VERSION "HNNBNNNYNNNNNNNNNNNNNNNNNNNNNNNNNNNNNNNNNN/4/%%%/4/'%**4NNN///"

NS_ :

BS_:

BU_: BAP_Tester CGS Gateway Gateway_PAG HUD Kombi Kombi_LB Kombi_PAG Waehlhebel_SB

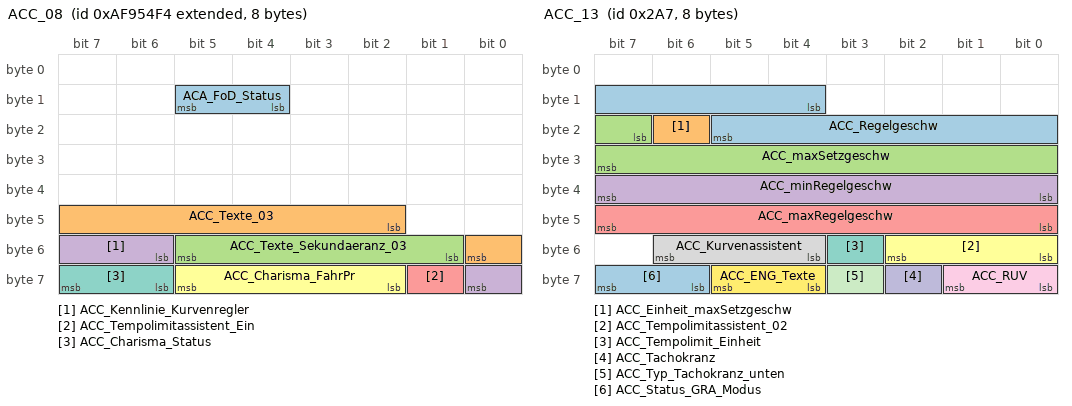
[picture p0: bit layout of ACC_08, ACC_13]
BO_ 2331596020 ACC_08: 8 Gateway
 SG_ ACA_FoD_Status : 12|2@1+ (1.0,0.0) [0.0|3] ""  Vector__XXX
 SG_ ACC_Texte_03 : 42|7@1+ (1.0,0.0) [0.0|127] ""  Kombi,Kombi_LB
 SG_ ACC_Texte_Sekundaeranz_03 : 49|5@1+ (1.0,0.0) [0.0|31] ""  Kombi,Kombi_LB
 SG_ ACC_Kennlinie_Kurvenregler : 54|3@1+ (1.0,0.0) [0.0|7] ""  Vector__XXX
 SG_ ACC_Tempolimitassistent_Ein : 57|1@1+ (1.0,0.0) [0.0|1] ""  Vector__XXX
 SG_ ACC_Charisma_FahrPr : 58|4@1+ (1.0,0.0) [0.0|15] ""  Vector__XXX
 SG_ ACC_Charisma_Status : 62|2@1+ (1.0,0.0) [0.0|3] ""  Vector__XXX

BO_ 678 ACC_12: 8 Gateway
 SG_ ACC_Tempolimit : 0|5@1+ (1.0,0.0) [0.0|31] ""  HUD,Kombi,Kombi_LB,Kombi_PAG
 SG_ ACC_Wunschgeschw_Farbe : 5|1@1+ (1.0,0.0) [0.0|1] ""  Kombi,Kombi_LB,Kombi_PAG
 SG_ ACC_Warnung_Verkehrszeichen_1 : 6|1@1+ (1.0,0.0) [0.0|1] ""  HUD,Kombi,Kombi_LB,Kombi_PAG
 SG_ ACA_Querfuehrung : 7|2@1+ (1.0,0.0) [0.0|3] ""  HUD,Kombi,Kombi_LB,Kombi_PAG
 SG_ ACC_Regelung_AIO : 11|1@1+ (1.0,0.0) [0.0|1] ""  HUD,Kombi,Kombi_LB
 SG_ ACC_Wunschgeschw_02 : 12|10@1+ (0.32,0) [0.00|327.04] "Unit_KiloMeterPerHour"  HUD,Kombi,Kombi_LB,Kombi_PAG
 SG_ ACC_Abstandsindex_02 : 22|10@1+ (1,0) [1|1021] ""  HUD,Kombi,Kombi_LB,Kombi_PAG
 SG_ ACC_Display_Prio : 32|2@1+ (1.0,0.0) [0.0|3] ""  Kombi,Kombi_LB,Kombi_PAG
 SG_ ACC_rel_Objekt_Zusatzanz : 34|2@1+ (1.0,0.0) [0.0|3] ""  Kombi,Kombi_LB,Kombi_PAG
 SG_ ACC_Gesetzte_Zeitluecke : 37|3@1+ (1.0,0.0) [0.0|7] ""  HUD,Kombi,Kombi_LB,Kombi_PAG
 SG_ ACC_Optischer_Fahrerhinweis : 40|1@1+ (1.0,0.0) [0.0|1] ""  HUD,Kombi,Kombi_LB,Kombi_PAG
 SG_ ACC_Warnhinweis : 41|1@1+ (1.0,0.0) [0.0|1] ""  HUD,Kombi,Kombi_LB
 SG_ ACC_EGO_Fahrzeug : 42|3@1+ (1.0,0.0) [0.0|7] ""  HUD,Kombi,Kombi_LB,Kombi_PAG
 SG_ ACC_Relevantes_Objekt_02 : 45|2@1+ (1.0,0.0) [0.0|3] ""  HUD,Kombi,Kombi_LB,Kombi_PAG
 SG_ ACC_Wunschgeschw_erreicht : 48|1@1+ (1.0,0.0) [0.0|1] ""  HUD,Kombi,Kombi_LB,Kombi_PAG
 SG_ ACC_Anzeige_Zeitluecke : 49|1@1+ (1.0,0.0) [0.0|1] ""  HUD,Kombi,Kombi_LB,Kombi_PAG
 SG_ ACC_Texte_Primaeranz_02 : 50|6@1+ (1.0,0.0) [0.0|63] ""  HUD,Kombi,Kombi_LB,Kombi_PAG
 SG_ ACC_Texte_Zusatzanz_02 : 56|6@1+ (1.0,0.0) [0.0|63] ""  HUD,Kombi,Kombi_LB,Kombi_PAG
 SG_ STA_Primaeranz : 62|2@1+ (1.0,0.0) [0.0|3] ""  HUD,Kombi,Kombi_LB,Kombi_PAG

BO_ 679 ACC_13: 8 Gateway
 SG_ ACC_Regelgeschw : 12|10@1+ (0.32,0) [0.00|327.04] "Unit_KiloMeterPerHour"  HUD,Kombi,Kombi_LB,Kombi_PAG
 SG_ ACC_Einheit_maxSetzgeschw : 22|1@1+ (1.0,0.0) [0.0|1] ""  Kombi,Kombi_LB,Kombi_PAG
 SG_ ACC_maxSetzgeschw : 23|9@1+ (1,0) [0|510] ""  Kombi,Kombi_LB,Kombi_PAG
 SG_ ACC_minRegelgeschw : 32|8@1+ (0.32,0) [0.00|81.28] "Unit_KiloMeterPerHour"  Kombi,Kombi_LB,Kombi_PAG
 SG_ ACC_maxRegelgeschw : 40|8@1+ (0.32,0) [0.00|81.28] "Unit_KiloMeterPerHour"  Kombi,Kombi_LB,Kombi_PAG
 SG_ ACC_Tempolimitassistent_02 : 48|3@1+ (1.0,0.0) [0.0|7] ""  HUD,Kombi,Kombi_LB,Kombi_PAG
 SG_ ACC_Tempolimit_Einheit : 51|1@1+ (1.0,0.0) [0.0|1] ""  HUD,Kombi,Kombi_LB
 SG_ ACC_Kurvenassistent : 52|3@1+ (1.0,0.0) [0.0|7] ""  HUD,Kombi,Kombi_LB,Kombi_PAG
 SG_ ACC_RUV : 56|2@1+ (1.0,0.0) [0.0|3] ""  HUD,Kombi,Kombi_LB,Kombi_PAG
 SG_ ACC_Tachokranz : 58|1@1+ (1.0,0.0) [0.0|1] ""  Kombi,Kombi_LB,Kombi_PAG
 SG_ ACC_Typ_Tachokranz_unten : 59|1@1+ (1.0,0.0) [0.0|1] ""  Kombi,Kombi_LB,Kombi_PAG
 SG_ ACC_ENG_Texte : 60|2@1+ (1.0,0.0) [0.0|3] ""  Kombi,Kombi_LB,Kombi_PAG
 SG_ ACC_Status_GRA_Modus : 62|2@1+ (1.0,0.0) [0.0|3] ""  Vector__XXX

BO_ 680 ACC_14: 8 Gateway
 SG_ ACA_Querfuehrung_Texte : 0|3@1+ (1.0,0.0) [0.0|7] ""  HUD,Kombi,Kombi_LB,Kombi_PAG
 SG_ ACA_Hinweistexte : 3|3@1+ (1.0,0.0) [0.0|7] ""  Kombi,Kombi_LB,Kombi_PAG
 SG_ ACC_FoD_Status : 6|2@1+ (1.0,0.0) [0.0|3] ""  Vector__XXX
 SG_ ACC_Texte_Abstandswarner : 8|2@1+ (1.0,0.0) [0.0|3] ""  Kombi,Kombi_LB,Kombi_PAG
 SG_ ACC_Vorz_Abstandswarner : 10|2@1+ (1.0,0.0) [0.0|3] ""  Kombi,Kombi_LB,Kombi_PAG
 SG_ ACC_Texte_Sekundaeranz : 12|4@1+ (1.0,0.0) [0.0|15] ""  Kombi,Kombi_LB,Kombi_PAG
 SG_ ACC_Status_Anzeige : 16|3@1+ (1.0,0.0) [0.0|7] ""  HUD,Kombi,Kombi_LB,Kombi_PAG
 SG_ ACC_Akustik_03 : 19|3@1+ (1.0,0.0) [0.0|7] ""  Kombi,Kombi_LB,Kombi_PAG
 SG_ ACC_Geschw_Zielfahrzeug : 22|10@1+ (0.32,0) [0.00|326.72] "Unit_KiloMeterPerHour"  Kombi,Kombi_LB,Kombi_PAG
 SG_ ACC_Texte : 32|5@1+ (1.0,0.0) [0.0|31] ""  Kombi,Kombi_LB,Kombi_PAG
 SG_ ACC_STA_Text : 38|1@1+ (1.0,0.0) [0.0|1] ""  Kombi,Kombi_LB,Kombi_PAG
 SG_ STA_Texte : 40|3@1+ (1.0,0.0) [0.0|7] ""  HUD,Kombi,Kombi_LB,Kombi_PAG
 SG_ AbstWarn_LRR_FAS_Fkt_Status : 43|2@1+ (1.0,0.0) [0.0|3] ""  Vector__XXX
 SG_ STA_Zusatzanz : 45|2@1+ (1.0,0.0) [0.0|3] ""  Kombi,Kombi_LB,Kombi_PAG
 SG_ FAS_Licht_Anf : 47|1@1+ (1.0,0.0) [0.0|1] ""  Vector__XXX
 SG_ ACC_Zeitluecke_Abstandswarner : 48|6@1+ (0.1,0) [0.0|6.0] "Unit_Secon"  Kombi,Kombi_LB,Kombi_PAG
 SG_ ACC_Abstand_Abstandswarner : 54|9@1+ (1,0) [0|508] ""  Kombi,Kombi_LB,Kombi_PAG
 SG_ ACC_Einheit_Abstandswarner : 63|1@1+ (1.0,0.0) [0.0|1] ""  Kombi,Kombi_LB,Kombi_PAG

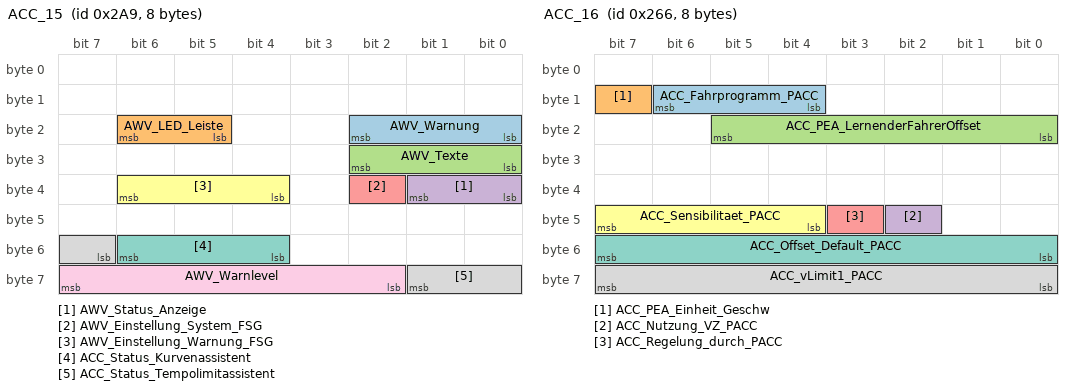
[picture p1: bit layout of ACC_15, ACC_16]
BO_ 681 ACC_15: 8 Gateway
 SG_ AWV_Warnung : 16|3@1+ (1.0,0.0) [0.0|7] ""  HUD,Kombi,Kombi_LB,Kombi_PAG
 SG_ AWV_LED_Leiste : 21|2@1+ (1.0,0.0) [0.0|3] ""  HUD,Kombi,Kombi_LB,Kombi_PAG
 SG_ AWV_Texte : 24|3@1+ (1.0,0.0) [0.0|7] ""  Kombi,Kombi_LB,Kombi_PAG
 SG_ AWV_Status_Anzeige : 32|2@1+ (1.0,0.0) [0.0|3] ""  Vector__XXX
 SG_ AWV_Einstellung_System_FSG : 34|1@1+ (1.0,0.0) [0.0|1] ""  Vector__XXX
 SG_ AWV_Einstellung_Warnung_FSG : 36|3@1+ (1.0,0.0) [0.0|7] ""  Vector__XXX
 SG_ ACC_Status_Kurvenassistent : 52|3@1+ (1.0,0.0) [0.0|7] ""  Vector__XXX
 SG_ ACC_Status_Tempolimitassistent : 55|3@1+ (1.0,0.0) [0.0|7] ""  Vector__XXX
 SG_ AWV_Warnlevel : 58|6@1+ (1.0,0.0) [0.0|63] ""  Vector__XXX

BO_ 614 ACC_16: 8 Gateway
 SG_ ACC_Fahrprogramm_PACC : 12|3@1+ (1.0,0.0) [0.0|7] ""  Vector__XXX
 SG_ ACC_PEA_Einheit_Geschw : 15|1@1+ (1.0,0.0) [0.0|1] ""  Vector__XXX
 SG_ ACC_PEA_LernenderFahrerOffset : 16|6@1+ (1,-31) [-30|31] ""  Vector__XXX
 SG_ ACC_Nutzung_VZ_PACC : 42|1@1+ (1.0,0.0) [0.0|1] ""  HUD
 SG_ ACC_Regelung_durch_PACC : 43|1@1+ (1.0,0.0) [0.0|1] ""  Vector__XXX
 SG_ ACC_Sensibilitaet_PACC : 44|4@1+ (1.0,0.0) [0.0|15] ""  Vector__XXX
 SG_ ACC_Offset_Default_PACC : 48|8@1+ (1,-127) [-127|128] "Unit_KiloMeterPerHour"  Vector__XXX
 SG_ ACC_vLimit1_PACC : 56|8@1+ (1,0) [0|255] "Unit_KiloMeterPerHour"  Vector__XXX

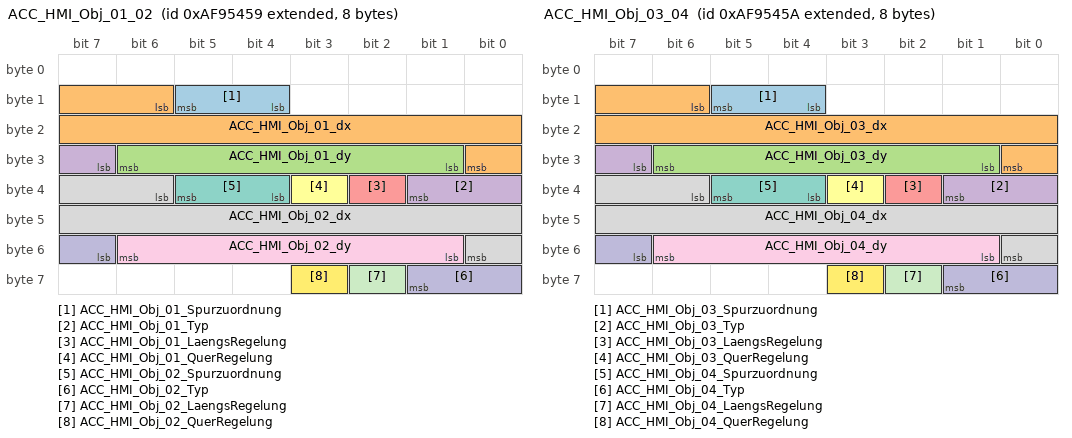
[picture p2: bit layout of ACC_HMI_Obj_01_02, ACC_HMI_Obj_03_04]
BO_ 2331595865 ACC_HMI_Obj_01_02: 8 Gateway
 SG_ ACC_HMI_Obj_01_Spurzuordnung : 12|2@1+ (1.0,0.0) [0.0|3] ""  HUD,Kombi,Kombi_PAG
 SG_ ACC_HMI_Obj_01_dx : 14|11@1+ (0.15,-100.05) [-100.05|207.00] "Unit_Meter"  HUD,Kombi,Kombi_PAG
 SG_ ACC_HMI_Obj_01_dy : 25|6@1+ (0.015873,0) [0.000000|0.999999] "Unit_PerCent"  Kombi,Kombi_PAG
 SG_ ACC_HMI_Obj_01_Typ : 31|3@1+ (1.0,0.0) [0.0|7] ""  HUD,Kombi,Kombi_PAG
 SG_ ACC_HMI_Obj_01_LaengsRegelung : 34|1@1+ (1.0,0.0) [0.0|1] ""  Kombi,Kombi_PAG
 SG_ ACC_HMI_Obj_01_QuerRegelung : 35|1@1+ (1.0,0.0) [0.0|1] ""  Kombi,Kombi_PAG
 SG_ ACC_HMI_Obj_02_Spurzuordnung : 36|2@1+ (1.0,0.0) [0.0|3] ""  HUD,Kombi,Kombi_PAG
 SG_ ACC_HMI_Obj_02_dx : 38|11@1+ (0.15,-100.05) [-100.05|207.00] "Unit_Meter"  HUD,Kombi,Kombi_PAG
 SG_ ACC_HMI_Obj_02_dy : 49|6@1+ (0.015873,0) [0.000000|0.999999] "Unit_PerCent"  Kombi,Kombi_PAG
 SG_ ACC_HMI_Obj_02_Typ : 55|3@1+ (1.0,0.0) [0.0|7] ""  HUD,Kombi,Kombi_PAG
 SG_ ACC_HMI_Obj_02_LaengsRegelung : 58|1@1+ (1.0,0.0) [0.0|1] ""  Kombi,Kombi_PAG
 SG_ ACC_HMI_Obj_02_QuerRegelung : 59|1@1+ (1.0,0.0) [0.0|1] ""  Kombi,Kombi_PAG

BO_ 2331595866 ACC_HMI_Obj_03_04: 8 Gateway
 SG_ ACC_HMI_Obj_03_Spurzuordnung : 12|2@1+ (1.0,0.0) [0.0|3] ""  HUD,Kombi,Kombi_PAG
 SG_ ACC_HMI_Obj_03_dx : 14|11@1+ (0.15,-100.05) [-100.05|207.00] "Unit_Meter"  HUD,Kombi,Kombi_PAG
 SG_ ACC_HMI_Obj_03_dy : 25|6@1+ (0.015873,0) [0.000000|0.999999] "Unit_PerCent"  Kombi,Kombi_PAG
 SG_ ACC_HMI_Obj_03_Typ : 31|3@1+ (1.0,0.0) [0.0|7] ""  HUD,Kombi,Kombi_PAG
 SG_ ACC_HMI_Obj_03_LaengsRegelung : 34|1@1+ (1.0,0.0) [0.0|1] ""  Kombi,Kombi_PAG
 SG_ ACC_HMI_Obj_03_QuerRegelung : 35|1@1+ (1.0,0.0) [0.0|1] ""  Kombi,Kombi_PAG
 SG_ ACC_HMI_Obj_04_Spurzuordnung : 36|2@1+ (1.0,0.0) [0.0|3] ""  HUD,Kombi,Kombi_PAG
 SG_ ACC_HMI_Obj_04_dx : 38|11@1+ (0.15,-100.05) [-100.05|207.00] "Unit_Meter"  HUD,Kombi,Kombi_PAG
 SG_ ACC_HMI_Obj_04_dy : 49|6@1+ (0.015873,0) [0.000000|0.999999] "Unit_PerCent"  Kombi,Kombi_PAG
 SG_ ACC_HMI_Obj_04_Typ : 55|3@1+ (1.0,0.0) [0.0|7] ""  HUD,Kombi,Kombi_PAG
 SG_ ACC_HMI_Obj_04_LaengsRegelung : 58|1@1+ (1.0,0.0) [0.0|1] ""  Kombi,Kombi_PAG
 SG_ ACC_HMI_Obj_04_QuerRegelung : 59|1@1+ (1.0,0.0) [0.0|1] ""  Kombi,Kombi_PAG

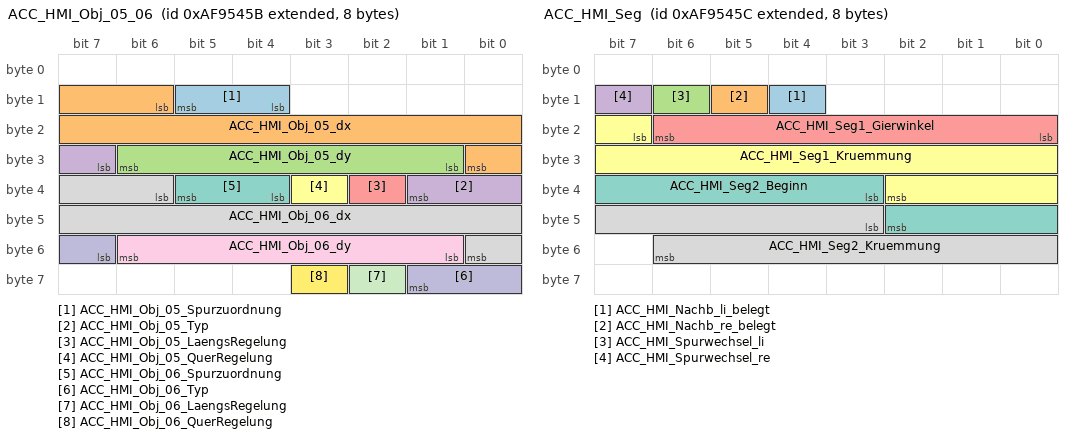
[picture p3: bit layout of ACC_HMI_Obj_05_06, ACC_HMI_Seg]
BO_ 2331595867 ACC_HMI_Obj_05_06: 8 Gateway
 SG_ ACC_HMI_Obj_05_Spurzuordnung : 12|2@1+ (1.0,0.0) [0.0|3] ""  HUD,Kombi,Kombi_PAG
 SG_ ACC_HMI_Obj_05_dx : 14|11@1+ (0.15,-100.05) [-100.05|207.00] "Unit_Meter"  HUD,Kombi,Kombi_PAG
 SG_ ACC_HMI_Obj_05_dy : 25|6@1+ (0.015873,0) [0.000000|0.999999] "Unit_PerCent"  Kombi,Kombi_PAG
 SG_ ACC_HMI_Obj_05_Typ : 31|3@1+ (1.0,0.0) [0.0|7] ""  HUD,Kombi,Kombi_PAG
 SG_ ACC_HMI_Obj_05_LaengsRegelung : 34|1@1+ (1.0,0.0) [0.0|1] ""  Kombi,Kombi_PAG
 SG_ ACC_HMI_Obj_05_QuerRegelung : 35|1@1+ (1.0,0.0) [0.0|1] ""  Kombi,Kombi_PAG
 SG_ ACC_HMI_Obj_06_Spurzuordnung : 36|2@1+ (1.0,0.0) [0.0|3] ""  HUD,Kombi,Kombi_PAG
 SG_ ACC_HMI_Obj_06_dx : 38|11@1+ (0.15,-100.05) [-100.05|207.00] "Unit_Meter"  HUD,Kombi,Kombi_PAG
 SG_ ACC_HMI_Obj_06_dy : 49|6@1+ (0.015873,0) [0.000000|0.999999] "Unit_PerCent"  Kombi,Kombi_PAG
 SG_ ACC_HMI_Obj_06_Typ : 55|3@1+ (1.0,0.0) [0.0|7] ""  HUD,Kombi,Kombi_PAG
 SG_ ACC_HMI_Obj_06_LaengsRegelung : 58|1@1+ (1.0,0.0) [0.0|1] ""  Kombi,Kombi_PAG
 SG_ ACC_HMI_Obj_06_QuerRegelung : 59|1@1+ (1.0,0.0) [0.0|1] ""  Kombi,Kombi_PAG

BO_ 2331595868 ACC_HMI_Seg: 8 Gateway
 SG_ ACC_HMI_Nachb_li_belegt : 12|1@1+ (1.0,0.0) [0.0|1] ""  Kombi,Kombi_PAG
 SG_ ACC_HMI_Nachb_re_belegt : 13|1@1+ (1.0,0.0) [0.0|1] ""  Kombi,Kombi_PAG
 SG_ ACC_HMI_Spurwechsel_li : 14|1@1+ (1.0,0.0) [0.0|1] ""  Kombi,Kombi_PAG
 SG_ ACC_HMI_Spurwechsel_re : 15|1@1+ (1.0,0.0) [0.0|1] ""  Kombi,Kombi_PAG
 SG_ ACC_HMI_Seg1_Gierwinkel : 16|7@1+ (0.015748,-1) [-1.000000|0.999996] "Unit_Radia"  Kombi,Kombi_PAG
 SG_ ACC_HMI_Seg1_Kruemmung : 23|12@1+ (1,-2047) [-2047|2048] "Unit_MeterInver"  Kombi,Kombi_PAG
 SG_ ACC_HMI_Seg2_Beginn : 35|8@1+ (0.58824,0) [0.00000|150.00120] "Unit_Meter"  Kombi,Kombi_PAG
 SG_ ACC_HMI_Seg2_Kruemmung : 43|12@1+ (1,-2047) [-2047|2048] "Unit_MeterInver"  Kombi,Kombi_PAG

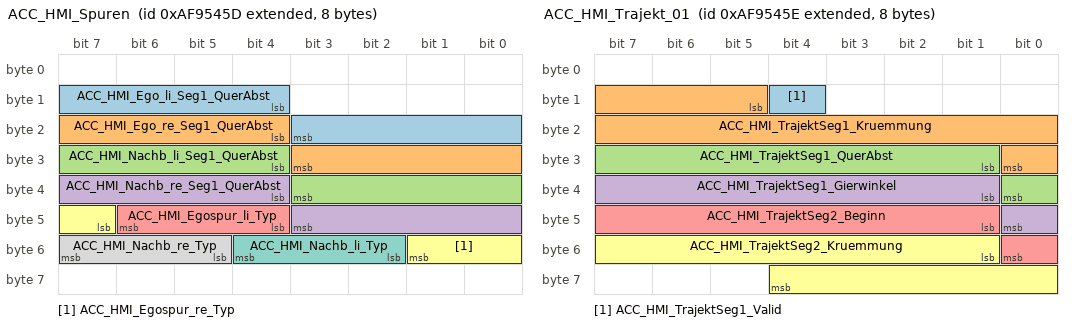
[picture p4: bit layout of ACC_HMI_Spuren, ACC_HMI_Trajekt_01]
BO_ 2331595869 ACC_HMI_Spuren: 8 Gateway
 SG_ ACC_HMI_Ego_li_Seg1_QuerAbst : 12|8@1+ (0.062745,-8) [-8.000000|7.999975] "Unit_Meter"  Kombi,Kombi_PAG
 SG_ ACC_HMI_Ego_re_Seg1_QuerAbst : 20|8@1+ (0.062745,-8) [-8.000000|7.999975] "Unit_Meter"  Kombi,Kombi_PAG
 SG_ ACC_HMI_Nachb_li_Seg1_QuerAbst : 28|8@1+ (0.062745,-8) [-8.000000|7.999975] "Unit_Meter"  Kombi,Kombi_PAG
 SG_ ACC_HMI_Nachb_re_Seg1_QuerAbst : 36|8@1+ (0.062745,-8) [-8.000000|7.999975] "Unit_Meter"  Kombi,Kombi_PAG
 SG_ ACC_HMI_Egospur_li_Typ : 44|3@1+ (1.0,0.0) [0.0|7] ""  Kombi,Kombi_PAG
 SG_ ACC_HMI_Egospur_re_Typ : 47|3@1+ (1.0,0.0) [0.0|7] ""  Kombi,Kombi_PAG
 SG_ ACC_HMI_Nachb_li_Typ : 50|3@1+ (1.0,0.0) [0.0|7] ""  Kombi,Kombi_PAG
 SG_ ACC_HMI_Nachb_re_Typ : 53|3@1+ (1.0,0.0) [0.0|7] ""  Kombi,Kombi_PAG

BO_ 2331595870 ACC_HMI_Trajekt_01: 8 Gateway
 SG_ ACC_HMI_TrajektSeg1_Valid : 12|1@1+ (1.0,0.0) [0.0|1] ""  Kombi,Kombi_PAG
 SG_ ACC_HMI_TrajektSeg1_Kruemmung : 13|12@1+ (1,-2047) [-2047|2048] "Unit_MeterInver"  Kombi,Kombi_PAG
 SG_ ACC_HMI_TrajektSeg1_QuerAbst : 25|8@1+ (0.062745,-8) [-8.000000|7.999975] "Unit_Meter"  Kombi,Kombi_PAG
 SG_ ACC_HMI_TrajektSeg1_Gierwinkel : 33|8@1+ (0.007843,-1) [-1.000000|0.999965] "Unit_Radia"  Kombi,Kombi_PAG
 SG_ ACC_HMI_TrajektSeg2_Beginn : 41|8@1+ (0.58824,0) [0.00000|150.00120] "Unit_Meter"  Kombi,Kombi_PAG
 SG_ ACC_HMI_TrajektSeg2_Kruemmung : 49|12@1+ (1,-2047) [-2047|2048] "Unit_MeterInver"  Kombi,Kombi_PAG

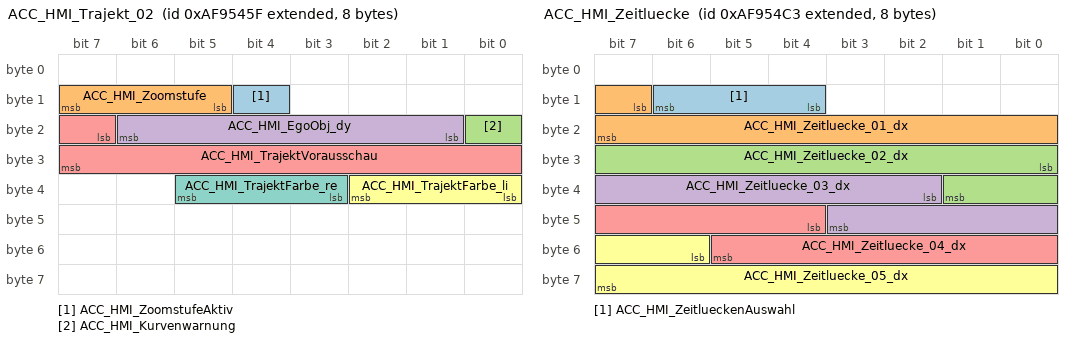
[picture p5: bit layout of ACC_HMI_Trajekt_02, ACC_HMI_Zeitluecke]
BO_ 2331595871 ACC_HMI_Trajekt_02: 8 Gateway
 SG_ ACC_HMI_ZoomstufeAktiv : 12|1@1+ (1.0,0.0) [0.0|1] ""  Kombi,Kombi_PAG
 SG_ ACC_HMI_Zoomstufe : 13|3@1+ (1,0) [0|7] "Unit_Meter"  Kombi,Kombi_PAG
 SG_ ACC_HMI_Kurvenwarnung : 16|1@1+ (1.0,0.0) [0.0|1] ""  Kombi,Kombi_PAG
 SG_ ACC_HMI_EgoObj_dy : 17|6@1+ (0.015873,0) [0.000000|0.999999] "Unit_PerCent"  Kombi,Kombi_PAG
 SG_ ACC_HMI_TrajektVorausschau : 23|9@1+ (0.58824,0) [0.00000|300.59064] "Unit_Meter"  Kombi,Kombi_PAG
 SG_ ACC_HMI_TrajektFarbe_li : 32|3@1+ (1.0,0.0) [0.0|7] ""  Kombi,Kombi_PAG
 SG_ ACC_HMI_TrajektFarbe_re : 35|3@1+ (1.0,0.0) [0.0|7] ""  Kombi,Kombi_PAG

BO_ 2331595971 ACC_HMI_Zeitluecke: 8 Gateway
 SG_ ACC_HMI_ZeitlueckenAuswahl : 12|3@1+ (1.0,0.0) [0.0|7] ""  Kombi,Kombi_PAG
 SG_ ACC_HMI_Zeitluecke_01_dx : 15|9@1+ (0.15,0) [0.00|76.65] "Unit_Meter"  Kombi,Kombi_PAG
 SG_ ACC_HMI_Zeitluecke_02_dx : 24|10@1+ (0.15,0) [0.00|153.45] "Unit_Meter"  Kombi,Kombi_PAG
 SG_ ACC_HMI_Zeitluecke_03_dx : 34|10@1+ (0.15,0) [0.00|153.45] "Unit_Meter"  Kombi,Kombi_PAG
 SG_ ACC_HMI_Zeitluecke_04_dx : 44|10@1+ (0.15,0) [0.00|153.45] "Unit_Meter"  Kombi,Kombi_PAG
 SG_ ACC_HMI_Zeitluecke_05_dx : 54|10@1+ (0.15,0) [0.00|153.45] "Unit_Meter"  Kombi,Kombi_PAG

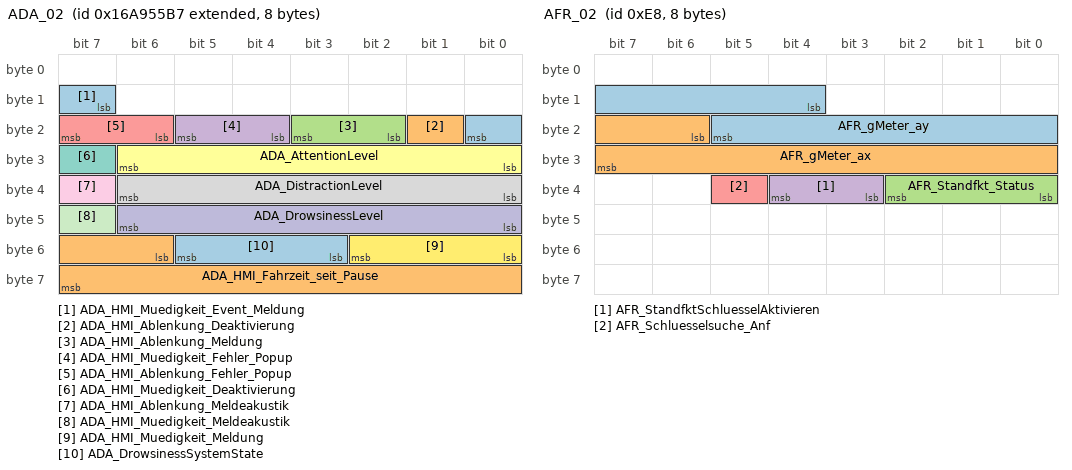
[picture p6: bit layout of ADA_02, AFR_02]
BO_ 2527679927 ADA_02: 8 Gateway
 SG_ ADA_HMI_Muedigkeit_Event_Meldung : 15|2@1+ (1.0,0.0) [0.0|3] ""  Kombi,Kombi_LB
 SG_ ADA_HMI_Ablenkung_Deaktivierung : 17|1@1+ (1.0,0.0) [0.0|1] ""  Kombi,Kombi_LB,Kombi_PAG
 SG_ ADA_HMI_Ablenkung_Meldung : 18|2@1+ (1.0,0.0) [0.0|3] ""  Kombi,Kombi_LB,Kombi_PAG
 SG_ ADA_HMI_Muedigkeit_Fehler_Popup : 20|2@1+ (1.0,0.0) [0.0|3] ""  Kombi,Kombi_LB,Kombi_PAG
 SG_ ADA_HMI_Ablenkung_Fehler_Popup : 22|2@1+ (1.0,0.0) [0.0|3] ""  Kombi,Kombi_LB,Kombi_PAG
 SG_ ADA_AttentionLevel : 24|7@1+ (0.01,0) [0.00|1.00] "Unit_None"  Vector__XXX
 SG_ ADA_HMI_Muedigkeit_Deaktivierung : 31|1@1+ (1.0,0.0) [0.0|1] ""  Kombi,Kombi_LB,Kombi_PAG
 SG_ ADA_DistractionLevel : 32|7@1+ (0.01,0) [0.00|1.00] "Unit_None"  Vector__XXX
 SG_ ADA_HMI_Ablenkung_Meldeakustik : 39|1@1+ (1.0,0.0) [0.0|1] ""  Kombi,Kombi_LB,Kombi_PAG
 SG_ ADA_DrowsinessLevel : 40|7@1+ (0.01,0) [0.00|1.00] "Unit_None"  Vector__XXX
 SG_ ADA_HMI_Muedigkeit_Meldeakustik : 47|1@1+ (1.0,0.0) [0.0|1] ""  Kombi,Kombi_LB,Kombi_PAG
 SG_ ADA_HMI_Muedigkeit_Meldung : 48|3@1+ (1.0,0.0) [0.0|7] ""  Kombi,Kombi_LB,Kombi_PAG
 SG_ ADA_DrowsinessSystemState : 51|3@1+ (1.0,0.0) [0.0|7] ""  Kombi,Kombi_LB,Kombi_PAG
 SG_ ADA_HMI_Fahrzeit_seit_Pause : 54|10@1+ (1,0) [0|1022] "Unit_Minut"  Kombi,Kombi_LB,Kombi_PAG

BO_ 232 AFR_02: 8 Gateway
 SG_ AFR_gMeter_ay : 12|10@1+ (0.003,-1.5) [-1.500|1.563] "Unit_ForceOfGravi"  Kombi,Kombi_LB
 SG_ AFR_gMeter_ax : 22|10@1+ (0.003,-1.5) [-1.500|1.563] "Unit_ForceOfGravi"  Kombi,Kombi_LB
 SG_ AFR_Standfkt_Status : 32|3@1+ (1.0,0.0) [0.0|7] ""  Vector__XXX
 SG_ AFR_StandfktSchluesselAktivieren : 35|2@1+ (1.0,0.0) [0.0|3] ""  Vector__XXX
 SG_ AFR_Schluesselsuche_Anf : 37|1@1+ (1.0,0.0) [0.0|1] ""  Vector__XXX

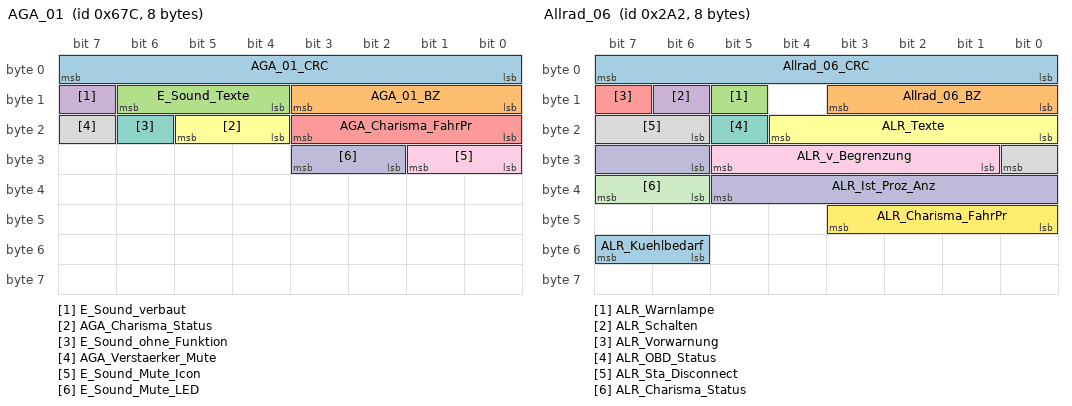
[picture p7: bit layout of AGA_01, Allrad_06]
BO_ 1660 AGA_01: 8 Gateway
 SG_ AGA_01_CRC : 0|8@1+ (1,0) [0|255] ""  Vector__XXX
 SG_ AGA_01_BZ : 8|4@1+ (1,0) [0|15] ""  Vector__XXX
 SG_ E_Sound_Texte : 12|3@1+ (1.0,0.0) [0.0|7] ""  Kombi,Kombi_LB,Kombi_PAG
 SG_ E_Sound_verbaut : 15|1@1+ (1.0,0.0) [0.0|1] ""  Kombi,Kombi_LB,Kombi_PAG
 SG_ AGA_Charisma_FahrPr : 16|4@1+ (1.0,0.0) [0.0|15] ""  Vector__XXX
 SG_ AGA_Charisma_Status : 20|2@1+ (1.0,0.0) [0.0|3] ""  Vector__XXX
 SG_ E_Sound_ohne_Funktion : 22|1@1+ (1.0,0.0) [0.0|1] ""  Kombi_PAG
 SG_ AGA_Verstaerker_Mute : 23|1@1+ (1.0,0.0) [0.0|1] ""  Vector__XXX
 SG_ E_Sound_Mute_Icon : 24|2@1+ (1.0,0.0) [0.0|3] ""  Kombi,Kombi_LB,Kombi_PAG
 SG_ E_Sound_Mute_LED : 26|2@1+ (1.0,0.0) [0.0|3] ""  Vector__XXX

BO_ 64 Airbag_01: 8 Gateway
 SG_ Airbag_01_CRC : 0|8@1+ (1,0) [0|255] ""  Kombi,Kombi_LB,Kombi_PAG
 SG_ Airbag_01_BZ : 8|4@1+ (1,0) [0|15] ""  Kombi,Kombi_LB,Kombi_PAG
 SG_ AB_RGS_Anst : 12|4@1+ (1.0,0.0) [0.0|15] ""  Vector__XXX
 SG_ AB_Front_Crash : 16|1@1+ (1.0,0.0) [0.0|1] ""  Vector__XXX
 SG_ AB_Heck_Crash : 17|1@1+ (1.0,0.0) [0.0|1] ""  Vector__XXX
 SG_ AB_SF_Crash : 18|1@1+ (1.0,0.0) [0.0|1] ""  Vector__XXX
 SG_ AB_SB_Crash : 19|1@1+ (1.0,0.0) [0.0|1] ""  Vector__XXX
 SG_ AB_Rollover_Crash : 20|1@1+ (1.0,0.0) [0.0|1] ""  Vector__XXX
 SG_ AB_Crash_Int : 21|3@1+ (1.0,0.0) [0.0|7] ""  Vector__XXX
 SG_ AB_Lampe : 24|1@1+ (1.0,0.0) [0.0|1] ""  Kombi,Kombi_LB,Kombi_PAG
 SG_ AB_Deaktiviert : 25|1@1+ (1.0,0.0) [0.0|1] ""  Kombi,Kombi_LB
 SG_ AB_VB_deaktiviert : 26|1@1+ (1.0,0.0) [0.0|1] ""  Kombi,Kombi_LB,Kombi_PAG
 SG_ AB_Systemfehler : 27|1@1+ (1.0,0.0) [0.0|1] ""  Kombi,Kombi_LB,Kombi_PAG
 SG_ AB_Diagnose : 28|1@1+ (1.0,0.0) [0.0|1] ""  Vector__XXX
 SG_ AB_Stellgliedtest : 29|1@1+ (1.0,0.0) [0.0|1] ""  Vector__XXX
 SG_ AB_Erh_Auf_VB : 30|2@1+ (1.0,0.0) [0.0|3] ""  Kombi,Kombi_LB,Kombi_PAG
 SG_ AB_Gurtwarn_VF : 32|1@1+ (1.0,0.0) [0.0|1] ""  Kombi,Kombi_LB,Kombi_PAG
 SG_ AB_Gurtwarn_VB : 33|1@1+ (1.0,0.0) [0.0|1] ""  Kombi,Kombi_LB,Kombi_PAG
 SG_ AB_Anzeige_Fussg : 34|2@1+ (1.0,0.0) [0.0|3] ""  Kombi,Kombi_LB,Kombi_PAG
 SG_ AB_Texte_AKS : 36|2@1+ (1.0,0.0) [0.0|3] ""  Kombi,Kombi_LB,Kombi_PAG
 SG_ AB_MKB_gueltig : 39|1@1+ (1.0,0.0) [0.0|1] ""  Vector__XXX
 SG_ AB_MKB_Anforderung : 40|1@1+ (1.0,0.0) [0.0|1] ""  Vector__XXX
 SG_ AB_Versorgungsspannung : 41|1@1+ (1.0,0.0) [0.0|1] ""  Kombi,Kombi_LB,Kombi_PAG
 SG_ AB_Deaktivierung_HV : 42|3@1+ (1.0,0.0) [0.0|7] ""  Vector__XXX
 SG_ AB_EDR_Trigger : 45|2@1+ (1.0,0.0) [0.0|3] ""  Vector__XXX
 SG_ AB_Belegung_VF : 47|2@1+ (1.0,0.0) [0.0|3] ""  Kombi,Kombi_LB
 SG_ SC_Masterzeit_Offset : 53|2@1+ (5.08,0) [0.00|15.24] "Unit_Secon"  Vector__XXX
 SG_ SC_LowSpeedCrashErkannt : 55|2@1+ (1.0,0.0) [0.0|3] ""  Vector__XXX
 SG_ SC_Masterzeit : 57|7@1+ (0.04,0) [0.00|5.04] "Unit_Secon"  Vector__XXX

BO_ 1312 Airbag_02: 8 Gateway
 SG_ Airbag_02_CRC : 0|8@1+ (1,0) [0|255] ""  Vector__XXX
 SG_ Airbag_02_BZ : 8|4@1+ (1,0) [0|15] ""  Vector__XXX
 SG_ LoGeWa_Event_Kombiwarnung : 12|4@1+ (1.0,0.0) [0.0|15] ""  HUD,Kombi,Kombi_LB,Kombi_PAG
 SG_ AB_Anforderung_eCall : 16|1@1+ (1.0,0.0) [0.0|1] ""  Vector__XXX
 SG_ AB_Anprall_Seite_Beifahrer : 17|1@1+ (1.0,0.0) [0.0|1] ""  Vector__XXX
 SG_ AB_Anprall_Rollover : 18|1@1+ (1.0,0.0) [0.0|1] ""  Vector__XXX
 SG_ AB_Anprall_FGS : 19|1@1+ (1.0,0.0) [0.0|1] ""  Vector__XXX
 SG_ AB_Anprall_Front_Beifahrer : 20|1@1+ (1.0,0.0) [0.0|1] ""  Vector__XXX
 SG_ AB_Anprall_Front_Fahrer : 21|1@1+ (1.0,0.0) [0.0|1] ""  Vector__XXX
 SG_ AB_Anprall_Heck_Beifahrer : 22|1@1+ (1.0,0.0) [0.0|1] ""  Vector__XXX
 SG_ AB_Anprall_Heck_Fahrer : 23|1@1+ (1.0,0.0) [0.0|1] ""  Vector__XXX
 SG_ AB_Wickelklappung_Reihe2_MI : 24|2@1+ (1.0,0.0) [0.0|3] ""  Kombi,Kombi_LB,Kombi_PAG
 SG_ AB_Belegung_VB : 26|2@1+ (1.0,0.0) [0.0|3] ""  Vector__XXX
 SG_ AB_Abschaltanf_SIH_BF : 28|1@1+ (1.0,0.0) [0.0|1] ""  Vector__XXX
 SG_ AB_Anprall_Seite_Fahrer : 29|1@1+ (1.0,0.0) [0.0|1] ""  Vector__XXX
 SG_ SC_PAO_Schriftzug_Anf : 30|2@1+ (1.0,0.0) [0.0|3] ""  Vector__XXX
 SG_ SC_PAO_ON_Anf : 32|2@1+ (1.0,0.0) [0.0|3] ""  Vector__XXX
 SG_ SC_PAO_OFF_Anf : 34|2@1+ (1.0,0.0) [0.0|3] ""  Vector__XXX
 SG_ AB_Crashschwere : 36|3@1+ (1.0,0.0) [0.0|7] ""  Vector__XXX
 SG_ AB_Anforderung_USM : 39|1@1+ (1.0,0.0) [0.0|1] ""  Vector__XXX
 SG_ AB_Gurtschloss_FA : 40|2@1+ (1.0,0.0) [0.0|3] ""  Kombi,Kombi_LB,Kombi_PAG
 SG_ AB_Gurtschloss_BF : 42|2@1+ (1.0,0.0) [0.0|3] ""  Kombi,Kombi_LB,Kombi_PAG
 SG_ AB_Gurtschloss_Reihe2_FA : 44|2@1+ (1.0,0.0) [0.0|3] ""  Kombi,Kombi_PAG
 SG_ AB_Gurtschloss_Reihe2_MI : 46|2@1+ (1.0,0.0) [0.0|3] ""  Kombi,Kombi_PAG
 SG_ AB_Gurtschloss_Reihe2_BF : 48|2@1+ (1.0,0.0) [0.0|3] ""  Kombi,Kombi_PAG
 SG_ AB_Gurtschloss_Reihe3_FA : 50|2@1+ (1.0,0.0) [0.0|3] ""  Kombi,Kombi_PAG
 SG_ AB_Gurtschloss_Reihe3_MI : 52|2@1+ (1.0,0.0) [0.0|3] ""  Kombi,Kombi_PAG
 SG_ AB_Gurtschloss_Reihe3_BF : 54|2@1+ (1.0,0.0) [0.0|3] ""  Kombi,Kombi_PAG
 SG_ AB_Sitzpos_Sens_FA : 56|2@1+ (1.0,0.0) [0.0|3] ""  Vector__XXX
 SG_ AB_Sitzpos_Sens_BF : 58|2@1+ (1.0,0.0) [0.0|3] ""  Vector__XXX
 SG_ AB_Wickelklappung_Reihe2_BF : 60|2@1+ (1.0,0.0) [0.0|3] ""  Kombi,Kombi_LB,Kombi_PAG
 SG_ AB_Wickelklappung_Reihe2_FA : 62|2@1+ (1.0,0.0) [0.0|3] ""  Kombi,Kombi_LB,Kombi_PAG

BO_ 1349 Airbag_04: 8 Gateway
 SG_ AB_Gurtwarn_Reihe2_FA : 20|2@1+ (1.0,0.0) [0.0|3] ""  Kombi
 SG_ AB_Gurtwarn_Reihe2_BF : 22|2@1+ (1.0,0.0) [0.0|3] ""  Kombi
 SG_ AbstWarn_MV_FAS_Fkt_Status : 24|2@1+ (1.0,0.0) [0.0|3] ""  Vector__XXX
 SG_ WarnBrems_Charisma_Status : 26|2@1+ (1.0,0.0) [0.0|3] ""  Vector__XXX
 SG_ WarnBrems_Charisma_FahrPr : 28|4@1+ (1.0,0.0) [0.0|15] ""  Vector__XXX
 SG_ AB_Gurtwarn_Reihe2_MI : 32|2@1+ (1.0,0.0) [0.0|3] ""  Kombi
 SG_ AB_Gurtwarn_Reihe3_FA : 34|2@1+ (1.0,0.0) [0.0|3] ""  Kombi
 SG_ AB_Gurtwarn_Reihe3_MI : 36|2@1+ (1.0,0.0) [0.0|3] ""  Kombi
 SG_ AB_Gurtwarn_Reihe3_BF : 38|2@1+ (1.0,0.0) [0.0|3] ""  Kombi
 SG_ LGI_FAS_Fkt_Status : 40|2@1+ (1.0,0.0) [0.0|3] ""  Vector__XXX
 SG_ PreCrash_FAS_Fkt_Status : 42|3@1+ (1.0,0.0) [0.0|7] ""  Vector__XXX
 SG_ AB_SBR_hinten_verbau : 48|2@1+ (1.0,0.0) [0.0|3] ""  Kombi,Kombi_LB
 SG_ AWV_Einstellung_System_ASG : 51|1@1+ (1.0,0.0) [0.0|1] ""  Vector__XXX
 SG_ AWV_Einstellung_Warnung_ASG : 52|3@1+ (1.0,0.0) [0.0|7] ""  Vector__XXX
 SG_ SC_PreSense_Modus_Warnung_NV : 55|3@1+ (1.0,0.0) [0.0|7] ""  Vector__XXX
 SG_ SC_PreSense_Modus_Warnung_MV : 58|3@1+ (1.0,0.0) [0.0|7] ""  Vector__XXX
 SG_ SC_PreSense_Modus_System_MV : 61|1@1+ (1.0,0.0) [0.0|1] ""  Vector__XXX
 SG_ SC_PreSense_Modus_System_NV : 62|1@1+ (1.0,0.0) [0.0|1] ""  Vector__XXX
 SG_ SC_PreSense_Modus_System_KAS : 63|1@1+ (1.0,0.0) [0.0|1] ""  Vector__XXX

BO_ 674 Allrad_06: 8 Gateway
 SG_ Allrad_06_CRC : 0|8@1+ (1,0) [0|255] ""  Kombi,Kombi_LB,Kombi_PAG
 SG_ Allrad_06_BZ : 8|4@1+ (1,0) [0|15] ""  Kombi,Kombi_LB,Kombi_PAG
 SG_ ALR_Warnlampe : 13|1@1+ (1.0,0.0) [0.0|1] ""  Kombi,Kombi_LB,Kombi_PAG
 SG_ ALR_Schalten : 14|1@1+ (1.0,0.0) [0.0|1] ""  Vector__XXX
 SG_ ALR_Vorwarnung : 15|1@1+ (1.0,0.0) [0.0|1] ""  Vector__XXX
 SG_ ALR_Texte : 16|5@1+ (1.0,0.0) [0.0|31] ""  Kombi,Kombi_LB,Kombi_PAG
 SG_ ALR_OBD_Status : 21|1@1+ (1.0,0.0) [0.0|1] ""  Vector__XXX
 SG_ ALR_Sta_Disconnect : 22|3@1+ (1.0,0.0) [0.0|7] ""  Vector__XXX
 SG_ ALR_v_Begrenzung : 25|5@1+ (10,10) [10|310] ""  Vector__XXX
 SG_ ALR_Ist_Proz_Anz : 30|8@1+ (0.4,0) [0.0|100.0] "Unit_PerCent"  Vector__XXX
 SG_ ALR_Charisma_Status : 38|2@1+ (1.0,0.0) [0.0|3] ""  Vector__XXX
 SG_ ALR_Charisma_FahrPr : 40|4@1+ (1.0,0.0) [0.0|15] ""  Vector__XXX
 SG_ ALR_Kuehlbedarf : 54|2@1+ (1.0,0.0) [0.0|3] ""  Vector__XXX

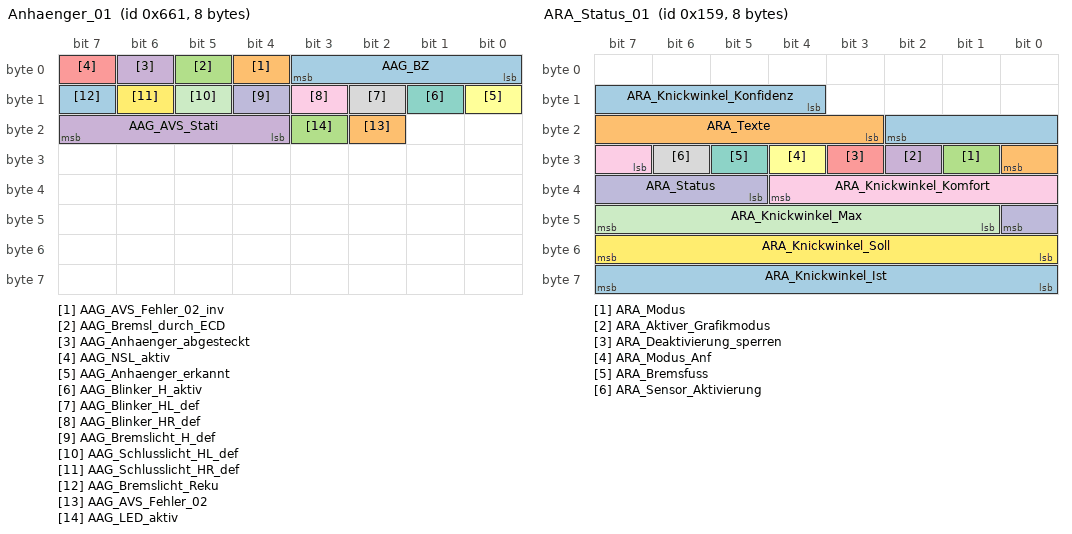
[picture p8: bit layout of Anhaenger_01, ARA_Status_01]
BO_ 1633 Anhaenger_01: 8 Gateway
 SG_ AAG_BZ : 0|4@1+ (1,0) [0|15] ""  Kombi,Kombi_PAG
 SG_ AAG_AVS_Fehler_02_inv : 4|1@1+ (1.0,0.0) [0.0|1] ""  Kombi,Kombi_PAG
 SG_ AAG_Bremsl_durch_ECD : 5|1@1+ (1.0,0.0) [0.0|1] ""  Vector__XXX
 SG_ AAG_Anhaenger_abgesteckt : 6|1@1+ (1.0,0.0) [0.0|1] ""  Vector__XXX
 SG_ AAG_NSL_aktiv : 7|1@1+ (1.0,0.0) [0.0|1] ""  Vector__XXX
 SG_ AAG_Anhaenger_erkannt : 8|1@1+ (1.0,0.0) [0.0|1] ""  Vector__XXX
 SG_ AAG_Blinker_H_aktiv : 9|1@1+ (1.0,0.0) [0.0|1] ""  Kombi,Kombi_PAG
 SG_ AAG_Blinker_HL_def : 10|1@1+ (1.0,0.0) [0.0|1] ""  Kombi,Kombi_PAG
 SG_ AAG_Blinker_HR_def : 11|1@1+ (1.0,0.0) [0.0|1] ""  Kombi,Kombi_PAG
 SG_ AAG_Bremslicht_H_def : 12|1@1+ (1.0,0.0) [0.0|1] ""  Kombi,Kombi_PAG
 SG_ AAG_Schlusslicht_HL_def : 13|1@1+ (1.0,0.0) [0.0|1] ""  Kombi,Kombi_PAG
 SG_ AAG_Schlusslicht_HR_def : 14|1@1+ (1.0,0.0) [0.0|1] ""  Kombi,Kombi_PAG
 SG_ AAG_Bremslicht_Reku : 15|1@1+ (1.0,0.0) [0.0|1] ""  Vector__XXX
 SG_ AAG_AVS_Fehler_02 : 18|1@1+ (1.0,0.0) [0.0|1] ""  Kombi,Kombi_PAG
 SG_ AAG_LED_aktiv : 19|1@1+ (1.0,0.0) [0.0|1] ""  Vector__XXX
 SG_ AAG_AVS_Stati : 20|4@1+ (1.0,0.0) [0.0|15] ""  Vector__XXX

BO_ 345 ARA_Status_01: 8 Gateway
 SG_ ARA_Knickwinkel_Konfidenz : 12|7@1+ (1,0) [0|120] "Unit_DegreOfArc"  Kombi,Kombi_PAG
 SG_ ARA_Texte : 19|6@1+ (1.0,0.0) [0.0|63] ""  Kombi,Kombi_PAG
 SG_ ARA_Modus : 25|1@1+ (1.0,0.0) [0.0|1] ""  Kombi,Kombi_PAG
 SG_ ARA_Aktiver_Grafikmodus : 26|1@1+ (1.0,0.0) [0.0|1] ""  Kombi,Kombi_PAG
 SG_ ARA_Deaktivierung_sperren : 27|1@1+ (1.0,0.0) [0.0|1] ""  Vector__XXX
 SG_ ARA_Modus_Anf : 28|1@1+ (1.0,0.0) [0.0|1] ""  Vector__XXX
 SG_ ARA_Bremsfuss : 29|1@1+ (1.0,0.0) [0.0|1] ""  Kombi,Kombi_PAG
 SG_ ARA_Sensor_Aktivierung : 30|1@1+ (1.0,0.0) [0.0|1] ""  Vector__XXX
 SG_ ARA_Knickwinkel_Komfort : 31|6@1+ (1,0) [0|60] "Unit_DegreOfArc"  Kombi,Kombi_LB,Kombi_PAG
 SG_ ARA_Status : 37|4@1+ (1.0,0.0) [0.0|15] ""  Vector__XXX
 SG_ ARA_Knickwinkel_Max : 41|7@1+ (1,0) [0|120] "Unit_DegreOfArc"  Kombi,Kombi_LB,Kombi_PAG
 SG_ ARA_Knickwinkel_Soll : 48|8@1+ (1,-125) [-125|126] "Unit_DegreOfArc"  Kombi,Kombi_LB,Kombi_PAG
 SG_ ARA_Knickwinkel_Ist : 56|8@1+ (1,-125) [-125|126] "Unit_DegreOfArc"  Kombi,Kombi_LB,Kombi_PAG

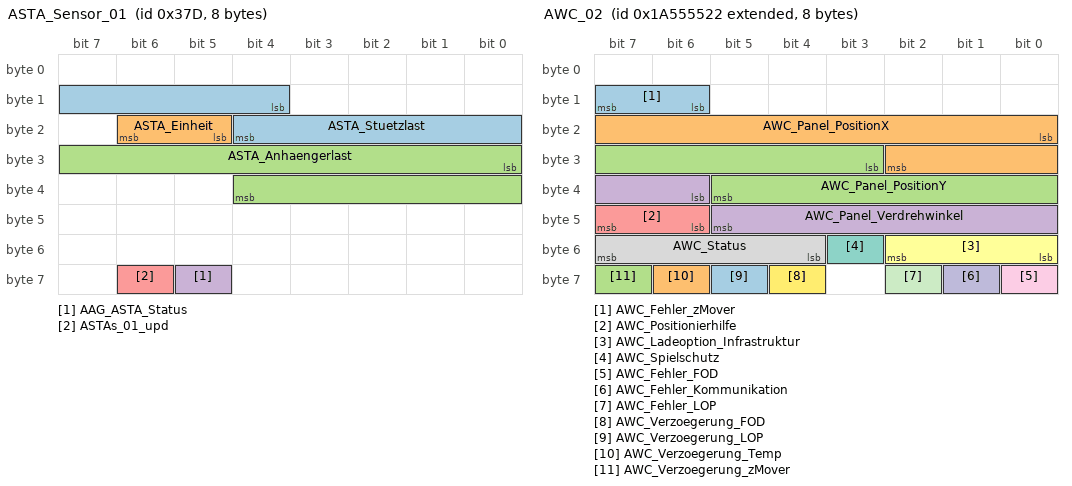
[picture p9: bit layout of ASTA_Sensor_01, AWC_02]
BO_ 893 ASTA_Sensor_01: 8 Gateway
 SG_ ASTA_Stuetzlast : 12|9@1+ (1,0) [0|300] "Unit_None"  Kombi
 SG_ ASTA_Einheit : 21|2@1+ (1.0,0.0) [0.0|3] ""  Kombi
 SG_ ASTA_Anhaengerlast : 24|13@1+ (1,0) [0|5000] "Unit_None"  Kombi
 SG_ AAG_ASTA_Status : 61|1@1+ (1.0,0.0) [0.0|1] ""  Kombi
 SG_ ASTAs_01_upd : 62|1@1+ (1.0,0.0) [0.0|1] ""  Kombi

BO_ 2589283618 AWC_02: 8 Gateway
 SG_ AWC_Fehler_zMover : 14|2@1+ (1.0,0.0) [0.0|3] ""  Vector__XXX
 SG_ AWC_Panel_PositionX : 16|11@1+ (1,-1000) [-1000|1000] "Unit_Centimeter"  Vector__XXX
 SG_ AWC_Panel_PositionY : 27|11@1+ (1,-1000) [-1000|1000] "Unit_Centimeter"  Vector__XXX
 SG_ AWC_Panel_Verdrehwinkel : 38|8@1+ (1.5,0) [0.0|360.0] "Unit_DegreOfArc"  Vector__XXX
 SG_ AWC_Positionierhilfe : 46|2@1+ (1.0,0.0) [0.0|3] ""  Vector__XXX
 SG_ AWC_Ladeoption_Infrastruktur : 48|3@1+ (1.0,0.0) [0.0|7] ""  Vector__XXX
 SG_ AWC_Spielschutz : 51|1@1+ (1.0,0.0) [0.0|1] ""  Vector__XXX
 SG_ AWC_Status : 52|4@1+ (1.0,0.0) [0.0|15] ""  Vector__XXX
 SG_ AWC_Fehler_FOD : 56|1@1+ (1.0,0.0) [0.0|1] ""  Vector__XXX
 SG_ AWC_Fehler_Kommunikation : 57|1@1+ (1.0,0.0) [0.0|1] ""  Vector__XXX
 SG_ AWC_Fehler_LOP : 58|1@1+ (1.0,0.0) [0.0|1] ""  Vector__XXX
 SG_ AWC_Verzoegerung_FOD : 60|1@1+ (1.0,0.0) [0.0|1] ""  Vector__XXX
 SG_ AWC_Verzoegerung_LOP : 61|1@1+ (1.0,0.0) [0.0|1] ""  Vector__XXX
 SG_ AWC_Verzoegerung_Temp : 62|1@1+ (1.0,0.0) [0.0|1] ""  Vector__XXX
 SG_ AWC_Verzoegerung_zMover : 63|1@1+ (1.0,0.0) [0.0|1] ""  Vector__XXX

BO_TX_BU_ 2331596020 :Gateway,Gateway_PAG;
BO_TX_BU_ 678 :Gateway,Gateway_PAG;
BO_TX_BU_ 679 :Gateway,Gateway_PAG;
BO_TX_BU_ 680 :Gateway,Gateway_PAG;
BO_TX_BU_ 681 :Gateway,Gateway_PAG;
BO_TX_BU_ 614 :Gateway,Gateway_PAG;
BO_TX_BU_ 2331595865 :Gateway,Gateway_PAG;
BO_TX_BU_ 2331595866 :Gateway,Gateway_PAG;
BO_TX_BU_ 2331595867 :Gateway,Gateway_PAG;
BO_TX_BU_ 2331595868 :Gateway,Gateway_PAG;
BO_TX_BU_ 2331595869 :Gateway,Gateway_PAG;
BO_TX_BU_ 2331595870 :Gateway,Gateway_PAG;
BO_TX_BU_ 2331595871 :Gateway,Gateway_PAG;
BO_TX_BU_ 2331595971 :Gateway,Gateway_PAG;
BO_TX_BU_ 2527679927 :Gateway,Gateway_PAG;
BO_TX_BU_ 232 :Gateway,Gateway_PAG;
BO_TX_BU_ 1660 :Gateway,Gateway_PAG;
BO_TX_BU_ 64 :Gateway,Gateway_PAG;
BO_TX_BU_ 1312 :Gateway,Gateway_PAG;
BO_TX_BU_ 1349 :Gateway,Gateway_PAG;
BO_TX_BU_ 674 :Gateway,Gateway_PAG;
BO_TX_BU_ 1633 :Gateway,Gateway_PAG;
BO_TX_BU_ 345 :Gateway,Gateway_PAG;
BO_TX_BU_ 893 :Gateway,Gateway_PAG;
BO_TX_BU_ 2589283618 :Gateway,Gateway_PAG;

CM_ "MLBevo_DCAN_V8.24.00F Generated by BusNet_NG_Produktiv 9.24.4";
CM_ BU_ CGS "Charisma und Gear Switch";
CM_ BU_ Gateway "MLBevo Diagnoseinterface für Datenbus

connected Gateway Version 2.0, Zulieferer Conti Markdorf
- e & e4

connected Gateway Version 3.1, Zulieferer ESR/Lear
- e, e2, e5, e6";
CM_ BU_ Gateway_PAG "Gateway-Variante für PAG - Absprungbasis Gateway 3.x";
CM_ BU_ HUD "Das Head-Up-Display, dass im MQB und MLBevo zum Einsatz kommt";
CM_ BU_ Kombi "MLBevo";
CM_ BU_ Kombi_PAG "MLBevo Hut-Steuergerät für PAG";
CM_ BU_ Waehlhebel_SB "MLBevo ab IS3

zuvor WH vom D4, am G-CAN am Getriebe.

Absicherung nötig.
Evtl. Waehlhebel_01 und Getriebe_05 nutzen und auf CRC ändern.";

CM_ BO_ 1660 "MLBevo";
CM_ BO_ 1633 "ab MQB 7.2";

CM_ SG_ 2331596020 ACA_FoD_Status "Informiert das zFAS über den FoD-Freischaltstatus der ACA-Funktion";
CM_ SG_ 2331596020 ACC_Charisma_FahrPr "MLBevo: Aktuelles Fahrprogramm des Charisma-Teilnehmers (siehe Systemlastenheft Drive Select)
MQB: Istwert der Kennlinie (siehe Systemlastenheft MQB FPA)";
CM_ SG_ 2331596020 ACC_Charisma_Status "Rückmeldung an den Charisma-Master

Wert 0x3 ist nur für Fahrzeuge ab MQB relevant";
CM_ SG_ 2331596020 ACC_Kennlinie_Kurvenregler "Umschaltung der Kennlinie für prädektive Längsregelung";
CM_ SG_ 2331596020 ACC_Tempolimitassistent_Ein "Status ACC-Tempolimitassistent";
CM_ SG_ 2331596020 ACC_Texte_03 "Zusätzliches Signal zu 'ACC_Texte_Primaeranz', welches Warnungen und Fahrerhinweise bzgl. ACC im Mitteldisplay des Kombis anzeigt; Signalergänzung der Aktivierverhinderung aufgrund Geschwindigkeitsgrenze für ACC und TA";
CM_ SG_ 2331596020 ACC_Texte_Sekundaeranz_03 "VW: Anzeige ACC Informationen, wie z.B. die Vorankündigung, oder die Anfahrbereitschaft";

CM_ SG_ 678 ACA_Querfuehrung "Ansteuerung einer primären Anzeige 'Querführung aktiv' für ACA in verschiedenen Farben";
CM_ SG_ 678 ACC_Abstandsindex_02 "Für die optionale Anzeige einer einheitenlosen Abstandsreserve oder einer gemessenen Zeitlücke in der Zusatzanzeige. Der Wertebereich 1..1021 entspricht Audi (aktiv_Folgefahrt), VW (passiv/aktiv_Folgefahrt). Audi nutzt den Wertebereich 0..1023, VW nutzt d";
CM_ SG_ 678 ACC_Anzeige_Zeitluecke "Anforderung zur Umschaltung zwischen dem Anzeigemodus 'Keine Änderung Zeitlücke' und 'Änderung Zeitlücke' (z.B. Pfeildarstellung in Zusatzanzeige)
";
CM_ SG_ 678 ACC_Display_Prio "Zur situationsabhängigen Prioritätensteuerung von ACC Anzeigen im nicht permanenten Anzeigebereich. Im Kombiinstrument ist jeder Prioritätsstufe eine adäquate Prio-Definition zugeordnet.

";
CM_ SG_ 678 ACC_EGO_Fahrzeug "Ansteuerung einer Statusanzeige für ACC in verschiedenen Farben";
CM_ SG_ 678 ACC_Gesetzte_Zeitluecke "Nur in ADR/ACC-Fahrzeugen: ACC Zusatzanzeige: 0 = aus / ungleich 0 = ein; angezeigte ADR-Zeitlücke wird auf 3 Bits begrenzt";
CM_ SG_ 678 ACC_Optischer_Fahrerhinweis "Fahrerübernahmeaufforderung; z.B. bei Erreichen der Systemgrenzen oder beim Auftreten von Fehlern in kritischen Situationen (VW).
";
CM_ SG_ 678 ACC_Regelung_AIO "Unterscheidung im Kombi, ob pACC Regelung auf Ampel aktiv oder AIO zur Anzeige kommt";
CM_ SG_ 678 ACC_rel_Objekt_Zusatzanz "Für optionale Anzeige eines Bildes/Textes in der Zusatzanzeige. ";
CM_ SG_ 678 ACC_Relevantes_Objekt_02 "Ansteuerung einer primären Anzeige 'Relevantes Objekt' für ACC in verschiedenen Farben.";
CM_ SG_ 678 ACC_Tempolimit "Anzeige einer Tempolimit-Vorgabe (Geschwindigkeitsbegrenzung, Aufhebung einer Geschwindigkeitsbegrenzung)

Signalbeschreibung 0..31: siehe LH Kombi-SG_-_6.2.x_ACC";
CM_ SG_ 678 ACC_Texte_Primaeranz_02 "Textdefinitionen";
CM_ SG_ 678 ACC_Texte_Zusatzanz_02 "Beschreibt aktuell aktives Fahrprogramm/Zeitlücke usw. des ACC";
CM_ SG_ 678 ACC_Warnhinweis "Porsche E2: zur Anzeige der gelben Warnaufforderung als Vorstufe zum TOR (TOR: Übernahmeaufforderung bei Erreichen der ACC-Systemgrenze)

VW MQB: Signal wird zur Ansteuerung der Abstandswarnung im Kombiinstrument genutzt.";
CM_ SG_ 678 ACC_Warnung_Verkehrszeichen_1 "PACC: Zeigt bei Überschreitung der aktuellen Höchstgeschwindigkeit um 10% einen Hinweis im Kombi an";
CM_ SG_ 678 ACC_Wunschgeschw_02 "Zur Anzeige der Wunschgeschwindigkeit im Kombiinstrument
";
CM_ SG_ 678 ACC_Wunschgeschw_erreicht "Signal for Bentley BY83x: ACC_set_speed_achieved

Mit diesem Signal wird im Kombi eine Anzeige angesteuert, wenn das Fahrzeug die gesetzte Wunschgeschwindigkeit erreicht hat.

This signal illuminates the set speed icon a different colour  in the Kombi";
CM_ SG_ 678 ACC_Wunschgeschw_Farbe "Umschaltung der Farbe der angezeigten Setzgeschwindigkeit im Tacho";
CM_ SG_ 678 STA_Primaeranz "Signal zur Ansteuerung der STA-Primaeranzeige";

CM_ SG_ 679 ACC_Einheit_maxSetzgeschw "Einheit zu Signal ACC_maxSetzgeschw";
CM_ SG_ 679 ACC_ENG_Texte "Signal zur Ansteuerung von Fahrerhinweisen der Energo-Funktioin im Mitteldisplay ";
CM_ SG_ 679 ACC_Kurvenassistent "Ansteuerung einer Anzeige zur Funktion Kurvenassistent";
CM_ SG_ 679 ACC_maxRegelgeschw "Signal dient zur Anzeige von Regelabweichungen.
Addiert zu der Regelgeschwindigkeit ergibt sich eine Toleranzgeschwindigkeit.";
CM_ SG_ 679 ACC_maxSetzgeschw "maximale ACC-Setzgeschwindigkeit zur Ansteuerung des ACC-Setzbereichs im Kombi
Hinweis: Signal ist mit Signal ACC_Einheit_maxSetzgeschw zu interpretieren";
CM_ SG_ 679 ACC_minRegelgeschw "Signal dient zur Anzeige von Regelabweichungen.
Subtrahiert von der Regelgeschwindigkeit ergibt sich eine Toleranzgeschwindigkeit.";
CM_ SG_ 679 ACC_Regelgeschw "Zur Anzeige der Regelgeschwindigkeit (z.B. Kurven- / Tempolimitassistent) im Kombiinstrument";
CM_ SG_ 679 ACC_RUV "Anzeige für Rechtsunterholverhinderung in Abhängigkeit Rechts- / Linksverkehr";
CM_ SG_ 679 ACC_Status_GRA_Modus "Statusinformation zur GRA in Verbindung mit ACC";
CM_ SG_ 679 ACC_Tachokranz "Für zusätzliche Status- und Einstellbereichsanzeige im Tacho. (z.B. Tachokranz)
";
CM_ SG_ 679 ACC_Tempolimit_Einheit "Einheit des Verkehrszeichen in ACC_Tempolimit";
CM_ SG_ 679 ACC_Tempolimitassistent_02 "Ansteuerng einer Anzeige zur Funktion Tempolimitassistent";
CM_ SG_ 679 ACC_Typ_Tachokranz_unten "Mit diesem Bit wird die LED unterhalb der minimalen Setzgeschwindigkeit an/ausgeschaltet.
";

CM_ SG_ 680 AbstWarn_LRR_FAS_Fkt_Status "Rückmeldung des Funktionsstatus an FAS ProfileMaster";
CM_ SG_ 680 ACA_Hinweistexte "Anzeigesignal für Hinweise zur Fahrerbedienenhandlung";
CM_ SG_ 680 ACA_Querfuehrung_Texte "Signal zur Ansteuerung von Fahrerhinweisen der Querführung in ACA im Mitteldisplay";
CM_ SG_ 680 ACC_Abstand_Abstandswarner "Signal dient zur Anzeige des Abstands im Kombi
Hinweis: das Signal ist mit dem Signal ACC_Einheit_Abstandswarner zu interpretieren";
CM_ SG_ 680 ACC_Akustik_03 "Ansteuerung der zugehörigen Akustik im Kombiinstrument, solange die entsprechende Bitkombination gesetzt ist.";
CM_ SG_ 680 ACC_Einheit_Abstandswarner "Einheit zu Signal ACC_Abstand_Abstandswarner";
CM_ SG_ 680 ACC_FoD_Status "Informiert den TSK und Kombi, ob die ACC-Funktion freigeschaltet ist oder nicht.";
CM_ SG_ 680 ACC_Geschw_Zielfahrzeug "Nur Porsche E2 und Bentley BY636: Zur grafischen Darstellung der Geschwindigkeit eines im ACC Regelbetrieb erkannten Zielobjektes bzw, vorausfahrenden Objektes. ACC ermittelt nach der Vorschrift: Vom Kombi eingelesene 'angezeigte Geschwindigkeit' plus TO_";
CM_ SG_ 680 ACC_STA_Text "ACC_STA_Text wird gesendet wenn aktiv regelt.";
CM_ SG_ 680 ACC_Status_Anzeige "Status nur zur Defintion von Anzeige im Kombi. Hinweis: Wird für die spez. VW-Anzeige (überlappende Anzeigebereiche) verwendet. Vom AUDI-ACC im Rahmen der Modulstrategie zu bedienen.";
CM_ SG_ 680 ACC_Texte "Zusätzliches Signal zu 'ACC_Texte_Primaeranz', welches Warnungen und Fahrerhinweise bzgl. ACC im Mitteldisplay des Kombis anzeigt.";
CM_ SG_ 680 ACC_Texte_Abstandswarner "Signal zur Ansteuerung von Fahrer- und Warnhinweisen des Abstandswarners im Mitteldisplay";
CM_ SG_ 680 ACC_Texte_Sekundaeranz "Textdefinitionen für Anzeige ACC, Tempolimitassistent und Kurvenassistent";
CM_ SG_ 680 ACC_Vorz_Abstandswarner "Vorzeichen der Abstandsanzeige und -warnung";
CM_ SG_ 680 ACC_Zeitluecke_Abstandswarner "Anzeige der aktuellen Zeitluecke zum vorausfahrenden Fahrzeug";
CM_ SG_ 680 FAS_Licht_Anf "Anforderung zum Einschalten des Assistenzfahrlicht";
CM_ SG_ 680 STA_Texte "Signal, welches Warnungen und Fahrerhinweise bzgl. der Funktion STA im Kombi anzeigt";
CM_ SG_ 680 STA_Zusatzanz "Für Anzeigen der STA-Funktion im Mitteldisplay";

CM_ SG_ 681 ACC_Status_Kurvenassistent "Status der Einstellung im MIB/MMI zum Kurvenassistent von pACC.";
CM_ SG_ 681 ACC_Status_Tempolimitassistent "Status der Einstellung im MIB/MMI zum Tempolimitassistent von pACC.
(Wahlweise mit Toleranz und Offset)";
CM_ SG_ 681 AWV_Einstellung_System_FSG "Signal zur Realisierung des BAP-Koordiantors";
CM_ SG_ 681 AWV_Einstellung_Warnung_FSG "Signal zur Realisierung des BAP-Koordinators";
CM_ SG_ 681 AWV_LED_Leiste "Ansteuerung LED Warnleiste";
CM_ SG_ 681 AWV_Status_Anzeige "Signal zur Realisierung des BAP-Koordiantors
Signal identisch zu AWV_BAP_Status 
Kl15 aus: nicht bereitgestellt.";
CM_ SG_ 681 AWV_Texte "Hinweisanzeige im Kombi 'Hauptdisplay'";
CM_ SG_ 681 AWV_Warnlevel "Warnlevel der Funktion Anhaltewegverkürzung";
CM_ SG_ 681 AWV_Warnung "Hinweisanzeige im Kombi 'Hauptdisplay'";

CM_ SG_ 614 ACC_Fahrprogramm_PACC "Weiterleitung des aktuellen Wertes aus der BAP-Funktion 'DrivingProgram' an PACC High / InnoDrive. Damit Wahl eines Fahrprogramms (Eco/Comfort etc.).";
CM_ SG_ 614 ACC_Nutzung_VZ_PACC "Einstellung, ob Verkehrszeichen von der Funktion PACC/InnoDrive verarbeitet werden sollen.";
CM_ SG_ 614 ACC_Offset_Default_PACC "Durch den Fahrer einstellbarer Defaultwert für das geschwindigkeitsbezogene Offset der Funktion PACC/InnoDrive";
CM_ SG_ 614 ACC_PEA_Einheit_Geschw "Geschwindigkeitseinheit der Regelung des prädiktiven Effizienz Assistenten im ACC";
CM_ SG_ 614 ACC_PEA_LernenderFahrerOffset "Wert für lernenden Fahreroffset des prädiktiven Effizienzassistenten im ACC";
CM_ SG_ 614 ACC_Regelung_durch_PACC "Das Signal gibt an, ob ACC aktuell aufgrund einer InnoDrive-Anforderung regelt oder die ACC-Regler dominant sind.";
CM_ SG_ 614 ACC_Sensibilitaet_PACC "Einstellung der Menüeinträge der Funktion PACC/Innodrive bzw. ACA prädiktiv zur Aktivierung / Deaktivierung der Features 'Tempolimitassistent' und 'Regelung auf Straßenverlauf'";
CM_ SG_ 614 ACC_vLimit1_PACC "Vom Fahrer einstellbare maximale Geschwindigkeit fuer die Funktion PACC/InnoDrive.";

CM_ SG_ 2331595865 ACC_HMI_Obj_01_dx "Umfeldvisualisierung FAS HMI: Longitudinaler Abstand des dargestellten Objekts (bezogen auf Fahrzeug USK)";
CM_ SG_ 2331595865 ACC_HMI_Obj_01_dy "Umfeldvisualisierung FAS HMI: Prozentuale Position innerhalb der zugeordneten Spur des dargestellten Objekts";
CM_ SG_ 2331595865 ACC_HMI_Obj_01_LaengsRegelung "Umfeldvisualisierung FAS HMI: Auf Basis des dargestellten Objekts findet eine Längsregelung statt";
CM_ SG_ 2331595865 ACC_HMI_Obj_01_QuerRegelung "Umfeldvisualisierung FAS HMI: Auf Basis des dargestellten Objekts findet eine Querregelung statt";
CM_ SG_ 2331595865 ACC_HMI_Obj_01_Spurzuordnung "Umfeldvisualisierung FAS HMI: Spurzuordnung des dargestellten Objekts";
CM_ SG_ 2331595865 ACC_HMI_Obj_01_Typ "Umfeldvisualisierung FAS HMI: Typ des dargestellten Objekts";
CM_ SG_ 2331595865 ACC_HMI_Obj_02_dx "Umfeldvisualisierung FAS HMI: Longitudinaler Abstand des dargestellten Objekts (bezogen auf Fahrzeug USK)";
CM_ SG_ 2331595865 ACC_HMI_Obj_02_dy "Umfeldvisualisierung FAS HMI: Prozentuale Position innerhalb der zugeordneten Spur des dargestellten Objekts";
CM_ SG_ 2331595865 ACC_HMI_Obj_02_LaengsRegelung "Umfeldvisualisierung FAS HMI: Auf Basis des dargestellten Objekts findet eine Längsregelung statt";
CM_ SG_ 2331595865 ACC_HMI_Obj_02_QuerRegelung "Umfeldvisualisierung FAS HMI: Auf Basis des dargestellten Objekts findet eine Querregelung statt";
CM_ SG_ 2331595865 ACC_HMI_Obj_02_Spurzuordnung "Umfeldvisualisierung FAS HMI: Spurzuordnung des dargestellten Objekts";
CM_ SG_ 2331595865 ACC_HMI_Obj_02_Typ "Umfeldvisualisierung FAS HMI: Typ des dargestellten Objekts";

CM_ SG_ 2331595866 ACC_HMI_Obj_03_dx "Umfeldvisualisierung FAS HMI: Longitudinaler Abstand des dargestellten Objekts (bezogen auf Fahrzeug USK)";
CM_ SG_ 2331595866 ACC_HMI_Obj_03_dy "Umfeldvisualisierung FAS HMI: Prozentuale Position innerhalb der zugeordneten Spur des dargestellten Objekts";
CM_ SG_ 2331595866 ACC_HMI_Obj_03_LaengsRegelung "Umfeldvisualisierung FAS HMI: Auf Basis des dargestellten Objekts findet eine Längsregelung statt";
CM_ SG_ 2331595866 ACC_HMI_Obj_03_QuerRegelung "Umfeldvisualisierung FAS HMI: Auf Basis des dargestellten Objekts findet eine Querregelung statt";
CM_ SG_ 2331595866 ACC_HMI_Obj_03_Spurzuordnung "Umfeldvisualisierung FAS HMI: Spurzuordnung des dargestellten Objekts";
CM_ SG_ 2331595866 ACC_HMI_Obj_03_Typ "Umfeldvisualisierung FAS HMI: Typ des dargestellten Objekts";
CM_ SG_ 2331595866 ACC_HMI_Obj_04_dx "Umfeldvisualisierung FAS HMI: Longitudinaler Abstand des dargestellten Objekts (bezogen auf Fahrzeug USK)";
CM_ SG_ 2331595866 ACC_HMI_Obj_04_dy "Umfeldvisualisierung FAS HMI: Prozentuale Position innerhalb der zugeordneten Spur des dargestellten Objekts";
CM_ SG_ 2331595866 ACC_HMI_Obj_04_LaengsRegelung "Umfeldvisualisierung FAS HMI: Auf Basis des dargestellten Objekts findet eine Längsregelung statt";
CM_ SG_ 2331595866 ACC_HMI_Obj_04_QuerRegelung "Umfeldvisualisierung FAS HMI: Auf Basis des dargestellten Objekts findet eine Querregelung statt";
CM_ SG_ 2331595866 ACC_HMI_Obj_04_Spurzuordnung "Umfeldvisualisierung FAS HMI: Spurzuordnung des dargestellten Objekts";
CM_ SG_ 2331595866 ACC_HMI_Obj_04_Typ "Umfeldvisualisierung FAS HMI: Typ des dargestellten Objekts";

CM_ SG_ 2331595867 ACC_HMI_Obj_05_dx "Umfeldvisualisierung FAS HMI: Longitudinaler Abstand des dargestellten Objekts (bezogen auf Fahrzeug USK)";
CM_ SG_ 2331595867 ACC_HMI_Obj_05_dy "Umfeldvisualisierung FAS HMI: Prozentuale Position innerhalb der zugeordneten Spur des dargestellten Objekts";
CM_ SG_ 2331595867 ACC_HMI_Obj_05_LaengsRegelung "Umfeldvisualisierung FAS HMI: Auf Basis des dargestellten Objekts findet eine Längsregelung statt";
CM_ SG_ 2331595867 ACC_HMI_Obj_05_QuerRegelung "Umfeldvisualisierung FAS HMI: Auf Basis des dargestellten Objekts findet eine Querregelung statt";
CM_ SG_ 2331595867 ACC_HMI_Obj_05_Spurzuordnung "Umfeldvisualisierung FAS HMI: Spurzuordnung des dargestellten Objekts";
CM_ SG_ 2331595867 ACC_HMI_Obj_05_Typ "Umfeldvisualisierung FAS HMI: Typ des dargestellten Objekts";
CM_ SG_ 2331595867 ACC_HMI_Obj_06_dx "Umfeldvisualisierung FAS HMI: Longitudinaler Abstand des dargestellten Objekts (bezogen auf Fahrzeug USK)";
CM_ SG_ 2331595867 ACC_HMI_Obj_06_dy "Umfeldvisualisierung FAS HMI: Prozentuale Position innerhalb der zugeordneten Spur des dargestellten Objekts";
CM_ SG_ 2331595867 ACC_HMI_Obj_06_LaengsRegelung "Umfeldvisualisierung FAS HMI: Auf Basis des dargestellten Objekts findet eine Längsregelung statt";
CM_ SG_ 2331595867 ACC_HMI_Obj_06_QuerRegelung "Umfeldvisualisierung FAS HMI: Auf Basis des dargestellten Objekts findet eine Querregelung statt";
CM_ SG_ 2331595867 ACC_HMI_Obj_06_Spurzuordnung "Umfeldvisualisierung FAS HMI: Spurzuordnung des dargestellten Objekts";
CM_ SG_ 2331595867 ACC_HMI_Obj_06_Typ "Umfeldvisualisierung FAS HMI: Typ des dargestellten Objekts";

CM_ SG_ 2331595868 ACC_HMI_Nachb_li_belegt "Umfeldvisualisierung FAS HMI: Nebenspur links belegt";
CM_ SG_ 2331595868 ACC_HMI_Nachb_re_belegt "Umfeldvisualisierung FAS HMI: Nebenspur rechts belegt";
CM_ SG_ 2331595868 ACC_HMI_Seg1_Gierwinkel "Umfeldvisualisierung FAS HMI: Gierwinkel des ersten Klothoidensegments";
CM_ SG_ 2331595868 ACC_HMI_Seg1_Kruemmung "Umfeldvisualisierung FAS HMI: Krümmung des ersten Klothoidensegments
Hinweis: Multiplikation des Rohwerts mit 2^-16";
CM_ SG_ 2331595868 ACC_HMI_Seg2_Beginn "Umfeldvisualisierung FAS HMI: Beginn des zweiten Klothoidensegments (bezogen auf Fahrzeug USK)";
CM_ SG_ 2331595868 ACC_HMI_Seg2_Kruemmung "Umfeldvisualisierung FAS HMI: Krümmung des zweiten Klothoidensegments
Hinweis: Multiplikation des Rohwerts mit 2^-16";
CM_ SG_ 2331595868 ACC_HMI_Spurwechsel_li "Umfeldvisualisierung FAS HMI: Spurwechselsignalisierung nach links";
CM_ SG_ 2331595868 ACC_HMI_Spurwechsel_re "Umfeldvisualisierung FAS HMI: Spurwechselsignalisierung nach rechts";

CM_ SG_ 2331595869 ACC_HMI_Ego_li_Seg1_QuerAbst "Umfeldvisualisierung FAS HMI: Querabstand der linken Egospur (bezogen auf Fahrzeug USK)";
CM_ SG_ 2331595869 ACC_HMI_Ego_re_Seg1_QuerAbst "Umfeldvisualisierung FAS HMI: Querabstand der rechten Egospur (bezogen auf Fahrzeug USK)";
CM_ SG_ 2331595869 ACC_HMI_Egospur_li_Typ "Umfeldvisualisierung FAS HMI: Typ der linken Egospur";
CM_ SG_ 2331595869 ACC_HMI_Egospur_re_Typ "Umfeldvisualisierung FAS HMI: Typ der rechten Egospur";
CM_ SG_ 2331595869 ACC_HMI_Nachb_li_Seg1_QuerAbst "Umfeldvisualisierung FAS HMI: Querabstand der linken Nachbarspur (bezogen auf Fahrzeug USK)";
CM_ SG_ 2331595869 ACC_HMI_Nachb_li_Typ "Umfeldvisualisierung FAS HMI: Typ der linken Nachbarspur";
CM_ SG_ 2331595869 ACC_HMI_Nachb_re_Seg1_QuerAbst "Umfeldvisualisierung FAS HMI: Querabstand der rechten Nachbarspur (bezogen auf Fahrzeug USK)";
CM_ SG_ 2331595869 ACC_HMI_Nachb_re_Typ "Umfeldvisualisierung FAS HMI: Typ der rechten Nachbarspur";

CM_ SG_ 2331595870 ACC_HMI_TrajektSeg1_Gierwinkel "Umfeldvisualisierung FAS HMI: Gierwinkel der Egotrajektorie";
CM_ SG_ 2331595870 ACC_HMI_TrajektSeg1_Kruemmung "Umfeldvisualisierung FAS HMI: Krümmung des ersten Klothoidensegments der Egotrajektorie
Hinweis: Multiplikation des Rohwerts mit 2^-16";
CM_ SG_ 2331595870 ACC_HMI_TrajektSeg1_QuerAbst "Umfeldvisualisierung FAS HMI: Querabstand der Egotrajektorie (bezogen auf Fahrzeug USK)";
CM_ SG_ 2331595870 ACC_HMI_TrajektSeg1_Valid "Umfeldvisualisierung FAS HMI: Darstellung einer Egotrajektorie";
CM_ SG_ 2331595870 ACC_HMI_TrajektSeg2_Beginn "Umfeldvisualisierung FAS HMI: Beginn des zweiten Klothoidensegments der Egotrajektorie(bezogen auf Fahrzeug USK)";
CM_ SG_ 2331595870 ACC_HMI_TrajektSeg2_Kruemmung "Umfeldvisualisierung FAS HMI: Krümmung des zweiten Klothoidensegments der Egotrajektorie
Hinweis: Multiplikation des Rohwerts mit 2^-16";

CM_ SG_ 2331595871 ACC_HMI_EgoObj_dy "Umfeldvisualisierung FAS HMI: Prozentuale Position des Egofahrzeugs innerhalb der eigenen Spur";
CM_ SG_ 2331595871 ACC_HMI_Kurvenwarnung "Umfeldvisualisierung FAS HMI: Darstellung einer Kurvenwarnung";
CM_ SG_ 2331595871 ACC_HMI_TrajektFarbe_li "Umfeldvisualisierung FAS HMI: Einfärbung der linken Trajektorienmarkierung (Fahrschlauch)";
CM_ SG_ 2331595871 ACC_HMI_TrajektFarbe_re "Umfeldvisualisierung FAS HMI: Einfärbung der rechten Trajektorienmarkierung (Fahrschlauch)";
CM_ SG_ 2331595871 ACC_HMI_TrajektVorausschau "Umfeldvisualisierung FAS HMI: Vorausschau der Trajektorie";
CM_ SG_ 2331595871 ACC_HMI_Zoomstufe "Umfeldvisualisierung FAS HMI: Angeforderte Zoomstufe der Umfeldvisualisierung";
CM_ SG_ 2331595871 ACC_HMI_ZoomstufeAktiv "Umfeldvisualisierung FAS HMI: Status der Darstellung Zoomstufe";

CM_ SG_ 2331595971 ACC_HMI_Zeitluecke_01_dx "Umfeldvisualisierung FAS HMI: Abstand der Zeitlueckenmarkierung vor EGO-Fahrzeug";
CM_ SG_ 2331595971 ACC_HMI_Zeitluecke_02_dx "Umfeldvisualisierung FAS HMI: Abstand der Zeitlueckenmarkierung vor EGO-Fahrzeug";
CM_ SG_ 2331595971 ACC_HMI_Zeitluecke_03_dx "Umfeldvisualisierung FAS HMI: Abstand der Zeitlueckenmarkierung vor EGO-Fahrzeug";
CM_ SG_ 2331595971 ACC_HMI_Zeitluecke_04_dx "Umfeldvisualisierung FAS HMI: Abstand der Zeitlueckenmarkierung vor EGO-Fahrzeug";
CM_ SG_ 2331595971 ACC_HMI_Zeitluecke_05_dx "Umfeldvisualisierung FAS HMI: Abstand der Zeitlueckenmarkierung vor EGO-Fahrzeug";
CM_ SG_ 2331595971 ACC_HMI_ZeitlueckenAuswahl "Umfeldvisualisierung FAS HMI: Auswahl der aktiven Zeitluecke";

CM_ SG_ 2527679927 ADA_AttentionLevel "combined attention level";
CM_ SG_ 2527679927 ADA_DistractionLevel "combined distraction level";
CM_ SG_ 2527679927 ADA_DrowsinessLevel "combined drowsiness level.";
CM_ SG_ 2527679927 ADA_DrowsinessSystemState "This signal contain the system state of the drowsiness detection of the customer driving function Attention and Drowsiness Assist (ADA).";
CM_ SG_ 2527679927 ADA_HMI_Ablenkung_Deaktivierung "This signal contain the deactivation notification of the distraction detection in form of a popup of the customer driving function Attention and Drowsiness Assist (ADA).";
CM_ SG_ 2527679927 ADA_HMI_Ablenkung_Fehler_Popup "This signal contain the different distraction detection error notifications in form of a popup of the customer driving function Attention and Drowsiness Assist (ADA).";
CM_ SG_ 2527679927 ADA_HMI_Ablenkung_Meldeakustik "This signal contain the information, if the different distraction detection notifications of the customer driving function Attention and Drowsiness Assist (ADA) should play with acoustic or without acoustic.";
CM_ SG_ 2527679927 ADA_HMI_Ablenkung_Meldung "This signal contain the different distraction detection notifications in form of a popup of the customer driving function Attention and Drowsiness Assist (ADA).";
CM_ SG_ 2527679927 ADA_HMI_Fahrzeit_seit_Pause "This signal contain the driving time since the last break of the driver.";
CM_ SG_ 2527679927 ADA_HMI_Muedigkeit_Deaktivierung "This signal contain the deactivation notification of the drowsiness detection in form of a popup of the customer driving function Attention and Drowsiness Assist (ADA).";
CM_ SG_ 2527679927 ADA_HMI_Muedigkeit_Event_Meldung "This signal contain the different drowsiness event notifications (e. g. yawning, microsleep, ...) in form of a popup of the customer driving function Attention and Drowsiness Assist (ADA).";
CM_ SG_ 2527679927 ADA_HMI_Muedigkeit_Fehler_Popup "This signal contain the different drowsiness detection error notifications in form of a popup of the customer driving function Attention and Drowsiness Assist (ADA).";
CM_ SG_ 2527679927 ADA_HMI_Muedigkeit_Meldeakustik "This signal contain the information, if the different drowsiness detection notifications of the customer driving function Attention and Drowsiness Assist (ADA) should play with acoustic or without acoustic.";
CM_ SG_ 2527679927 ADA_HMI_Muedigkeit_Meldung "This signal contain the different drowsiness detection notifications in form of a popup of the customer driving function Attention and Drowsiness Assist (ADA).";

CM_ SG_ 232 AFR_gMeter_ax "Längsbeschleunigung zur gMeter-Anzeige im Kombi";
CM_ SG_ 232 AFR_gMeter_ay "Querbeschleunigung zur gMeter-Anzeige im Kombi";
CM_ SG_ 232 AFR_Schluesselsuche_Anf "Anforderung an das kessy System zur Schlüsselsuche.";
CM_ SG_ 232 AFR_Standfkt_Status "Rückmeldung der eABC Software auf der EFP zum zFAS über die Ausführung der Standfunktion";
CM_ SG_ 232 AFR_StandfktSchluesselAktivieren "Aktivieren einer Standfunktion des aktiven Fahrwerks mit dem Funkschlüssel";

CM_ SG_ 1660 AGA_01_CRC "Für MLB:
'Berechnung siehe Lastenheft 'Kommunikationsabsicherung für FlexRay und CAN''

Ab MQB und MLBevo:
'Berechnung siehe Lastenheft 'End-to-End Kommunikationsabsicherung''

Endwerte siehe Begleitdokument 'S-PDU Kennungsfolgen'";
CM_ SG_ 1660 AGA_Charisma_FahrPr "MLBevo: Aktuelles Fahrprogramm des Charisma-Teilnehmers (siehe Systemlastenheft Drive Select)
MQB: Istwert der Kennlinie (siehe Systemlastenheft MQB FPA)";
CM_ SG_ 1660 AGA_Charisma_Status "Rückmeldung an den Charisma-Master

Wert 0x3 ist nur für Fahrzeuge ab MQB relevant";
CM_ SG_ 1660 AGA_Verstaerker_Mute "Freischaltung Verstaerkerkanal";
CM_ SG_ 1660 E_Sound_Mute_Icon "Abbildung der E-Sound Mute Funktion im Kombi als Icon";
CM_ SG_ 1660 E_Sound_Mute_LED "LED zur Anzeige, ob E-Sound stumm geschaltet ist.";
CM_ SG_ 1660 E_Sound_ohne_Funktion "Zeigt den Ausfall e_sound SG an";
CM_ SG_ 1660 E_Sound_Texte "Auswahl der Fehleranzeigetexte in Kombi";
CM_ SG_ 1660 E_Sound_verbaut "Signal dient zur Unterscheidung der beiden SGs 'aktive AGA' und 'e-sound' durch das Kombii. Beide SGs nutzen identische Signale und gleiche Diagnoseadresse.";

CM_ SG_ 64 AB_Anzeige_Fussg "Anzeige für ausgelöste Fussgängerschutz-Aktuatorik";
CM_ SG_ 64 AB_Belegung_VF "Belegungserkennung vorne Fahrer.";
CM_ SG_ 64 AB_Crash_Int "Crash_Intensität_1 = fahrzeugabhängige Reaktionen im Crash
Crash_Intensität_2 = fahrzeugabhängige Reaktionen im Crash
Crash_Intensität_3 = fahrzeugabhängige Reaktionen im Crash

Die jeweiligen fahrzeugabhängigen Reaktionen im Crash sind in einem separ";
CM_ SG_ 64 AB_Deaktiviert "Airbag oder Gurtstraffer wurden per Anpassung deaktiviert: Aktualisierung erst nach Selbsttest";
CM_ SG_ 64 AB_Deaktivierung_HV "Deaktivierung des HV-Systems und der HV-Teilnehmer im Crash (u.a. Hybrid- und Elektrofahrzeuge)";
CM_ SG_ 64 AB_Diagnose "Airbag in Diagnose";
CM_ SG_ 64 AB_EDR_Trigger "Triggerbedingung zur dezentralen Aufzeichnung unfallrelevanter Daten im Event Data Recorder";
CM_ SG_ 64 AB_Erh_Auf_VB "Der Fahrer soll bei einem Statuswechsel des Beifahrerairbags (ausgelöst durch die Beifahrerinsassenerkennung oder den Schlüsselschloßschalter) aufmerksam gemacht werden durch eine Anzeige im Kombi. Nur Audi: gültig für: AB2 (4-Türer AU352), B7, C6, D3";
CM_ SG_ 64 AB_Front_Crash "Bit wird bei Überschreitung der Gurtstraffer-, US- und RdW-Schwelle gesetzt";
CM_ SG_ 64 AB_Gurtwarn_VB "Beifahrer hat Gurt nicht gesteckt, Anzeige im Kombi";
CM_ SG_ 64 AB_Gurtwarn_VF "Fahrer hat Gurt nicht gesteckt, Anzeige im Kombi";
CM_ SG_ 64 AB_Heck_Crash "Wird für alle neu anlaufenden Projekte umgesetzt: AB8.4, Audi8/VW8";
CM_ SG_ 64 AB_Lampe "Sicherheitswarnlampe im Kombi wird vom Airbag-SG angesteuert; Zustand der Lampe wird auf dem CAN-Bus ausgegeben (auch Blinkinformation).";
CM_ SG_ 64 AB_MKB_Anforderung "Anforderung Multi-Kollisions-Bremsung";
CM_ SG_ 64 AB_MKB_gueltig "Multi-Kollisions-Bremsung im Airbag freigeschaltet";
CM_ SG_ 64 AB_RGS_Anst "PreCrash-Ansteuerung reversibler Gurtstraffer (Aktivierung und Kraftniveau)

10xx = deaktiviert";
CM_ SG_ 64 AB_Rollover_Crash "Wird im B6/B7 Cabrio und New Beetle Cabrio bedient. ";
CM_ SG_ 64 AB_SB_Crash "Z.Zt. nur in Verbindung mit Crash-Intensität >= 100b (Kraftstoffpumpenabschaltung) verwendet.
";
CM_ SG_ 64 AB_SF_Crash "Z.Zt. nur in Verbindung mit Crash-Intensität >= 100b (Kraftstoffpumpenabschaltung) verwendet.";
CM_ SG_ 64 AB_Stellgliedtest "Information, ob Airbag im Stellgliedtest ist, um eine Notrufauflösung beim Stellgliedtest zu verhindern";
CM_ SG_ 64 AB_Systemfehler "Systemfehler Ggf. wird Warnlampe dauernd eingeschaltet.";
CM_ SG_ 64 AB_Texte_AKS "Textanzeige für pyrotechnische Auslösung der aktiven Kopfstütze (AKS)";
CM_ SG_ 64 AB_VB_deaktiviert "Als Option vorgehalten, Beifahrerairbag wurden per Schlüsselschalter oder Insassenerkennung deaktiviert";
CM_ SG_ 64 AB_Versorgungsspannung "Übertragung der Plausibilitätsinformation Kl.15-Last vs. Kl.15-CAN.
Bedienung im Fall Kl.15-Last 'EIN' und Kl.15-CAN 'AUS' mit Ausgabe Warnung/Akustik im Kombi.";
CM_ SG_ 64 Airbag_01_BZ "Botschaft asynchron geroutet. Zählerwert kann springen.";
CM_ SG_ 64 Airbag_01_CRC "Für MLB:
'Berechnung siehe Lastenheft 'Kommunikationsabsicherung für FlexRay und CAN''

Ab MQB und MLBevo:
'Berechnung siehe Lastenheft 'End-to-End Kommunikationsabsicherung''

Endwerte siehe Begleitdokument 'S-PDU Kennungsfolgen'";
CM_ SG_ 64 SC_LowSpeedCrashErkannt "Crash erkannt bei niedriger Geschwindigkeit";
CM_ SG_ 64 SC_Masterzeit "Masterzeit für alle Objektlisten";
CM_ SG_ 64 SC_Masterzeit_Offset "Erweiterung des Signals SC_Masterzeit um zwei höherwertige Bits, so dass ein Zeitbereich von ~20s (statt 5s) abgedeckt werden kann. Der aus SC_Masterzeit_Offset und SC_Masterzeit zu bildende Zeitstempel wird für die Synchronisation von Ereignissen der Fun";

CM_ SG_ 1312 AB_Abschaltanf_SIH_BF "Die Insassenerkennung auf der Beifahrerseite fordert bei Übertemperatur eine Abschaltung der Sitzheizung an. Die Übertemperatur kann bei niederohmigen Nebenschlüssen der Sitzheizungsmatte als Folge von zu hohem resultierenden Strom auftreten.";
CM_ SG_ 1312 AB_Anforderung_eCall "Trigger für Car2X Steuergerät das ein eCall Ereignis erkannt wurde.";
CM_ SG_ 1312 AB_Anforderung_USM "Trigger für Gateway (OBDC) und MIB/MMI, dass ein USM-Ereignis erkannt wurde.";
CM_ SG_ 1312 AB_Anprall_FGS "Uebermittlung der Lage einer Kollision, Fussgaengerschutz-Aktorik";
CM_ SG_ 1312 AB_Anprall_Front_Beifahrer "Uebermittlung der Lage einer Kollision, Anprallzone Front Beifahrerseite";
CM_ SG_ 1312 AB_Anprall_Front_Fahrer "Uebermittlung der Lage einer Kollision, Anprallzone Front Fahrerseite";
CM_ SG_ 1312 AB_Anprall_Heck_Beifahrer "Uebermittlung der Lage einer Kollision, Anprallzone Beifahrerseite hinten";
CM_ SG_ 1312 AB_Anprall_Heck_Fahrer "Uebermittlung der Lage einer Kollision, Anprallzone Fahrerseite hinten";
CM_ SG_ 1312 AB_Anprall_Rollover "Uebermittlung der Lage einer Kollision, Rollover erkannt";
CM_ SG_ 1312 AB_Anprall_Seite_Beifahrer "Uebermittlung der Lage einer Kollision, Anprallzone Beifahrerseite Seite";
CM_ SG_ 1312 AB_Anprall_Seite_Fahrer "Uebermittlung der Lage einer Kollision, Anprallzone Fahrerseite Seite";
CM_ SG_ 1312 AB_Belegung_VB "Belegungserkennung vorne Beifahrer. Wird in US-Steuergeräten über Bladder-Matte bedient, optional bei RdW, falls SBE_EuroNCAP entschieden wird.";
CM_ SG_ 1312 AB_Crashschwere "Übermittlung der Crashschwere an das Gateway (OBDC)";
CM_ SG_ 1312 AB_Gurtschloss_BF "Gurtschlossstatus Beifahrerseite";
CM_ SG_ 1312 AB_Gurtschloss_FA "Gurtschlosstatatus Fahrerseite";
CM_ SG_ 1312 AB_Gurtschloss_Reihe2_BF "Gurtschlossstatus 2. Reihe Beifahrerseite,  Mehrausstattung";
CM_ SG_ 1312 AB_Gurtschloss_Reihe2_FA "Gurtschlossstatus 2. Reihe Fahrerseite, Mehrausstattung";
CM_ SG_ 1312 AB_Gurtschloss_Reihe2_MI "Gurtschlossstatus 2. Reihe Mitte,  Mehrausstattung";
CM_ SG_ 1312 AB_Gurtschloss_Reihe3_BF "Gurtschlossstatus 3. Reihe Beifahrerseite,  Mehrausstattung";
CM_ SG_ 1312 AB_Gurtschloss_Reihe3_FA "Gurtschlossstatus 3. Reihe Fahrerseite,  Mehrausstattung";
CM_ SG_ 1312 AB_Gurtschloss_Reihe3_MI "Gurtschlossstatus 3. Reihe Mitte,  Mehrausstattung";
CM_ SG_ 1312 AB_Sitzpos_Sens_BF "Ausgabe Sitzposition Beifahrer";
CM_ SG_ 1312 AB_Sitzpos_Sens_FA "Ausgabe Sitzposition Fahrer";
CM_ SG_ 1312 AB_Wickelklappung_Reihe2_BF "Status Wickelklappung 2. Reihe Beifahrerseite, Mehrausstattung";
CM_ SG_ 1312 AB_Wickelklappung_Reihe2_FA "Status Wickelklappung 2. Reihe Fahrerseite, Mehrausstattung";
CM_ SG_ 1312 AB_Wickelklappung_Reihe2_MI "Status Wickelklappung 2. Reihe Mitte, Mehrausstattung";
CM_ SG_ 1312 Airbag_02_CRC "Für MLB:
'Berechnung siehe Lastenheft 'Kommunikationsabsicherung für FlexRay und CAN''

Ab MQB und MLBevo:
'Berechnung siehe Lastenheft 'End-to-End Kommunikationsabsicherung''

Endwerte siehe Begleitdokument 'S-PDU Kennungsfolgen'";
CM_ SG_ 1312 LoGeWa_Event_Kombiwarnung "Event für Kombiwarnung";
CM_ SG_ 1312 SC_PAO_OFF_Anf "Sollwert für LED 'OFF' in Anzeige Passenger Airbag On/Off";
CM_ SG_ 1312 SC_PAO_ON_Anf "Sollwert für LED 'ON' in Anzeige Passenger Airbag On/Off";
CM_ SG_ 1312 SC_PAO_Schriftzug_Anf "Sollwert für LED 'PASSENGER AIRBAG' in Anzeige Passenger Airbag On/Off";

CM_ SG_ 1349 AB_Gurtwarn_Reihe2_BF "Status Gurtwarnung 2. Sitzreihe Beifahrerseite";
CM_ SG_ 1349 AB_Gurtwarn_Reihe2_FA "Status Gurtwarnung 2. Sitzreihe Fahrerseite";
CM_ SG_ 1349 AB_Gurtwarn_Reihe2_MI "Status Gurtwarnung 2. Sitzreihe Mitte";
CM_ SG_ 1349 AB_Gurtwarn_Reihe3_BF "Status Gurtwarnung 3. Sitzreihe Beifahrerseite";
CM_ SG_ 1349 AB_Gurtwarn_Reihe3_FA "Status Gurtwarnung 3. Sitzreihe Fahrerseite";
CM_ SG_ 1349 AB_Gurtwarn_Reihe3_MI "Status Gurtwarnung 3. Sitzreihe Mitte";
CM_ SG_ 1349 AB_SBR_hinten_verbau "Verbauinformation Sitzbelegungssensor hinten (2. und 3. Sitzreihe)";
CM_ SG_ 1349 AbstWarn_MV_FAS_Fkt_Status "FAS-ProfileMaster Iststatus der Kundenfunktion";
CM_ SG_ 1349 AWV_Einstellung_System_ASG "Signal zur Realisierung des BAP-Koordinators";
CM_ SG_ 1349 AWV_Einstellung_Warnung_ASG "Signal zur Realisierung des BAP-Koordinators";
CM_ SG_ 1349 LGI_FAS_Fkt_Status "FAS-ProfileMaster Iststatus der Kundenfunktion (LGI: Lokale Gefahreninformation)";
CM_ SG_ 1349 PreCrash_FAS_Fkt_Status "FAS-ProfileMaster Iststatus der Kundenfunktion";
CM_ SG_ 1349 SC_PreSense_Modus_System_KAS "BAP-Kommunikation zum Kreuzungsassistent";
CM_ SG_ 1349 SC_PreSense_Modus_System_MV "Signal zur Realisierung der BAP-Kommunikation für PreSense";
CM_ SG_ 1349 SC_PreSense_Modus_System_NV "Signal zur Realisierung der BAP-Kommunikation für PreSense";
CM_ SG_ 1349 SC_PreSense_Modus_Warnung_MV "Signal zur Realisierung der BAP-Kommunikation für PreSense";
CM_ SG_ 1349 SC_PreSense_Modus_Warnung_NV "Signal zur Realisierung der BAP-Kommunikation für PreSense";
CM_ SG_ 1349 WarnBrems_Charisma_FahrPr "Aktuell eingestelltes Fahrprogramm der Funktion Warn- und/oder Notbremsfunktion";
CM_ SG_ 1349 WarnBrems_Charisma_Status "Verfügbarkeit der Funktion Warn- und/oder Notbremsfunktion für die Ansteuerung durch den Charisma-Koordinator.";

CM_ SG_ 674 Allrad_06_BZ "Für MLB:
'Berechnung siehe Lastenheft 'Kommunikationsabsicherung für FlexRay und CAN''

Ab MQB und MLBevo:
'Berechnung siehe Lastenheft 'End-to-End Kommunikationsabsicherung''

Endwerte siehe Begleitdokument 'S-PDU Kennungsfolgen'
Botschaft asynchr";
CM_ SG_ 674 Allrad_06_CRC "Signal wird benötigt um die ASIL-Einstuffung vom Allrad-HangOn-SG abzusichern. 
Gemäß E2E-LAH muss das Signal am Anfang der PDU gesendet werden, zu IS8 wird also das Layout der Allrad_06 geändert (Rückwärt nicht kompatible).";
CM_ SG_ 674 ALR_Charisma_FahrPr "MLB: Aktuelles Fahrprogramm des Charisma-Teilnehmers (siehe Systemlastenheft Drive Select)
MQB: Istwert der Kennlinie (siehe Systemlastenheft MQB Charisma)";
CM_ SG_ 674 ALR_Charisma_Status "Systemstatus des Charismateilnehmers

Wert 0x3 ist nur für Fahrzeuge ab MQB relevant
";
CM_ SG_ 674 ALR_Ist_Proz_Anz "Istsperrgrad der Laengssperre für die Anzeige im Kombiinstrumen";
CM_ SG_ 674 ALR_Kuehlbedarf "Das Signal gibt den Kühlbedarf für die HangOn-Kupplung an das Motor-SG.";
CM_ SG_ 674 ALR_OBD_Status "Dieses Bit steuert die MIL-Lampe an (Motorsteuergerät reicht diese Info an Kombi weiter).";
CM_ SG_ 674 ALR_Schalten "Schaltung High->Low oder Low->High wird ausgeführt";
CM_ SG_ 674 ALR_Sta_Disconnect "Stellt den Schaltungszustand von Allrad dar. In Zustand 0x03 und 0x04 dürfen keine Momenteneingriffe erfolgen.

0x0 init
0x1 zugeschaltet --4WD Betrieb
0x2 abgeschaltet --2WD Betrieb 
0x3 Zuschaltung -- wird gerade zugeschaltet
0x4 Abschaltung -- wi";
CM_ SG_ 674 ALR_Texte "Allrad Texte zur Anzeige im Kombi";
CM_ SG_ 674 ALR_v_Begrenzung "Maximalgeschwindigkeitslimitierung des Fahrzeugs aufgrund Komponentenschutz";
CM_ SG_ 674 ALR_Vorwarnung "Schaltung wird demnächst eingeleitet. Bit bleibt bis zum Ende der Schaltung gesetzt";
CM_ SG_ 674 ALR_Warnlampe "'1', wenn Kuppung aufgrund zu vieler Fehler öffnet.
Aufprüfung der Warnlampe somit nicht möglich.  ";

CM_ SG_ 1633 AAG_Anhaenger_abgesteckt "Anhaenger wurde bei Kl. 15 aus abgesteckt";
CM_ SG_ 1633 AAG_Anhaenger_erkannt "Erkennung Anhaenger ";
CM_ SG_ 1633 AAG_AVS_Fehler_02 "Fehler AVS";
CM_ SG_ 1633 AAG_AVS_Fehler_02_inv "Fehler AVS (inverses Signal)";
CM_ SG_ 1633 AAG_AVS_Stati "Status AVS (bei abnehmbarer oder mech.schwenkbarer Anhängerkupplung ist der Status immer 0)";
CM_ SG_ 1633 AAG_Blinker_H_aktiv "Status: Anhaenger Blinker aktiv";
CM_ SG_ 1633 AAG_Blinker_HL_def "Anhaenger Blinker links defekt";
CM_ SG_ 1633 AAG_Blinker_HR_def "Anhaenger Blinker rechts defekt";
CM_ SG_ 1633 AAG_Bremsl_durch_ECD "Bremslicht durch ECD aktiv";
CM_ SG_ 1633 AAG_Bremslicht_H_def "Anhaenger Bremslicht defekt";
CM_ SG_ 1633 AAG_Bremslicht_Reku "AAG_Bremslicht_Reku meldet zyklisch den empfangenen Zustand des CAN-Signals MO_Bremslicht_Reku zurück.";
CM_ SG_ 1633 AAG_BZ "4bit-Botschaftszaehler, wird in jeder Sendebotschaft inkrementiert

";
CM_ SG_ 1633 AAG_LED_aktiv "Dieses Signal sendet der Beleuchtungsart des Anhängers (LED oder Lampe)
Bei LED aktiv erfolgt kein Kaltüberwachung";
CM_ SG_ 1633 AAG_NSL_aktiv "Anhaenger Nebelschlusslicht aktiv";
CM_ SG_ 1633 AAG_Schlusslicht_HL_def "Anhaenger Schlußlicht links defekt";
CM_ SG_ 1633 AAG_Schlusslicht_HR_def "Anhaenger Schlußlicht rechts defekt";

CM_ SG_ 345 ARA_Aktiver_Grafikmodus "Zeigt an  das eine Grafik für ARA aktiviert werden soll";
CM_ SG_ 345 ARA_Bremsfuss "Anforderung des Bremsfusssymbols im Kombi";
CM_ SG_ 345 ARA_Deaktivierung_sperren "Unterdrückt die Deaktivierung der ARA- Visualisierung";
CM_ SG_ 345 ARA_Knickwinkel_Ist "Gibt den aktuellen Knickwinkel zwischen Anhänger und Fahrzeug wieder";
CM_ SG_ 345 ARA_Knickwinkel_Komfort "Knickwinkelgrenze bis zu der, bei maximalem Lenkeinschlag, eine sofortige gerade Rückwärtsfahrt möglich ist.";
CM_ SG_ 345 ARA_Knickwinkel_Konfidenz "irregular trailer angle area value for HMI display";
CM_ SG_ 345 ARA_Knickwinkel_Max "Gibt den maximalen ausregelbaren Knickwinkel zwischen Anhänger und Fahrzeug wieder.";
CM_ SG_ 345 ARA_Knickwinkel_Soll "Vom Fahrer vorgegebener Knickwinkel.";
CM_ SG_ 345 ARA_Modus "Regelmodus ARA für Kombidarstellung";
CM_ SG_ 345 ARA_Modus_Anf "Anforderung des ARA-Modus im Türsteuergerät";
CM_ SG_ 345 ARA_Sensor_Aktivierung "activation  of ARA IP (image processing)";
CM_ SG_ 345 ARA_Status "Status of ARA Controller";
CM_ SG_ 345 ARA_Texte "Anforderung für Kombianzeigetexte und Akustik";

CM_ SG_ 893 AAG_ASTA_Status "Status ASTA";
CM_ SG_ 893 ASTA_Anhaengerlast "Anzeigewert der Anhaengerlast";
CM_ SG_ 893 ASTA_Einheit "Anzeigeeinheit (kg/lbs) für die Signale ASTA_Anhaengerlast und ASTA_Stuetzlast";
CM_ SG_ 893 ASTA_Stuetzlast "Anzeigewert der Stuetzlast";
CM_ SG_ 893 ASTAs_01_upd "Update-Signal für Botschaft ASTAs_01";

CM_ SG_ 2589283618 AWC_Fehler_FOD "FOD System defekt
(Foreign Object Detection = Metallerkennung)";
CM_ SG_ 2589283618 AWC_Fehler_Kommunikation "AWC Kommunikation zw. Infrastrukturspule und Fzg-Spule defekt";
CM_ SG_ 2589283618 AWC_Fehler_LOP "LOP System defekt
(Living Object Protection = Personenschutz)";
CM_ SG_ 2589283618 AWC_Fehler_zMover "z-Mover System defekt";
CM_ SG_ 2589283618 AWC_Ladeoption_Infrastruktur "Rückmeldung an das Lademanagement welche Ladeoption an der Infrastrukturseite ausgewählt wurde";
CM_ SG_ 2589283618 AWC_Panel_PositionX "Signal beschreibt den Abstand in x-Richtung (Fzg- Koordinatensystem) der Ladeplatten (optimale Ladeposition)";
CM_ SG_ 2589283618 AWC_Panel_PositionY "Signal beschreibt den Abstand in y-Richtung (Fzg- Koordinatensystem) der Ladeplatten (optimale Ladeposition)";
CM_ SG_ 2589283618 AWC_Panel_Verdrehwinkel "Signal beschreibt die Verdrehung der Bodenplatte zum Fahrzeug";
CM_ SG_ 2589283618 AWC_Positionierhilfe "Status AWC Positionierhilfe und Aktivierungssignal zur Aufschaltung der OPS-Anzeige (AWC Parkhilfe)";
CM_ SG_ 2589283618 AWC_Spielschutz "Spielschutz im AWC verhindert, dass z-Mover wiederholt angehoben und abgesenkt werden kann.
Signal gibt an ob Spielschutz aktiv ist.";
CM_ SG_ 2589283618 AWC_Status "momentaner Betriebszustand AWC inkl. z-Mover";
CM_ SG_ 2589283618 AWC_Verzoegerung_FOD "Verzögerung des Ladevorgangs aufgrund des FOD (Foreign Object Detection = Metallerkennung)";
CM_ SG_ 2589283618 AWC_Verzoegerung_LOP "Verzögerung des Ladevorgangs aufgrund des LOP (Living Object Protection = Personenschutz)";
CM_ SG_ 2589283618 AWC_Verzoegerung_Temp "Verzögerung des Ladevorgangs aufgrund der Umgebungstemperatur außerhalb Ladespec.";
CM_ SG_ 2589283618 AWC_Verzoegerung_zMover "Verzögerung des Ladevorgangs aufgrund des z-Movers";

BA_DEF_  "DBName" STRING;
BA_DEF_  "GenNWMApBusSleep" STRING;
BA_DEF_  "GenNWMApCanNormal" STRING;
BA_DEF_  "GenNWMApCanOff" STRING;
BA_DEF_  "GenNWMApCanOn" STRING;
BA_DEF_  "GenNWMApCanSleep" STRING;
BA_DEF_  "GenNWMApCanWakeUp" STRING;
BA_DEF_  "GenNWMGotoMode_Awake" STRING;
BA_DEF_  "GenNWMGotoMode_BusSleep" STRING;
BA_DEF_  "GenNWMSleepTime" INT 0 1000000;
BA_DEF_  "GenNWMTalkNM" STRING;
BA_DEF_  "Manufacturer" STRING;
BA_DEF_  "NmhBaseAddress" HEX 0 536870911;
BA_DEF_  "NmhMessageCount" INT 0 1024;
BA_DEF_  "NmType" STRING;
BA_DEF_  "VAGTP20_SetupMessageCount" INT 0 255;
BA_DEF_  "VAGTP20_SetupStartAddress" HEX 0 2047;
BA_DEF_  "VersionDay" INT 1 31;
BA_DEF_  "VersionMonth" INT 1 12;
BA_DEF_  "VersionWeek" INT 1 52;
BA_DEF_  "VersionYear" INT 0 99;
BA_DEF_  "VersionNumber" INT 0 65535;
BA_DEF_  "BusType" STRING;
BA_DEF_  "Baudrate" INT 1 1000000;
BA_DEF_  "SamplePointMin" INT 1 100;
BA_DEF_  "SamplePointMax" INT 1 100;
BA_DEF_  "SyncJumpWidthMin" INT 1 4;
BA_DEF_  "SyncJumpWidthMax" INT 1 4;
BA_DEF_  "NBTMin" INT 1 30;
BA_DEF_  "NBTMax" INT 1 30;
BA_DEF_  "NmhTimeoutTimer" INT 0 65535;
BA_DEF_  "NmhWaitBusSleepTimer" INT 0 65535;
BA_DEF_  "NmhPrepareBusSleepTimer" INT 0 65535;
BA_DEF_  "NmhLongTimer" INT 0 65535;
BA_DEF_  "NmhNStart" INT 0 255;
BA_DEF_ BU_  "GenNodAutoGenDsp" ENUM "No", "Yes";
BA_DEF_ BU_  "GenNodAutoGenSnd" ENUM "No", "Yes";
BA_DEF_ BU_  "GenNodSleepTime" INT 0 1000000;
BA_DEF_ BU_  "ILUsed" ENUM "No", "Yes";
BA_DEF_ BU_  "ECUVariantDefault" ENUM "No", "Yes";
BA_DEF_ BU_  "ECUVariantGroup" STRING;
BA_DEF_ BU_  "NodeLayerModules" STRING;
BA_DEF_ BU_  "NmhNode" ENUM "No", "Yes";
BA_DEF_ BU_  "NmNode" ENUM "No", "Yes";
BA_DEF_REL_ BU_SG_REL_  "GenSigTimeoutTime" INT 0 65535;
BA_DEF_ BO_  "DiagRequest" ENUM "No", "Yes";
BA_DEF_ BO_  "DiagResponse" ENUM "No", "Yes";
BA_DEF_ BO_  "DiagState" ENUM "No", "Yes";
BA_DEF_ BO_  "GenMsgChkConstant" HEX 0 4095;
BA_DEF_ BO_  "GenMsgCycleTime" INT 0 65535;
BA_DEF_ BO_  "GenMsgCycleTimeFast" INT 0 65535;
BA_DEF_ BO_  "GenMsgDelayTime" INT 0 100000;
BA_DEF_ BO_  "GenMsgILSupport" ENUM "No", "Yes";
BA_DEF_ BO_  "GenMsgNrOfRepetition" INT 0 100;
BA_DEF_ BO_  "GenMsgPDUConstants" STRING;
BA_DEF_ BO_  "GenMsgSendType" ENUM "Cyclic", "not_used", "not_used", "not_used", "not_used", "not_used", "not_used", "IfActive", "NoMsgSendType";
BA_DEF_ BO_  "GenMsgStartDelayTime" INT 0 100000;
BA_DEF_ BO_  "NmMessage" ENUM "No", "Yes";
BA_DEF_ BO_  "NmhMessage" ENUM "No", "Yes";
BA_DEF_ BO_  "MsgType" ENUM "Application", "NM ", "NMH", "TP2.0", "ISO-TP ", "BAP", "EID", "KS", "XCP_PRE_CONFIGURED", "XCP_RUNTIME_CONFIGURED";
BA_DEF_ BO_  "VAGTP20_API" HEX 0 255;
BA_DEF_ BO_  "VAGTP20_DynConnection" ENUM "No", "Yes";
BA_DEF_ BO_  "VAGTP20_DynSetup" ENUM "No", "Yes";
BA_DEF_ BO_  "VAGTP20_StatConnection" ENUM "No", "Yes";
BA_DEF_ SG_  "GenSigActiveRepetitions" INT -2147483648 2147483647;
BA_DEF_ SG_  "GenSigInactiveValue" INT -2147483648 2147483647;
BA_DEF_ SG_  "GenSigSendType" ENUM "Cyclic", "OnWrite", "OnWriteWithRepetition", "OnChange", "OnChangeWithRepetition", "IfActive", "IfActiveWithRepetition", "NoSigSendType", "OnChangeAndIfActive", "OnChangeAndIfActiveWithRepetition";
BA_DEF_ SG_  "GenSigStartValue" INT -2147483648 2147483647;
BA_DEF_ SG_  "NWM-WakeupAllowed" ENUM "No", "Yes";
BA_DEF_ SG_  "GenSigFuncType" ENUM "NoFunction", "MsgCounter", "CRC-8", "XOR", "XOR-2", "DatedBit", "SW-Kl15", "CHK", "Constant", "Protocol", "CRC-8-SAE_J1850", "CRC-32", "DataLength", "DataID", "MsgCounter16", "SOK-Signatur", "Cluster";
BA_DEF_ SG_  "GenSigSwitchedByIgnition" ENUM "No", "Yes";
BA_DEF_ SG_  "Fehlerwert" HEX 0 2147483647;
BA_DEF_ SG_  "GenSigMissingSourceValue" HEX 0 2147483647;
BA_DEF_DEF_  "DBName" "";
BA_DEF_DEF_  "GenNWMApBusSleep" "";
BA_DEF_DEF_  "GenNWMApCanNormal" "";
BA_DEF_DEF_  "GenNWMApCanOff" "";
BA_DEF_DEF_  "GenNWMApCanOn" "";
BA_DEF_DEF_  "GenNWMApCanSleep" "";
BA_DEF_DEF_  "GenNWMApCanWakeUp" "";
BA_DEF_DEF_  "GenNWMGotoMode_Awake" "";
BA_DEF_DEF_  "GenNWMGotoMode_BusSleep" "";
BA_DEF_DEF_  "GenNWMSleepTime" 0;
BA_DEF_DEF_  "GenNWMTalkNM" "";
BA_DEF_DEF_  "Manufacturer" "";
BA_DEF_DEF_  "NmhBaseAddress" 0;
BA_DEF_DEF_  "NmhMessageCount" 1;
BA_DEF_DEF_  "NmType" "None";
BA_DEF_DEF_  "VAGTP20_SetupMessageCount" 0;
BA_DEF_DEF_  "VAGTP20_SetupStartAddress" 0;
BA_DEF_DEF_  "VersionDay" 2;
BA_DEF_DEF_  "VersionMonth" 6;
BA_DEF_DEF_  "VersionWeek" 23;
BA_DEF_DEF_  "VersionYear" 22;
BA_DEF_DEF_  "VersionNumber" 0;
BA_DEF_DEF_  "BusType" "";
BA_DEF_DEF_  "Baudrate" 1;
BA_DEF_DEF_  "SamplePointMin" 1;
BA_DEF_DEF_  "SamplePointMax" 1;
BA_DEF_DEF_  "SyncJumpWidthMin" 1;
BA_DEF_DEF_  "SyncJumpWidthMax" 1;
BA_DEF_DEF_  "NBTMin" 10;
BA_DEF_DEF_  "NBTMax" 20;
BA_DEF_DEF_  "NmhTimeoutTimer" 0;
BA_DEF_DEF_  "NmhWaitBusSleepTimer" 0;
BA_DEF_DEF_  "NmhPrepareBusSleepTimer" 0;
BA_DEF_DEF_  "NmhLongTimer" 0;
BA_DEF_DEF_  "NmhNStart" 0;
BA_DEF_DEF_  "GenNodAutoGenDsp" "Yes";
BA_DEF_DEF_  "GenNodAutoGenSnd" "Yes";
BA_DEF_DEF_  "GenNodSleepTime" 0;
BA_DEF_DEF_  "ILUsed" "Yes";
BA_DEF_DEF_  "ECUVariantDefault" "Yes";
BA_DEF_DEF_  "ECUVariantGroup" "";
BA_DEF_DEF_  "NodeLayerModules" "";
BA_DEF_DEF_  "NmhNode" "Yes";
BA_DEF_DEF_  "NmNode" "No";
BA_DEF_DEF_REL_  "GenSigTimeoutTime" 0;
BA_DEF_DEF_  "DiagRequest" "No";
BA_DEF_DEF_  "DiagResponse" "No";
BA_DEF_DEF_  "DiagState" "No";
BA_DEF_DEF_  "GenMsgChkConstant" 0;
BA_DEF_DEF_  "GenMsgCycleTime" 0;
BA_DEF_DEF_  "GenMsgCycleTimeFast" 0;
BA_DEF_DEF_  "GenMsgDelayTime" 0;
BA_DEF_DEF_  "GenMsgILSupport" "No";
BA_DEF_DEF_  "GenMsgNrOfRepetition" 0;
BA_DEF_DEF_  "GenMsgPDUConstants" "";
BA_DEF_DEF_  "GenMsgSendType" "NoMsgSendType";
BA_DEF_DEF_  "GenMsgStartDelayTime" 0;
BA_DEF_DEF_  "NmMessage" "No";
BA_DEF_DEF_  "NmhMessage" "No";
BA_DEF_DEF_  "MsgType" "Application";
BA_DEF_DEF_  "VAGTP20_API" 0;
BA_DEF_DEF_  "VAGTP20_DynConnection" "No";
BA_DEF_DEF_  "VAGTP20_DynSetup" "No";
BA_DEF_DEF_  "VAGTP20_StatConnection" "No";
BA_DEF_DEF_  "GenSigActiveRepetitions" 0;
BA_DEF_DEF_  "GenSigInactiveValue" 0;
BA_DEF_DEF_  "GenSigSendType" "NoSigSendType";
BA_DEF_DEF_  "GenSigStartValue" 0;
BA_DEF_DEF_  "NWM-WakeupAllowed" "No";
BA_DEF_DEF_  "GenSigFuncType" "NoFunction";
BA_DEF_DEF_  "GenSigSwitchedByIgnition" "Yes";
BA_DEF_DEF_  "Fehlerwert" 0;
BA_DEF_DEF_  "GenSigMissingSourceValue" 0;
BA_  "DBName" "MLBevo_DCAN";
BA_  "GenNWMApBusSleep" "NMIndNetSDN()";
BA_  "GenNWMApCanNormal" "apCanNormal()";
BA_  "GenNWMApCanOff" "NMIndnetOff()";
BA_  "GenNWMApCanOn" "NMIndnetOn()";
BA_  "GenNWMApCanSleep" "apCanSleep()";
BA_  "GenNWMApCanWakeUp" "apCanWakeUp()";
BA_  "GenNWMGotoMode_Awake" "Nmh_ReqNetOn()";
BA_  "GenNWMGotoMode_BusSleep" "Nmh_ReqNetOff()";
BA_  "GenNWMSleepTime" 4000;
BA_  "GenNWMTalkNM" "Nmh_ReqNetOn()";
BA_  "Manufacturer" "VAG";
BA_  "NmhBaseAddress" 452984832;
BA_  "NmhMessageCount" 256;
BA_  "NmType" "NM-High";
BA_  "VAGTP20_SetupMessageCount" 128;
BA_  "VAGTP20_SetupStartAddress" 512;
BA_  "VersionNumber" 2400;
BA_  "BusType" "CAN";
BA_  "Baudrate" 500000;
BA_  "SamplePointMin" 80;
BA_  "SamplePointMax" 84;
BA_  "SyncJumpWidthMin" 2;
BA_  "SyncJumpWidthMax" 4;
BA_  "NmhTimeoutTimer" 1000;
BA_  "NmhWaitBusSleepTimer" 750;
BA_  "NmhPrepareBusSleepTimer" 500;
BA_  "NmhLongTimer" 200;
BA_  "NmhNStart" 20;
BA_ "GenNodSleepTime" BU_ BAP_Tester 4000;
BA_ "ECUVariantGroup" BU_ BAP_Tester "BAP";
BA_ "NmhNode" BU_ BAP_Tester 0;
BA_ "GenNodSleepTime" BU_ CGS 4000;
BA_ "ECUVariantDefault" BU_ CGS 0;
BA_ "ECUVariantGroup" BU_ CGS "Waehlhebel";
BA_ "NodeLayerModules" BU_ CGS "NMHigh.DLL";
BA_ "GenNodSleepTime" BU_ Gateway 4000;
BA_ "ECUVariantGroup" BU_ Gateway "Gateway";
BA_ "NodeLayerModules" BU_ Gateway "NMHigh.DLL";
BA_ "GenNodSleepTime" BU_ Gateway_PAG 4000;
BA_ "ECUVariantDefault" BU_ Gateway_PAG 0;
BA_ "ECUVariantGroup" BU_ Gateway_PAG "Gateway";
BA_ "NodeLayerModules" BU_ Gateway_PAG "NMHigh.DLL";
BA_ "GenNodSleepTime" BU_ HUD 4000;
BA_ "ECUVariantGroup" BU_ HUD "HUD";
BA_ "NodeLayerModules" BU_ HUD "NMHigh.DLL";
BA_ "GenNodSleepTime" BU_ Kombi 4000;
BA_ "ECUVariantGroup" BU_ Kombi "Kombi";
BA_ "NodeLayerModules" BU_ Kombi "NMHigh.DLL";
BA_ "GenNodSleepTime" BU_ Kombi_LB 4000;
BA_ "ECUVariantDefault" BU_ Kombi_LB 0;
BA_ "ECUVariantGroup" BU_ Kombi_LB "Kombi";
BA_ "NodeLayerModules" BU_ Kombi_LB "NMHigh.DLL";
BA_ "GenNodSleepTime" BU_ Kombi_PAG 4000;
BA_ "ECUVariantDefault" BU_ Kombi_PAG 0;
BA_ "ECUVariantGroup" BU_ Kombi_PAG "Kombi";
BA_ "NodeLayerModules" BU_ Kombi_PAG "NMHigh.DLL";
BA_ "GenNodSleepTime" BU_ Waehlhebel_SB 4000;
BA_ "ECUVariantGroup" BU_ Waehlhebel_SB "Waehlhebel";
BA_ "NodeLayerModules" BU_ Waehlhebel_SB "NMHigh.DLL";
BA_ "GenMsgCycleTime" BO_ 2331596020 40;
BA_ "GenMsgILSupport" BO_ 2331596020 1;
BA_ "GenMsgSendType" BO_ 2331596020 0;
BA_ "GenMsgCycleTime" BO_ 678 40;
BA_ "GenMsgILSupport" BO_ 678 1;
BA_ "GenMsgSendType" BO_ 678 0;
BA_ "GenMsgCycleTime" BO_ 679 40;
BA_ "GenMsgILSupport" BO_ 679 1;
BA_ "GenMsgSendType" BO_ 679 0;
BA_ "GenMsgCycleTime" BO_ 680 40;
BA_ "GenMsgILSupport" BO_ 680 1;
BA_ "GenMsgSendType" BO_ 680 0;
BA_ "GenMsgCycleTime" BO_ 681 200;
BA_ "GenMsgDelayTime" BO_ 681 40;
BA_ "GenMsgILSupport" BO_ 681 1;
BA_ "GenMsgSendType" BO_ 681 0;
BA_ "GenMsgCycleTime" BO_ 614 1000;
BA_ "GenMsgILSupport" BO_ 614 1;
BA_ "GenMsgSendType" BO_ 614 0;
BA_ "GenMsgStartDelayTime" BO_ 614 10;
BA_ "GenMsgCycleTime" BO_ 2331595865 80;
BA_ "GenMsgILSupport" BO_ 2331595865 1;
BA_ "GenMsgSendType" BO_ 2331595865 0;
BA_ "GenMsgCycleTime" BO_ 2331595866 80;
BA_ "GenMsgILSupport" BO_ 2331595866 1;
BA_ "GenMsgSendType" BO_ 2331595866 0;
BA_ "GenMsgCycleTime" BO_ 2331595867 80;
BA_ "GenMsgILSupport" BO_ 2331595867 1;
BA_ "GenMsgSendType" BO_ 2331595867 0;
BA_ "GenMsgCycleTime" BO_ 2331595868 80;
BA_ "GenMsgILSupport" BO_ 2331595868 1;
BA_ "GenMsgSendType" BO_ 2331595868 0;
BA_ "GenMsgCycleTime" BO_ 2331595869 80;
BA_ "GenMsgILSupport" BO_ 2331595869 1;
BA_ "GenMsgSendType" BO_ 2331595869 0;
BA_ "GenMsgCycleTime" BO_ 2331595870 80;
BA_ "GenMsgILSupport" BO_ 2331595870 1;
BA_ "GenMsgSendType" BO_ 2331595870 0;
BA_ "GenMsgCycleTime" BO_ 2331595871 80;
BA_ "GenMsgILSupport" BO_ 2331595871 1;
BA_ "GenMsgSendType" BO_ 2331595871 0;
BA_ "GenMsgCycleTime" BO_ 2331595971 80;
BA_ "GenMsgILSupport" BO_ 2331595971 1;
BA_ "GenMsgSendType" BO_ 2331595971 0;
BA_ "GenMsgCycleTime" BO_ 2527679927 960;
BA_ "GenMsgDelayTime" BO_ 2527679927 40;
BA_ "GenMsgILSupport" BO_ 2527679927 1;
BA_ "GenMsgSendType" BO_ 2527679927 0;
BA_ "GenMsgCycleTime" BO_ 232 20;
BA_ "GenMsgILSupport" BO_ 232 1;
BA_ "GenMsgSendType" BO_ 232 0;
BA_ "GenMsgChkConstant" BO_ 1660 223;
BA_ "GenMsgCycleTime" BO_ 1660 1000;
BA_ "GenMsgDelayTime" BO_ 1660 100;
BA_ "GenMsgILSupport" BO_ 1660 1;
BA_ "GenMsgPDUConstants" BO_ 1660 "0xdf,0xdf,0xdf,0xdf,0xdf,0xdf,0xdf,0xdf,0xdf,0xdf,0xdf,0xdf,0xdf,0xdf,0xdf,0xdf";
BA_ "GenMsgSendType" BO_ 1660 0;
BA_ "GenMsgChkConstant" BO_ 64 64;
BA_ "GenMsgCycleTime" BO_ 64 200;
BA_ "GenMsgDelayTime" BO_ 64 10;
BA_ "GenMsgILSupport" BO_ 64 1;
BA_ "GenMsgPDUConstants" BO_ 64 "0x40,0x40,0x40,0x40,0x40,0x40,0x40,0x40,0x40,0x40,0x40,0x40,0x40,0x40,0x40,0x40";
BA_ "GenMsgSendType" BO_ 64 0;
BA_ "GenMsgChkConstant" BO_ 1312 68;
BA_ "GenMsgCycleTime" BO_ 1312 200;
BA_ "GenMsgDelayTime" BO_ 1312 20;
BA_ "GenMsgILSupport" BO_ 1312 1;
BA_ "GenMsgPDUConstants" BO_ 1312 "0x44,0x44,0x44,0x44,0x44,0x44,0x44,0x44,0x44,0x44,0x44,0x44,0x44,0x44,0x44,0x44";
BA_ "GenMsgSendType" BO_ 1312 0;
BA_ "GenMsgCycleTime" BO_ 1349 200;
BA_ "GenMsgDelayTime" BO_ 1349 40;
BA_ "GenMsgILSupport" BO_ 1349 1;
BA_ "GenMsgPDUConstants" BO_ 1349 "0x95,0x19,0xd1,0x36,0x89,0xd4,0x02,0x1e,0xb9,0x80,0xd0,0x22,0x8a,0xf4,0x15,0xb8";
BA_ "GenMsgSendType" BO_ 1349 0;
BA_ "GenMsgCycleTime" BO_ 674 200;
BA_ "GenMsgDelayTime" BO_ 674 20;
BA_ "GenMsgILSupport" BO_ 674 1;
BA_ "GenMsgPDUConstants" BO_ 674 "0x4e,0x87,0xf8,0x61,0xa4,0x94,0x81,0xb1,0x12,0x3a,0x83,0x3d,0x89,0x35,0x3f,0x9e";
BA_ "GenMsgSendType" BO_ 674 0;
BA_ "GenMsgCycleTime" BO_ 1633 100;
BA_ "GenMsgILSupport" BO_ 1633 1;
BA_ "GenMsgSendType" BO_ 1633 0;
BA_ "GenMsgCycleTime" BO_ 345 100;
BA_ "GenMsgDelayTime" BO_ 345 20;
BA_ "GenMsgILSupport" BO_ 345 1;
BA_ "GenMsgSendType" BO_ 345 0;
BA_ "GenMsgCycleTime" BO_ 893 500;
BA_ "GenMsgILSupport" BO_ 893 1;
BA_ "GenMsgSendType" BO_ 893 0;
BA_ "GenMsgCycleTime" BO_ 2589283618 500;
BA_ "GenMsgDelayTime" BO_ 2589283618 100;
BA_ "GenMsgILSupport" BO_ 2589283618 1;
BA_ "GenMsgSendType" BO_ 2589283618 0;
BA_ "GenSigSendType" SG_ 2331596020 ACA_FoD_Status 0;
BA_ "GenSigSendType" SG_ 2331596020 ACC_Charisma_FahrPr 0;
BA_ "GenSigSendType" SG_ 2331596020 ACC_Charisma_Status 0;
BA_ "GenSigSendType" SG_ 2331596020 ACC_Kennlinie_Kurvenregler 0;
BA_ "GenSigSendType" SG_ 2331596020 ACC_Tempolimitassistent_Ein 0;
BA_ "GenSigSendType" SG_ 2331596020 ACC_Texte_03 0;
BA_ "GenSigSendType" SG_ 2331596020 ACC_Texte_Sekundaeranz_03 0;
BA_ "GenSigSendType" SG_ 678 ACA_Querfuehrung 0;
BA_ "GenSigSendType" SG_ 678 ACC_Abstandsindex_02 0;
BA_ "GenSigSendType" SG_ 678 ACC_Anzeige_Zeitluecke 0;
BA_ "GenSigSendType" SG_ 678 ACC_Display_Prio 0;
BA_ "GenSigSendType" SG_ 678 ACC_EGO_Fahrzeug 0;
BA_ "GenSigSendType" SG_ 678 ACC_Gesetzte_Zeitluecke 0;
BA_ "GenSigSendType" SG_ 678 ACC_Optischer_Fahrerhinweis 0;
BA_ "GenSigSendType" SG_ 678 ACC_Regelung_AIO 0;
BA_ "GenSigSendType" SG_ 678 ACC_rel_Objekt_Zusatzanz 0;
BA_ "GenSigSendType" SG_ 678 ACC_Relevantes_Objekt_02 0;
BA_ "GenSigSendType" SG_ 678 ACC_Tempolimit 0;
BA_ "GenSigSendType" SG_ 678 ACC_Texte_Primaeranz_02 0;
BA_ "GenSigSendType" SG_ 678 ACC_Texte_Zusatzanz_02 0;
BA_ "GenSigSendType" SG_ 678 ACC_Warnhinweis 0;
BA_ "GenSigSendType" SG_ 678 ACC_Warnung_Verkehrszeichen_1 0;
BA_ "GenSigSendType" SG_ 678 ACC_Wunschgeschw_02 0;
BA_ "GenSigStartValue" SG_ 678 ACC_Wunschgeschw_02 1023;
BA_ "GenSigSendType" SG_ 678 ACC_Wunschgeschw_erreicht 0;
BA_ "GenSigSendType" SG_ 678 ACC_Wunschgeschw_Farbe 0;
BA_ "GenSigSendType" SG_ 678 STA_Primaeranz 0;
BA_ "GenSigSendType" SG_ 679 ACC_Einheit_maxSetzgeschw 0;
BA_ "GenSigSendType" SG_ 679 ACC_ENG_Texte 0;
BA_ "GenSigSendType" SG_ 679 ACC_Kurvenassistent 0;
BA_ "GenSigSendType" SG_ 679 ACC_maxRegelgeschw 0;
BA_ "GenSigStartValue" SG_ 679 ACC_maxRegelgeschw 255;
BA_ "GenSigSendType" SG_ 679 ACC_maxSetzgeschw 0;
BA_ "GenSigStartValue" SG_ 679 ACC_maxSetzgeschw 511;
BA_ "GenSigSendType" SG_ 679 ACC_minRegelgeschw 0;
BA_ "GenSigStartValue" SG_ 679 ACC_minRegelgeschw 255;
BA_ "GenSigSendType" SG_ 679 ACC_Regelgeschw 0;
BA_ "GenSigStartValue" SG_ 679 ACC_Regelgeschw 1023;
BA_ "GenSigSendType" SG_ 679 ACC_RUV 0;
BA_ "GenSigSendType" SG_ 679 ACC_Status_GRA_Modus 0;
BA_ "GenSigSendType" SG_ 679 ACC_Tachokranz 0;
BA_ "GenSigSendType" SG_ 679 ACC_Tempolimit_Einheit 0;
BA_ "GenSigSendType" SG_ 679 ACC_Tempolimitassistent_02 0;
BA_ "GenSigSendType" SG_ 679 ACC_Typ_Tachokranz_unten 0;
BA_ "GenSigSendType" SG_ 680 AbstWarn_LRR_FAS_Fkt_Status 0;
BA_ "Fehlerwert" SG_ 680 AbstWarn_LRR_FAS_Fkt_Status 3;
BA_ "GenSigSendType" SG_ 680 ACA_Hinweistexte 0;
BA_ "GenSigSendType" SG_ 680 ACA_Querfuehrung_Texte 0;
BA_ "GenSigSendType" SG_ 680 ACC_Abstand_Abstandswarner 0;
BA_ "GenSigStartValue" SG_ 680 ACC_Abstand_Abstandswarner 511;
BA_ "GenSigSendType" SG_ 680 ACC_Akustik_03 0;
BA_ "GenSigSendType" SG_ 680 ACC_Einheit_Abstandswarner 0;
BA_ "GenSigSendType" SG_ 680 ACC_FoD_Status 0;
BA_ "GenSigSendType" SG_ 680 ACC_Geschw_Zielfahrzeug 0;
BA_ "NWM-WakeupAllowed" SG_ 680 ACC_Geschw_Zielfahrzeug 1;
BA_ "GenSigSendType" SG_ 680 ACC_STA_Text 0;
BA_ "GenSigSendType" SG_ 680 ACC_Status_Anzeige 0;
BA_ "GenSigSendType" SG_ 680 ACC_Texte 0;
BA_ "GenSigSendType" SG_ 680 ACC_Texte_Abstandswarner 0;
BA_ "GenSigSendType" SG_ 680 ACC_Texte_Sekundaeranz 0;
BA_ "GenSigSendType" SG_ 680 ACC_Vorz_Abstandswarner 0;
BA_ "GenSigSendType" SG_ 680 ACC_Zeitluecke_Abstandswarner 0;
BA_ "GenSigStartValue" SG_ 680 ACC_Zeitluecke_Abstandswarner 63;
BA_ "GenSigSendType" SG_ 680 FAS_Licht_Anf 0;
BA_ "GenSigSendType" SG_ 680 STA_Texte 0;
BA_ "GenSigSendType" SG_ 680 STA_Zusatzanz 0;
BA_ "GenSigSendType" SG_ 681 ACC_Status_Kurvenassistent 3;
BA_ "Fehlerwert" SG_ 681 ACC_Status_Kurvenassistent 5;
BA_ "GenSigSendType" SG_ 681 ACC_Status_Tempolimitassistent 3;
BA_ "Fehlerwert" SG_ 681 ACC_Status_Tempolimitassistent 4;
BA_ "GenSigSendType" SG_ 681 AWV_Einstellung_System_FSG 3;
BA_ "GenSigSendType" SG_ 681 AWV_Einstellung_Warnung_FSG 3;
BA_ "GenSigSendType" SG_ 681 AWV_LED_Leiste 3;
BA_ "GenSigSendType" SG_ 681 AWV_Status_Anzeige 3;
BA_ "GenSigSendType" SG_ 681 AWV_Texte 3;
BA_ "GenSigSendType" SG_ 681 AWV_Warnlevel 3;
BA_ "GenSigSendType" SG_ 681 AWV_Warnung 3;
BA_ "GenSigSendType" SG_ 614 ACC_Fahrprogramm_PACC 0;
BA_ "GenSigSendType" SG_ 614 ACC_Nutzung_VZ_PACC 0;
BA_ "GenSigSendType" SG_ 614 ACC_Offset_Default_PACC 0;
BA_ "GenSigStartValue" SG_ 614 ACC_Offset_Default_PACC 255;
BA_ "GenSigSendType" SG_ 614 ACC_PEA_Einheit_Geschw 0;
BA_ "GenSigSendType" SG_ 614 ACC_PEA_LernenderFahrerOffset 0;
BA_ "Fehlerwert" SG_ 614 ACC_PEA_LernenderFahrerOffset 63;
BA_ "GenSigSendType" SG_ 614 ACC_Regelung_durch_PACC 0;
BA_ "GenSigSendType" SG_ 614 ACC_Sensibilitaet_PACC 0;
BA_ "GenSigSendType" SG_ 614 ACC_vLimit1_PACC 0;
BA_ "GenSigSendType" SG_ 2331595865 ACC_HMI_Obj_01_dx 0;
BA_ "GenSigSendType" SG_ 2331595865 ACC_HMI_Obj_01_dy 0;
BA_ "GenSigSendType" SG_ 2331595865 ACC_HMI_Obj_01_LaengsRegelung 0;
BA_ "GenSigSendType" SG_ 2331595865 ACC_HMI_Obj_01_QuerRegelung 0;
BA_ "GenSigSendType" SG_ 2331595865 ACC_HMI_Obj_01_Spurzuordnung 0;
BA_ "GenSigSendType" SG_ 2331595865 ACC_HMI_Obj_01_Typ 0;
BA_ "GenSigSendType" SG_ 2331595865 ACC_HMI_Obj_02_dx 0;
BA_ "GenSigSendType" SG_ 2331595865 ACC_HMI_Obj_02_dy 0;
BA_ "GenSigSendType" SG_ 2331595865 ACC_HMI_Obj_02_LaengsRegelung 0;
BA_ "GenSigSendType" SG_ 2331595865 ACC_HMI_Obj_02_QuerRegelung 0;
BA_ "GenSigSendType" SG_ 2331595865 ACC_HMI_Obj_02_Spurzuordnung 0;
BA_ "GenSigSendType" SG_ 2331595865 ACC_HMI_Obj_02_Typ 0;
BA_ "GenSigSendType" SG_ 2331595866 ACC_HMI_Obj_03_dx 0;
BA_ "GenSigSendType" SG_ 2331595866 ACC_HMI_Obj_03_dy 0;
BA_ "GenSigSendType" SG_ 2331595866 ACC_HMI_Obj_03_LaengsRegelung 0;
BA_ "GenSigSendType" SG_ 2331595866 ACC_HMI_Obj_03_QuerRegelung 0;
BA_ "GenSigSendType" SG_ 2331595866 ACC_HMI_Obj_03_Spurzuordnung 0;
BA_ "GenSigSendType" SG_ 2331595866 ACC_HMI_Obj_03_Typ 0;
BA_ "GenSigSendType" SG_ 2331595866 ACC_HMI_Obj_04_dx 0;
BA_ "GenSigSendType" SG_ 2331595866 ACC_HMI_Obj_04_dy 0;
BA_ "GenSigSendType" SG_ 2331595866 ACC_HMI_Obj_04_LaengsRegelung 0;
BA_ "GenSigSendType" SG_ 2331595866 ACC_HMI_Obj_04_QuerRegelung 0;
BA_ "GenSigSendType" SG_ 2331595866 ACC_HMI_Obj_04_Spurzuordnung 0;
BA_ "GenSigSendType" SG_ 2331595866 ACC_HMI_Obj_04_Typ 0;
BA_ "GenSigSendType" SG_ 2331595867 ACC_HMI_Obj_05_dx 0;
BA_ "GenSigSendType" SG_ 2331595867 ACC_HMI_Obj_05_dy 0;
BA_ "GenSigSendType" SG_ 2331595867 ACC_HMI_Obj_05_LaengsRegelung 0;
BA_ "GenSigSendType" SG_ 2331595867 ACC_HMI_Obj_05_QuerRegelung 0;
BA_ "GenSigSendType" SG_ 2331595867 ACC_HMI_Obj_05_Spurzuordnung 0;
BA_ "GenSigSendType" SG_ 2331595867 ACC_HMI_Obj_05_Typ 0;
BA_ "GenSigSendType" SG_ 2331595867 ACC_HMI_Obj_06_dx 0;
BA_ "GenSigSendType" SG_ 2331595867 ACC_HMI_Obj_06_dy 0;
BA_ "GenSigSendType" SG_ 2331595867 ACC_HMI_Obj_06_LaengsRegelung 0;
BA_ "GenSigSendType" SG_ 2331595867 ACC_HMI_Obj_06_QuerRegelung 0;
BA_ "GenSigSendType" SG_ 2331595867 ACC_HMI_Obj_06_Spurzuordnung 0;
BA_ "GenSigSendType" SG_ 2331595867 ACC_HMI_Obj_06_Typ 0;
BA_ "GenSigSendType" SG_ 2331595868 ACC_HMI_Nachb_li_belegt 0;
BA_ "GenSigSendType" SG_ 2331595868 ACC_HMI_Nachb_re_belegt 0;
BA_ "GenSigSendType" SG_ 2331595868 ACC_HMI_Seg1_Gierwinkel 0;
BA_ "GenSigSendType" SG_ 2331595868 ACC_HMI_Seg1_Kruemmung 0;
BA_ "GenSigSendType" SG_ 2331595868 ACC_HMI_Seg2_Beginn 0;
BA_ "GenSigSendType" SG_ 2331595868 ACC_HMI_Seg2_Kruemmung 0;
BA_ "GenSigSendType" SG_ 2331595868 ACC_HMI_Spurwechsel_li 0;
BA_ "GenSigSendType" SG_ 2331595868 ACC_HMI_Spurwechsel_re 0;
BA_ "GenSigSendType" SG_ 2331595869 ACC_HMI_Ego_li_Seg1_QuerAbst 0;
BA_ "GenSigSendType" SG_ 2331595869 ACC_HMI_Ego_re_Seg1_QuerAbst 0;
BA_ "GenSigSendType" SG_ 2331595869 ACC_HMI_Egospur_li_Typ 0;
BA_ "GenSigSendType" SG_ 2331595869 ACC_HMI_Egospur_re_Typ 0;
BA_ "GenSigSendType" SG_ 2331595869 ACC_HMI_Nachb_li_Seg1_QuerAbst 0;
BA_ "GenSigSendType" SG_ 2331595869 ACC_HMI_Nachb_li_Typ 0;
BA_ "GenSigSendType" SG_ 2331595869 ACC_HMI_Nachb_re_Seg1_QuerAbst 0;
BA_ "GenSigSendType" SG_ 2331595869 ACC_HMI_Nachb_re_Typ 0;
BA_ "GenSigSendType" SG_ 2331595870 ACC_HMI_TrajektSeg1_Gierwinkel 0;
BA_ "GenSigSendType" SG_ 2331595870 ACC_HMI_TrajektSeg1_Kruemmung 0;
BA_ "GenSigSendType" SG_ 2331595870 ACC_HMI_TrajektSeg1_QuerAbst 0;
BA_ "GenSigSendType" SG_ 2331595870 ACC_HMI_TrajektSeg1_Valid 0;
BA_ "GenSigSendType" SG_ 2331595870 ACC_HMI_TrajektSeg2_Beginn 0;
BA_ "GenSigSendType" SG_ 2331595870 ACC_HMI_TrajektSeg2_Kruemmung 0;
BA_ "GenSigSendType" SG_ 2331595871 ACC_HMI_EgoObj_dy 0;
BA_ "GenSigSendType" SG_ 2331595871 ACC_HMI_Kurvenwarnung 0;
BA_ "GenSigSendType" SG_ 2331595871 ACC_HMI_TrajektFarbe_li 0;
BA_ "GenSigSendType" SG_ 2331595871 ACC_HMI_TrajektFarbe_re 0;
BA_ "GenSigSendType" SG_ 2331595871 ACC_HMI_TrajektVorausschau 0;
BA_ "GenSigSendType" SG_ 2331595871 ACC_HMI_Zoomstufe 0;
BA_ "GenSigSendType" SG_ 2331595871 ACC_HMI_ZoomstufeAktiv 0;
BA_ "GenSigSendType" SG_ 2331595971 ACC_HMI_Zeitluecke_01_dx 0;
BA_ "GenSigSendType" SG_ 2331595971 ACC_HMI_Zeitluecke_02_dx 0;
BA_ "GenSigSendType" SG_ 2331595971 ACC_HMI_Zeitluecke_03_dx 0;
BA_ "GenSigSendType" SG_ 2331595971 ACC_HMI_Zeitluecke_04_dx 0;
BA_ "GenSigSendType" SG_ 2331595971 ACC_HMI_Zeitluecke_05_dx 0;
BA_ "GenSigSendType" SG_ 2331595971 ACC_HMI_ZeitlueckenAuswahl 0;
BA_ "GenSigSendType" SG_ 2527679927 ADA_AttentionLevel 3;
BA_ "GenSigStartValue" SG_ 2527679927 ADA_AttentionLevel 126;
BA_ "Fehlerwert" SG_ 2527679927 ADA_AttentionLevel 127;
BA_ "GenSigSendType" SG_ 2527679927 ADA_DistractionLevel 3;
BA_ "GenSigStartValue" SG_ 2527679927 ADA_DistractionLevel 126;
BA_ "Fehlerwert" SG_ 2527679927 ADA_DistractionLevel 127;
BA_ "GenSigSendType" SG_ 2527679927 ADA_DrowsinessLevel 3;
BA_ "GenSigStartValue" SG_ 2527679927 ADA_DrowsinessLevel 126;
BA_ "Fehlerwert" SG_ 2527679927 ADA_DrowsinessLevel 127;
BA_ "GenSigSendType" SG_ 2527679927 ADA_DrowsinessSystemState 3;
BA_ "GenSigSendType" SG_ 2527679927 ADA_HMI_Ablenkung_Deaktivierung 3;
BA_ "GenSigSendType" SG_ 2527679927 ADA_HMI_Ablenkung_Fehler_Popup 3;
BA_ "GenSigSendType" SG_ 2527679927 ADA_HMI_Ablenkung_Meldeakustik 3;
BA_ "GenSigSendType" SG_ 2527679927 ADA_HMI_Ablenkung_Meldung 3;
BA_ "GenSigSendType" SG_ 2527679927 ADA_HMI_Fahrzeit_seit_Pause 3;
BA_ "GenSigSendType" SG_ 2527679927 ADA_HMI_Muedigkeit_Deaktivierung 3;
BA_ "GenSigSendType" SG_ 2527679927 ADA_HMI_Muedigkeit_Event_Meldung 3;
BA_ "GenSigSendType" SG_ 2527679927 ADA_HMI_Muedigkeit_Fehler_Popup 3;
BA_ "GenSigSendType" SG_ 2527679927 ADA_HMI_Muedigkeit_Meldeakustik 3;
BA_ "GenSigSendType" SG_ 2527679927 ADA_HMI_Muedigkeit_Meldung 3;
BA_ "GenSigSendType" SG_ 232 AFR_gMeter_ax 0;
BA_ "GenSigStartValue" SG_ 232 AFR_gMeter_ax 1022;
BA_ "Fehlerwert" SG_ 232 AFR_gMeter_ax 1023;
BA_ "GenSigSendType" SG_ 232 AFR_gMeter_ay 0;
BA_ "GenSigStartValue" SG_ 232 AFR_gMeter_ay 1022;
BA_ "Fehlerwert" SG_ 232 AFR_gMeter_ay 1023;
BA_ "GenSigSendType" SG_ 232 AFR_Schluesselsuche_Anf 0;
BA_ "GenSigSwitchedByIgnition" SG_ 232 AFR_Schluesselsuche_Anf 0;
BA_ "GenSigSendType" SG_ 232 AFR_Standfkt_Status 0;
BA_ "GenSigSwitchedByIgnition" SG_ 232 AFR_Standfkt_Status 0;
BA_ "GenSigSendType" SG_ 232 AFR_StandfktSchluesselAktivieren 0;
BA_ "GenSigSwitchedByIgnition" SG_ 232 AFR_StandfktSchluesselAktivieren 0;
BA_ "GenSigSendType" SG_ 1660 AGA_01_BZ 0;
BA_ "GenSigFuncType" SG_ 1660 AGA_01_BZ 1;
BA_ "GenSigSendType" SG_ 1660 AGA_01_CRC 0;
BA_ "GenSigFuncType" SG_ 1660 AGA_01_CRC 2;
BA_ "GenSigSendType" SG_ 1660 AGA_Charisma_FahrPr 3;
BA_ "GenSigSendType" SG_ 1660 AGA_Charisma_Status 3;
BA_ "GenSigSendType" SG_ 1660 AGA_Verstaerker_Mute 0;
BA_ "GenSigSendType" SG_ 1660 E_Sound_Mute_Icon 3;
BA_ "GenSigStartValue" SG_ 1660 E_Sound_Mute_Icon 3;
BA_ "GenSigSendType" SG_ 1660 E_Sound_Mute_LED 3;
BA_ "GenSigStartValue" SG_ 1660 E_Sound_Mute_LED 3;
BA_ "GenSigSendType" SG_ 1660 E_Sound_ohne_Funktion 3;
BA_ "Fehlerwert" SG_ 1660 E_Sound_ohne_Funktion 1;
BA_ "GenSigSendType" SG_ 1660 E_Sound_Texte 3;
BA_ "Fehlerwert" SG_ 1660 E_Sound_Texte 7;
BA_ "GenSigSendType" SG_ 1660 E_Sound_verbaut 0;
BA_ "GenSigSendType" SG_ 64 AB_Anzeige_Fussg 3;
BA_ "GenSigSwitchedByIgnition" SG_ 64 AB_Anzeige_Fussg 0;
BA_ "GenSigSendType" SG_ 64 AB_Belegung_VF 0;
BA_ "GenSigSwitchedByIgnition" SG_ 64 AB_Belegung_VF 0;
BA_ "Fehlerwert" SG_ 64 AB_Belegung_VF 1;
BA_ "GenSigSendType" SG_ 64 AB_Crash_Int 3;
BA_ "GenSigSwitchedByIgnition" SG_ 64 AB_Crash_Int 0;
BA_ "GenSigSendType" SG_ 64 AB_Deaktiviert 0;
BA_ "GenSigSwitchedByIgnition" SG_ 64 AB_Deaktiviert 0;
BA_ "GenSigSendType" SG_ 64 AB_Deaktivierung_HV 0;
BA_ "GenSigSwitchedByIgnition" SG_ 64 AB_Deaktivierung_HV 0;
BA_ "Fehlerwert" SG_ 64 AB_Deaktivierung_HV 7;
BA_ "GenSigSendType" SG_ 64 AB_Diagnose 0;
BA_ "GenSigSwitchedByIgnition" SG_ 64 AB_Diagnose 0;
BA_ "GenSigSendType" SG_ 64 AB_EDR_Trigger 0;
BA_ "GenSigSwitchedByIgnition" SG_ 64 AB_EDR_Trigger 0;
BA_ "GenSigSendType" SG_ 64 AB_Erh_Auf_VB 3;
BA_ "GenSigSwitchedByIgnition" SG_ 64 AB_Erh_Auf_VB 0;
BA_ "GenSigSendType" SG_ 64 AB_Front_Crash 0;
BA_ "GenSigSwitchedByIgnition" SG_ 64 AB_Front_Crash 0;
BA_ "GenSigSendType" SG_ 64 AB_Gurtwarn_VB 3;
BA_ "GenSigSwitchedByIgnition" SG_ 64 AB_Gurtwarn_VB 0;
BA_ "GenSigSendType" SG_ 64 AB_Gurtwarn_VF 3;
BA_ "GenSigSwitchedByIgnition" SG_ 64 AB_Gurtwarn_VF 0;
BA_ "GenSigSendType" SG_ 64 AB_Heck_Crash 0;
BA_ "GenSigSwitchedByIgnition" SG_ 64 AB_Heck_Crash 0;
BA_ "GenSigSendType" SG_ 64 AB_Lampe 3;
BA_ "GenSigStartValue" SG_ 64 AB_Lampe 1;
BA_ "GenSigSwitchedByIgnition" SG_ 64 AB_Lampe 0;
BA_ "GenSigSendType" SG_ 64 AB_MKB_Anforderung 0;
BA_ "GenSigSwitchedByIgnition" SG_ 64 AB_MKB_Anforderung 0;
BA_ "GenSigSendType" SG_ 64 AB_MKB_gueltig 0;
BA_ "GenSigSwitchedByIgnition" SG_ 64 AB_MKB_gueltig 0;
BA_ "GenSigSendType" SG_ 64 AB_RGS_Anst 0;
BA_ "GenSigStartValue" SG_ 64 AB_RGS_Anst 8;
BA_ "GenSigSwitchedByIgnition" SG_ 64 AB_RGS_Anst 0;
BA_ "GenSigSendType" SG_ 64 AB_Rollover_Crash 0;
BA_ "GenSigSwitchedByIgnition" SG_ 64 AB_Rollover_Crash 0;
BA_ "GenSigSendType" SG_ 64 AB_SB_Crash 0;
BA_ "GenSigSwitchedByIgnition" SG_ 64 AB_SB_Crash 0;
BA_ "GenSigSendType" SG_ 64 AB_SF_Crash 0;
BA_ "GenSigSwitchedByIgnition" SG_ 64 AB_SF_Crash 0;
BA_ "GenSigSendType" SG_ 64 AB_Stellgliedtest 3;
BA_ "GenSigSwitchedByIgnition" SG_ 64 AB_Stellgliedtest 0;
BA_ "GenSigSendType" SG_ 64 AB_Systemfehler 3;
BA_ "GenSigSwitchedByIgnition" SG_ 64 AB_Systemfehler 0;
BA_ "GenSigSendType" SG_ 64 AB_Texte_AKS 3;
BA_ "GenSigSwitchedByIgnition" SG_ 64 AB_Texte_AKS 0;
BA_ "GenSigSendType" SG_ 64 AB_VB_deaktiviert 0;
BA_ "GenSigStartValue" SG_ 64 AB_VB_deaktiviert 1;
BA_ "GenSigSwitchedByIgnition" SG_ 64 AB_VB_deaktiviert 0;
BA_ "GenSigSendType" SG_ 64 AB_Versorgungsspannung 3;
BA_ "GenSigSwitchedByIgnition" SG_ 64 AB_Versorgungsspannung 0;
BA_ "GenSigSendType" SG_ 64 Airbag_01_BZ 0;
BA_ "GenSigFuncType" SG_ 64 Airbag_01_BZ 1;
BA_ "GenSigSwitchedByIgnition" SG_ 64 Airbag_01_BZ 0;
BA_ "GenSigSendType" SG_ 64 Airbag_01_CRC 0;
BA_ "GenSigFuncType" SG_ 64 Airbag_01_CRC 2;
BA_ "GenSigSwitchedByIgnition" SG_ 64 Airbag_01_CRC 0;
BA_ "GenSigSendType" SG_ 64 SC_LowSpeedCrashErkannt 0;
BA_ "GenSigSwitchedByIgnition" SG_ 64 SC_LowSpeedCrashErkannt 0;
BA_ "GenSigSendType" SG_ 64 SC_Masterzeit 0;
BA_ "GenSigStartValue" SG_ 64 SC_Masterzeit 127;
BA_ "GenSigSendType" SG_ 64 SC_Masterzeit_Offset 0;
BA_ "GenSigSendType" SG_ 1312 AB_Abschaltanf_SIH_BF 3;
BA_ "GenSigSendType" SG_ 1312 AB_Anforderung_eCall 0;
BA_ "GenSigSwitchedByIgnition" SG_ 1312 AB_Anforderung_eCall 0;
BA_ "GenSigSendType" SG_ 1312 AB_Anforderung_USM 0;
BA_ "GenSigSwitchedByIgnition" SG_ 1312 AB_Anforderung_USM 0;
BA_ "GenSigSendType" SG_ 1312 AB_Anprall_FGS 3;
BA_ "GenSigSendType" SG_ 1312 AB_Anprall_Front_Beifahrer 3;
BA_ "GenSigSendType" SG_ 1312 AB_Anprall_Front_Fahrer 3;
BA_ "GenSigSendType" SG_ 1312 AB_Anprall_Heck_Beifahrer 3;
BA_ "GenSigSendType" SG_ 1312 AB_Anprall_Heck_Fahrer 3;
BA_ "GenSigSendType" SG_ 1312 AB_Anprall_Rollover 3;
BA_ "GenSigSendType" SG_ 1312 AB_Anprall_Seite_Beifahrer 3;
BA_ "GenSigSendType" SG_ 1312 AB_Anprall_Seite_Fahrer 3;
BA_ "GenSigSendType" SG_ 1312 AB_Belegung_VB 0;
BA_ "GenSigSwitchedByIgnition" SG_ 1312 AB_Belegung_VB 0;
BA_ "Fehlerwert" SG_ 1312 AB_Belegung_VB 1;
BA_ "GenSigSendType" SG_ 1312 AB_Crashschwere 3;
BA_ "GenSigSwitchedByIgnition" SG_ 1312 AB_Crashschwere 0;
BA_ "Fehlerwert" SG_ 1312 AB_Crashschwere 7;
BA_ "GenSigSendType" SG_ 1312 AB_Gurtschloss_BF 3;
BA_ "GenSigStartValue" SG_ 1312 AB_Gurtschloss_BF 1;
BA_ "GenSigSwitchedByIgnition" SG_ 1312 AB_Gurtschloss_BF 0;
BA_ "GenSigSendType" SG_ 1312 AB_Gurtschloss_FA 3;
BA_ "GenSigStartValue" SG_ 1312 AB_Gurtschloss_FA 1;
BA_ "GenSigSwitchedByIgnition" SG_ 1312 AB_Gurtschloss_FA 0;
BA_ "GenSigSendType" SG_ 1312 AB_Gurtschloss_Reihe2_BF 3;
BA_ "GenSigStartValue" SG_ 1312 AB_Gurtschloss_Reihe2_BF 1;
BA_ "GenSigSwitchedByIgnition" SG_ 1312 AB_Gurtschloss_Reihe2_BF 0;
BA_ "GenSigSendType" SG_ 1312 AB_Gurtschloss_Reihe2_FA 3;
BA_ "GenSigStartValue" SG_ 1312 AB_Gurtschloss_Reihe2_FA 1;
BA_ "GenSigSwitchedByIgnition" SG_ 1312 AB_Gurtschloss_Reihe2_FA 0;
BA_ "GenSigSendType" SG_ 1312 AB_Gurtschloss_Reihe2_MI 3;
BA_ "GenSigStartValue" SG_ 1312 AB_Gurtschloss_Reihe2_MI 1;
BA_ "GenSigSwitchedByIgnition" SG_ 1312 AB_Gurtschloss_Reihe2_MI 0;
BA_ "GenSigSendType" SG_ 1312 AB_Gurtschloss_Reihe3_BF 3;
BA_ "GenSigStartValue" SG_ 1312 AB_Gurtschloss_Reihe3_BF 1;
BA_ "GenSigSwitchedByIgnition" SG_ 1312 AB_Gurtschloss_Reihe3_BF 0;
BA_ "GenSigSendType" SG_ 1312 AB_Gurtschloss_Reihe3_FA 3;
BA_ "GenSigStartValue" SG_ 1312 AB_Gurtschloss_Reihe3_FA 1;
BA_ "GenSigSwitchedByIgnition" SG_ 1312 AB_Gurtschloss_Reihe3_FA 0;
BA_ "GenSigSendType" SG_ 1312 AB_Gurtschloss_Reihe3_MI 3;
BA_ "GenSigStartValue" SG_ 1312 AB_Gurtschloss_Reihe3_MI 1;
BA_ "GenSigSwitchedByIgnition" SG_ 1312 AB_Gurtschloss_Reihe3_MI 0;
BA_ "GenSigSendType" SG_ 1312 AB_Sitzpos_Sens_BF 0;
BA_ "GenSigSwitchedByIgnition" SG_ 1312 AB_Sitzpos_Sens_BF 0;
BA_ "Fehlerwert" SG_ 1312 AB_Sitzpos_Sens_BF 1;
BA_ "GenSigSendType" SG_ 1312 AB_Sitzpos_Sens_FA 0;
BA_ "GenSigSwitchedByIgnition" SG_ 1312 AB_Sitzpos_Sens_FA 0;
BA_ "Fehlerwert" SG_ 1312 AB_Sitzpos_Sens_FA 1;
BA_ "GenSigSendType" SG_ 1312 AB_Wickelklappung_Reihe2_BF 3;
BA_ "GenSigStartValue" SG_ 1312 AB_Wickelklappung_Reihe2_BF 1;
BA_ "GenSigSwitchedByIgnition" SG_ 1312 AB_Wickelklappung_Reihe2_BF 0;
BA_ "GenSigSendType" SG_ 1312 AB_Wickelklappung_Reihe2_FA 3;
BA_ "GenSigStartValue" SG_ 1312 AB_Wickelklappung_Reihe2_FA 1;
BA_ "GenSigSwitchedByIgnition" SG_ 1312 AB_Wickelklappung_Reihe2_FA 0;
BA_ "GenSigSendType" SG_ 1312 AB_Wickelklappung_Reihe2_MI 3;
BA_ "GenSigStartValue" SG_ 1312 AB_Wickelklappung_Reihe2_MI 1;
BA_ "GenSigSwitchedByIgnition" SG_ 1312 AB_Wickelklappung_Reihe2_MI 0;
BA_ "GenSigSendType" SG_ 1312 Airbag_02_BZ 0;
BA_ "GenSigFuncType" SG_ 1312 Airbag_02_BZ 1;
BA_ "GenSigSwitchedByIgnition" SG_ 1312 Airbag_02_BZ 0;
BA_ "GenSigSendType" SG_ 1312 Airbag_02_CRC 0;
BA_ "GenSigFuncType" SG_ 1312 Airbag_02_CRC 2;
BA_ "GenSigSwitchedByIgnition" SG_ 1312 Airbag_02_CRC 0;
BA_ "GenSigSendType" SG_ 1312 LoGeWa_Event_Kombiwarnung 3;
BA_ "GenSigSwitchedByIgnition" SG_ 1312 LoGeWa_Event_Kombiwarnung 0;
BA_ "GenSigSendType" SG_ 1312 SC_PAO_OFF_Anf 0;
BA_ "GenSigSwitchedByIgnition" SG_ 1312 SC_PAO_OFF_Anf 0;
BA_ "GenSigSendType" SG_ 1312 SC_PAO_ON_Anf 0;
BA_ "GenSigSwitchedByIgnition" SG_ 1312 SC_PAO_ON_Anf 0;
BA_ "GenSigSendType" SG_ 1312 SC_PAO_Schriftzug_Anf 0;
BA_ "GenSigSwitchedByIgnition" SG_ 1312 SC_PAO_Schriftzug_Anf 0;
BA_ "GenSigSendType" SG_ 1349 AB_Gurtwarn_Reihe2_BF 3;
BA_ "GenSigSwitchedByIgnition" SG_ 1349 AB_Gurtwarn_Reihe2_BF 0;
BA_ "GenSigSendType" SG_ 1349 AB_Gurtwarn_Reihe2_FA 3;
BA_ "GenSigSwitchedByIgnition" SG_ 1349 AB_Gurtwarn_Reihe2_FA 0;
BA_ "GenSigSendType" SG_ 1349 AB_Gurtwarn_Reihe2_MI 3;
BA_ "GenSigSwitchedByIgnition" SG_ 1349 AB_Gurtwarn_Reihe2_MI 0;
BA_ "GenSigSendType" SG_ 1349 AB_Gurtwarn_Reihe3_BF 3;
BA_ "GenSigSwitchedByIgnition" SG_ 1349 AB_Gurtwarn_Reihe3_BF 0;
BA_ "GenSigSendType" SG_ 1349 AB_Gurtwarn_Reihe3_FA 3;
BA_ "GenSigSwitchedByIgnition" SG_ 1349 AB_Gurtwarn_Reihe3_FA 0;
BA_ "GenSigSendType" SG_ 1349 AB_Gurtwarn_Reihe3_MI 3;
BA_ "GenSigSwitchedByIgnition" SG_ 1349 AB_Gurtwarn_Reihe3_MI 0;
BA_ "GenSigSendType" SG_ 1349 AB_SBR_hinten_verbau 0;
BA_ "GenSigStartValue" SG_ 1349 AB_SBR_hinten_verbau 3;
BA_ "GenSigSwitchedByIgnition" SG_ 1349 AB_SBR_hinten_verbau 0;
BA_ "GenSigSendType" SG_ 1349 AbstWarn_MV_FAS_Fkt_Status 3;
BA_ "GenSigSwitchedByIgnition" SG_ 1349 AbstWarn_MV_FAS_Fkt_Status 0;
BA_ "Fehlerwert" SG_ 1349 AbstWarn_MV_FAS_Fkt_Status 3;
BA_ "GenSigSendType" SG_ 1349 AWV_Einstellung_System_ASG 3;
BA_ "GenSigSwitchedByIgnition" SG_ 1349 AWV_Einstellung_System_ASG 0;
BA_ "GenSigSendType" SG_ 1349 AWV_Einstellung_Warnung_ASG 3;
BA_ "GenSigSwitchedByIgnition" SG_ 1349 AWV_Einstellung_Warnung_ASG 0;
BA_ "GenSigSendType" SG_ 1349 LGI_FAS_Fkt_Status 3;
BA_ "GenSigSwitchedByIgnition" SG_ 1349 LGI_FAS_Fkt_Status 0;
BA_ "Fehlerwert" SG_ 1349 LGI_FAS_Fkt_Status 3;
BA_ "GenSigSendType" SG_ 1349 PreCrash_FAS_Fkt_Status 3;
BA_ "GenSigSwitchedByIgnition" SG_ 1349 PreCrash_FAS_Fkt_Status 0;
BA_ "Fehlerwert" SG_ 1349 PreCrash_FAS_Fkt_Status 3;
BA_ "GenSigSendType" SG_ 1349 SC_PreSense_Modus_System_KAS 3;
BA_ "GenSigSwitchedByIgnition" SG_ 1349 SC_PreSense_Modus_System_KAS 0;
BA_ "GenSigSendType" SG_ 1349 SC_PreSense_Modus_System_MV 3;
BA_ "GenSigSwitchedByIgnition" SG_ 1349 SC_PreSense_Modus_System_MV 0;
BA_ "GenSigSendType" SG_ 1349 SC_PreSense_Modus_System_NV 3;
BA_ "GenSigSwitchedByIgnition" SG_ 1349 SC_PreSense_Modus_System_NV 0;
BA_ "GenSigSendType" SG_ 1349 SC_PreSense_Modus_Warnung_MV 3;
BA_ "GenSigSwitchedByIgnition" SG_ 1349 SC_PreSense_Modus_Warnung_MV 0;
BA_ "GenSigSendType" SG_ 1349 SC_PreSense_Modus_Warnung_NV 3;
BA_ "GenSigSwitchedByIgnition" SG_ 1349 SC_PreSense_Modus_Warnung_NV 0;
BA_ "GenSigSendType" SG_ 1349 WarnBrems_Charisma_FahrPr 0;
BA_ "GenSigSendType" SG_ 1349 WarnBrems_Charisma_Status 0;
BA_ "GenSigSendType" SG_ 674 Allrad_06_BZ 0;
BA_ "GenSigFuncType" SG_ 674 Allrad_06_BZ 1;
BA_ "GenSigSendType" SG_ 674 Allrad_06_CRC 0;
BA_ "GenSigFuncType" SG_ 674 Allrad_06_CRC 2;
BA_ "GenSigSendType" SG_ 674 ALR_Charisma_FahrPr 0;
BA_ "GenSigSendType" SG_ 674 ALR_Charisma_Status 0;
BA_ "GenSigSendType" SG_ 674 ALR_Ist_Proz_Anz 0;
BA_ "GenSigStartValue" SG_ 674 ALR_Ist_Proz_Anz 254;
BA_ "Fehlerwert" SG_ 674 ALR_Ist_Proz_Anz 255;
BA_ "GenSigSendType" SG_ 674 ALR_Kuehlbedarf 0;
BA_ "GenSigSendType" SG_ 674 ALR_OBD_Status 0;
BA_ "GenSigSendType" SG_ 674 ALR_Schalten 0;
BA_ "GenSigSendType" SG_ 674 ALR_Sta_Disconnect 0;
BA_ "GenSigSendType" SG_ 674 ALR_Texte 3;
BA_ "GenSigSendType" SG_ 674 ALR_v_Begrenzung 0;
BA_ "GenSigStartValue" SG_ 674 ALR_v_Begrenzung 31;
BA_ "GenSigSendType" SG_ 674 ALR_Vorwarnung 0;
BA_ "GenSigSendType" SG_ 674 ALR_Warnlampe 3;
BA_ "GenSigSendType" SG_ 1633 AAG_Anhaenger_abgesteckt 0;
BA_ "GenSigSwitchedByIgnition" SG_ 1633 AAG_Anhaenger_abgesteckt 0;
BA_ "GenSigSendType" SG_ 1633 AAG_Anhaenger_erkannt 0;
BA_ "NWM-WakeupAllowed" SG_ 1633 AAG_Anhaenger_erkannt 1;
BA_ "GenSigSwitchedByIgnition" SG_ 1633 AAG_Anhaenger_erkannt 0;
BA_ "GenSigSendType" SG_ 1633 AAG_AVS_Fehler_02 0;
BA_ "GenSigSwitchedByIgnition" SG_ 1633 AAG_AVS_Fehler_02 0;
BA_ "Fehlerwert" SG_ 1633 AAG_AVS_Fehler_02 1;
BA_ "GenSigSendType" SG_ 1633 AAG_AVS_Fehler_02_inv 0;
BA_ "GenSigStartValue" SG_ 1633 AAG_AVS_Fehler_02_inv 1;
BA_ "GenSigSwitchedByIgnition" SG_ 1633 AAG_AVS_Fehler_02_inv 0;
BA_ "GenSigSendType" SG_ 1633 AAG_AVS_Stati 0;
BA_ "GenSigSwitchedByIgnition" SG_ 1633 AAG_AVS_Stati 0;
BA_ "GenSigSendType" SG_ 1633 AAG_Blinker_H_aktiv 0;
BA_ "GenSigSwitchedByIgnition" SG_ 1633 AAG_Blinker_H_aktiv 0;
BA_ "GenSigSendType" SG_ 1633 AAG_Blinker_HL_def 0;
BA_ "GenSigSwitchedByIgnition" SG_ 1633 AAG_Blinker_HL_def 0;
BA_ "GenSigSendType" SG_ 1633 AAG_Blinker_HR_def 0;
BA_ "GenSigSwitchedByIgnition" SG_ 1633 AAG_Blinker_HR_def 0;
BA_ "GenSigSendType" SG_ 1633 AAG_Bremsl_durch_ECD 0;
BA_ "GenSigSwitchedByIgnition" SG_ 1633 AAG_Bremsl_durch_ECD 0;
BA_ "GenSigSendType" SG_ 1633 AAG_Bremslicht_H_def 0;
BA_ "GenSigSwitchedByIgnition" SG_ 1633 AAG_Bremslicht_H_def 0;
BA_ "GenSigSendType" SG_ 1633 AAG_Bremslicht_Reku 0;
BA_ "GenSigSwitchedByIgnition" SG_ 1633 AAG_Bremslicht_Reku 0;
BA_ "GenSigSendType" SG_ 1633 AAG_BZ 0;
BA_ "GenSigFuncType" SG_ 1633 AAG_BZ 1;
BA_ "GenSigSwitchedByIgnition" SG_ 1633 AAG_BZ 0;
BA_ "GenSigSendType" SG_ 1633 AAG_LED_aktiv 0;
BA_ "GenSigSwitchedByIgnition" SG_ 1633 AAG_LED_aktiv 0;
BA_ "GenSigSendType" SG_ 1633 AAG_NSL_aktiv 0;
BA_ "GenSigSwitchedByIgnition" SG_ 1633 AAG_NSL_aktiv 0;
BA_ "GenSigSendType" SG_ 1633 AAG_Schlusslicht_HL_def 0;
BA_ "GenSigSwitchedByIgnition" SG_ 1633 AAG_Schlusslicht_HL_def 0;
BA_ "GenSigSendType" SG_ 1633 AAG_Schlusslicht_HR_def 0;
BA_ "GenSigSwitchedByIgnition" SG_ 1633 AAG_Schlusslicht_HR_def 0;
BA_ "GenSigSendType" SG_ 345 ARA_Aktiver_Grafikmodus 3;
BA_ "GenSigSendType" SG_ 345 ARA_Bremsfuss 3;
BA_ "GenSigSendType" SG_ 345 ARA_Deaktivierung_sperren 3;
BA_ "GenSigSendType" SG_ 345 ARA_Knickwinkel_Ist 3;
BA_ "GenSigStartValue" SG_ 345 ARA_Knickwinkel_Ist 254;
BA_ "Fehlerwert" SG_ 345 ARA_Knickwinkel_Ist 255;
BA_ "GenSigSendType" SG_ 345 ARA_Knickwinkel_Komfort 3;
BA_ "GenSigStartValue" SG_ 345 ARA_Knickwinkel_Komfort 62;
BA_ "Fehlerwert" SG_ 345 ARA_Knickwinkel_Komfort 63;
BA_ "GenSigSendType" SG_ 345 ARA_Knickwinkel_Konfidenz 3;
BA_ "GenSigStartValue" SG_ 345 ARA_Knickwinkel_Konfidenz 126;
BA_ "Fehlerwert" SG_ 345 ARA_Knickwinkel_Konfidenz 127;
BA_ "GenSigSendType" SG_ 345 ARA_Knickwinkel_Max 3;
BA_ "GenSigStartValue" SG_ 345 ARA_Knickwinkel_Max 126;
BA_ "Fehlerwert" SG_ 345 ARA_Knickwinkel_Max 127;
BA_ "GenSigSendType" SG_ 345 ARA_Knickwinkel_Soll 3;
BA_ "GenSigStartValue" SG_ 345 ARA_Knickwinkel_Soll 254;
BA_ "Fehlerwert" SG_ 345 ARA_Knickwinkel_Soll 255;
BA_ "GenSigSendType" SG_ 345 ARA_Modus 3;
BA_ "GenSigSendType" SG_ 345 ARA_Modus_Anf 3;
BA_ "GenSigSendType" SG_ 345 ARA_Sensor_Aktivierung 3;
BA_ "GenSigSendType" SG_ 345 ARA_Status 3;
BA_ "GenSigStartValue" SG_ 345 ARA_Status 1;
BA_ "Fehlerwert" SG_ 345 ARA_Status 2;
BA_ "GenSigSendType" SG_ 345 ARA_Texte 3;
BA_ "Fehlerwert" SG_ 345 ARA_Texte 63;
BA_ "GenSigSendType" SG_ 893 AAG_ASTA_Status 0;
BA_ "GenSigSwitchedByIgnition" SG_ 893 AAG_ASTA_Status 0;
BA_ "Fehlerwert" SG_ 893 AAG_ASTA_Status 1;
BA_ "GenSigSendType" SG_ 893 ASTA_Anhaengerlast 0;
BA_ "GenSigStartValue" SG_ 893 ASTA_Anhaengerlast 8190;
BA_ "GenSigSwitchedByIgnition" SG_ 893 ASTA_Anhaengerlast 0;
BA_ "Fehlerwert" SG_ 893 ASTA_Anhaengerlast 8191;
BA_ "GenSigSendType" SG_ 893 ASTA_Einheit 0;
BA_ "GenSigSwitchedByIgnition" SG_ 893 ASTA_Einheit 0;
BA_ "Fehlerwert" SG_ 893 ASTA_Einheit 3;
BA_ "GenSigSendType" SG_ 893 ASTA_Stuetzlast 0;
BA_ "GenSigStartValue" SG_ 893 ASTA_Stuetzlast 510;
BA_ "GenSigSwitchedByIgnition" SG_ 893 ASTA_Stuetzlast 0;
BA_ "Fehlerwert" SG_ 893 ASTA_Stuetzlast 511;
BA_ "GenSigSendType" SG_ 893 ASTAs_01_upd 0;
BA_ "GenSigFuncType" SG_ 893 ASTAs_01_upd 5;
BA_ "GenSigSwitchedByIgnition" SG_ 893 ASTAs_01_upd 0;
BA_ "GenSigSendType" SG_ 2589283618 AWC_Fehler_FOD 0;
BA_ "GenSigSwitchedByIgnition" SG_ 2589283618 AWC_Fehler_FOD 0;
BA_ "Fehlerwert" SG_ 2589283618 AWC_Fehler_FOD 1;
BA_ "GenSigSendType" SG_ 2589283618 AWC_Fehler_Kommunikation 0;
BA_ "GenSigSwitchedByIgnition" SG_ 2589283618 AWC_Fehler_Kommunikation 0;
BA_ "Fehlerwert" SG_ 2589283618 AWC_Fehler_Kommunikation 1;
BA_ "GenSigSendType" SG_ 2589283618 AWC_Fehler_LOP 0;
BA_ "GenSigSwitchedByIgnition" SG_ 2589283618 AWC_Fehler_LOP 0;
BA_ "Fehlerwert" SG_ 2589283618 AWC_Fehler_LOP 1;
BA_ "GenSigSendType" SG_ 2589283618 AWC_Fehler_zMover 3;
BA_ "GenSigSwitchedByIgnition" SG_ 2589283618 AWC_Fehler_zMover 0;
BA_ "Fehlerwert" SG_ 2589283618 AWC_Fehler_zMover 1;
BA_ "GenSigSendType" SG_ 2589283618 AWC_Ladeoption_Infrastruktur 0;
BA_ "GenSigStartValue" SG_ 2589283618 AWC_Ladeoption_Infrastruktur 7;
BA_ "GenSigSwitchedByIgnition" SG_ 2589283618 AWC_Ladeoption_Infrastruktur 0;
BA_ "GenSigSendType" SG_ 2589283618 AWC_Panel_PositionX 0;
BA_ "GenSigStartValue" SG_ 2589283618 AWC_Panel_PositionX 2046;
BA_ "GenSigSwitchedByIgnition" SG_ 2589283618 AWC_Panel_PositionX 0;
BA_ "Fehlerwert" SG_ 2589283618 AWC_Panel_PositionX 2047;
BA_ "GenSigSendType" SG_ 2589283618 AWC_Panel_PositionY 0;
BA_ "GenSigStartValue" SG_ 2589283618 AWC_Panel_PositionY 2046;
BA_ "GenSigSwitchedByIgnition" SG_ 2589283618 AWC_Panel_PositionY 0;
BA_ "Fehlerwert" SG_ 2589283618 AWC_Panel_PositionY 2047;
BA_ "GenSigSendType" SG_ 2589283618 AWC_Panel_Verdrehwinkel 0;
BA_ "GenSigStartValue" SG_ 2589283618 AWC_Panel_Verdrehwinkel 254;
BA_ "GenSigSwitchedByIgnition" SG_ 2589283618 AWC_Panel_Verdrehwinkel 0;
BA_ "Fehlerwert" SG_ 2589283618 AWC_Panel_Verdrehwinkel 255;
BA_ "GenSigSendType" SG_ 2589283618 AWC_Positionierhilfe 0;
BA_ "GenSigSwitchedByIgnition" SG_ 2589283618 AWC_Positionierhilfe 0;
BA_ "GenSigSendType" SG_ 2589283618 AWC_Spielschutz 0;
BA_ "GenSigSwitchedByIgnition" SG_ 2589283618 AWC_Spielschutz 0;
BA_ "GenSigSendType" SG_ 2589283618 AWC_Status 0;
BA_ "GenSigStartValue" SG_ 2589283618 AWC_Status 14;
BA_ "GenSigSwitchedByIgnition" SG_ 2589283618 AWC_Status 0;
BA_ "Fehlerwert" SG_ 2589283618 AWC_Status 15;
BA_ "GenSigSendType" SG_ 2589283618 AWC_Verzoegerung_FOD 0;
BA_ "GenSigSwitchedByIgnition" SG_ 2589283618 AWC_Verzoegerung_FOD 0;
BA_ "GenSigSendType" SG_ 2589283618 AWC_Verzoegerung_LOP 0;
BA_ "GenSigSwitchedByIgnition" SG_ 2589283618 AWC_Verzoegerung_LOP 0;
BA_ "GenSigSendType" SG_ 2589283618 AWC_Verzoegerung_Temp 0;
BA_ "GenSigSwitchedByIgnition" SG_ 2589283618 AWC_Verzoegerung_Temp 0;
BA_ "GenSigSendType" SG_ 2589283618 AWC_Verzoegerung_zMover 0;
BA_ "GenSigSwitchedByIgnition" SG_ 2589283618 AWC_Verzoegerung_zMover 0;
BA_REL_ "GenSigTimeoutTime" BU_SG_REL_ HUD SG_ 678 ACC_Tempolimit 500;
BA_REL_ "GenSigTimeoutTime" BU_SG_REL_ HUD SG_ 678 ACC_Warnung_Verkehrszeichen_1 500;
BA_REL_ "GenSigTimeoutTime" BU_SG_REL_ HUD SG_ 678 ACA_Querfuehrung 500;
BA_REL_ "GenSigTimeoutTime" BU_SG_REL_ HUD SG_ 678 ACC_Regelung_AIO 500;
BA_REL_ "GenSigTimeoutTime" BU_SG_REL_ HUD SG_ 678 ACC_Wunschgeschw_02 500;
BA_REL_ "GenSigTimeoutTime" BU_SG_REL_ HUD SG_ 678 ACC_Abstandsindex_02 500;
BA_REL_ "GenSigTimeoutTime" BU_SG_REL_ HUD SG_ 678 ACC_Gesetzte_Zeitluecke 500;
BA_REL_ "GenSigTimeoutTime" BU_SG_REL_ HUD SG_ 678 ACC_Optischer_Fahrerhinweis 500;
BA_REL_ "GenSigTimeoutTime" BU_SG_REL_ HUD SG_ 678 ACC_Warnhinweis 500;
BA_REL_ "GenSigTimeoutTime" BU_SG_REL_ HUD SG_ 678 ACC_EGO_Fahrzeug 500;
BA_REL_ "GenSigTimeoutTime" BU_SG_REL_ HUD SG_ 678 ACC_Relevantes_Objekt_02 500;
BA_REL_ "GenSigTimeoutTime" BU_SG_REL_ HUD SG_ 678 ACC_Wunschgeschw_erreicht 500;
BA_REL_ "GenSigTimeoutTime" BU_SG_REL_ HUD SG_ 678 ACC_Anzeige_Zeitluecke 500;
BA_REL_ "GenSigTimeoutTime" BU_SG_REL_ HUD SG_ 678 ACC_Texte_Primaeranz_02 500;
BA_REL_ "GenSigTimeoutTime" BU_SG_REL_ HUD SG_ 678 ACC_Texte_Zusatzanz_02 500;
BA_REL_ "GenSigTimeoutTime" BU_SG_REL_ HUD SG_ 678 STA_Primaeranz 500;
BA_REL_ "GenSigTimeoutTime" BU_SG_REL_ HUD SG_ 679 ACC_Regelgeschw 500;
BA_REL_ "GenSigTimeoutTime" BU_SG_REL_ HUD SG_ 679 ACC_Tempolimitassistent_02 500;
BA_REL_ "GenSigTimeoutTime" BU_SG_REL_ HUD SG_ 679 ACC_Tempolimit_Einheit 500;
BA_REL_ "GenSigTimeoutTime" BU_SG_REL_ HUD SG_ 679 ACC_Kurvenassistent 500;
BA_REL_ "GenSigTimeoutTime" BU_SG_REL_ HUD SG_ 679 ACC_RUV 500;
BA_REL_ "GenSigTimeoutTime" BU_SG_REL_ HUD SG_ 680 ACA_Querfuehrung_Texte 500;
BA_REL_ "GenSigTimeoutTime" BU_SG_REL_ HUD SG_ 680 ACC_Status_Anzeige 500;
BA_REL_ "GenSigTimeoutTime" BU_SG_REL_ HUD SG_ 680 STA_Texte 500;
BA_REL_ "GenSigTimeoutTime" BU_SG_REL_ HUD SG_ 681 AWV_Warnung 2000;
BA_REL_ "GenSigTimeoutTime" BU_SG_REL_ HUD SG_ 681 AWV_LED_Leiste 2000;
BA_REL_ "GenSigTimeoutTime" BU_SG_REL_ HUD SG_ 614 ACC_Nutzung_VZ_PACC 5000;
BA_REL_ "GenSigTimeoutTime" BU_SG_REL_ HUD SG_ 2331595865 ACC_HMI_Obj_01_Spurzuordnung 800;
BA_REL_ "GenSigTimeoutTime" BU_SG_REL_ HUD SG_ 2331595865 ACC_HMI_Obj_01_dx 800;
BA_REL_ "GenSigTimeoutTime" BU_SG_REL_ HUD SG_ 2331595865 ACC_HMI_Obj_01_Typ 800;
BA_REL_ "GenSigTimeoutTime" BU_SG_REL_ HUD SG_ 2331595865 ACC_HMI_Obj_02_Spurzuordnung 800;
BA_REL_ "GenSigTimeoutTime" BU_SG_REL_ HUD SG_ 2331595865 ACC_HMI_Obj_02_dx 800;
BA_REL_ "GenSigTimeoutTime" BU_SG_REL_ HUD SG_ 2331595865 ACC_HMI_Obj_02_Typ 800;
BA_REL_ "GenSigTimeoutTime" BU_SG_REL_ HUD SG_ 2331595866 ACC_HMI_Obj_03_Spurzuordnung 800;
BA_REL_ "GenSigTimeoutTime" BU_SG_REL_ HUD SG_ 2331595866 ACC_HMI_Obj_03_dx 800;
BA_REL_ "GenSigTimeoutTime" BU_SG_REL_ HUD SG_ 2331595866 ACC_HMI_Obj_03_Typ 800;
BA_REL_ "GenSigTimeoutTime" BU_SG_REL_ HUD SG_ 2331595866 ACC_HMI_Obj_04_Spurzuordnung 800;
BA_REL_ "GenSigTimeoutTime" BU_SG_REL_ HUD SG_ 2331595866 ACC_HMI_Obj_04_dx 800;
BA_REL_ "GenSigTimeoutTime" BU_SG_REL_ HUD SG_ 2331595866 ACC_HMI_Obj_04_Typ 800;
BA_REL_ "GenSigTimeoutTime" BU_SG_REL_ HUD SG_ 2331595867 ACC_HMI_Obj_05_Spurzuordnung 800;
BA_REL_ "GenSigTimeoutTime" BU_SG_REL_ HUD SG_ 2331595867 ACC_HMI_Obj_05_dx 800;
BA_REL_ "GenSigTimeoutTime" BU_SG_REL_ HUD SG_ 2331595867 ACC_HMI_Obj_05_Typ 800;
BA_REL_ "GenSigTimeoutTime" BU_SG_REL_ HUD SG_ 2331595867 ACC_HMI_Obj_06_Spurzuordnung 800;
BA_REL_ "GenSigTimeoutTime" BU_SG_REL_ HUD SG_ 2331595867 ACC_HMI_Obj_06_dx 800;
BA_REL_ "GenSigTimeoutTime" BU_SG_REL_ HUD SG_ 2331595867 ACC_HMI_Obj_06_Typ 800;
BA_REL_ "GenSigTimeoutTime" BU_SG_REL_ HUD SG_ 1312 LoGeWa_Event_Kombiwarnung 2000;
BA_REL_ "GenSigTimeoutTime" BU_SG_REL_ Kombi SG_ 2331596020 ACC_Texte_03 500;
BA_REL_ "GenSigTimeoutTime" BU_SG_REL_ Kombi SG_ 2331596020 ACC_Texte_Sekundaeranz_03 500;
BA_REL_ "GenSigTimeoutTime" BU_SG_REL_ Kombi SG_ 678 ACC_Tempolimit 500;
BA_REL_ "GenSigTimeoutTime" BU_SG_REL_ Kombi SG_ 678 ACC_Wunschgeschw_Farbe 500;
BA_REL_ "GenSigTimeoutTime" BU_SG_REL_ Kombi SG_ 678 ACC_Warnung_Verkehrszeichen_1 500;
BA_REL_ "GenSigTimeoutTime" BU_SG_REL_ Kombi SG_ 678 ACA_Querfuehrung 500;
BA_REL_ "GenSigTimeoutTime" BU_SG_REL_ Kombi SG_ 678 ACC_Regelung_AIO 500;
BA_REL_ "GenSigTimeoutTime" BU_SG_REL_ Kombi SG_ 678 ACC_Wunschgeschw_02 500;
BA_REL_ "GenSigTimeoutTime" BU_SG_REL_ Kombi SG_ 678 ACC_Abstandsindex_02 500;
BA_REL_ "GenSigTimeoutTime" BU_SG_REL_ Kombi SG_ 678 ACC_Display_Prio 500;
BA_REL_ "GenSigTimeoutTime" BU_SG_REL_ Kombi SG_ 678 ACC_rel_Objekt_Zusatzanz 500;
BA_REL_ "GenSigTimeoutTime" BU_SG_REL_ Kombi SG_ 678 ACC_Gesetzte_Zeitluecke 500;
BA_REL_ "GenSigTimeoutTime" BU_SG_REL_ Kombi SG_ 678 ACC_Optischer_Fahrerhinweis 500;
BA_REL_ "GenSigTimeoutTime" BU_SG_REL_ Kombi SG_ 678 ACC_Warnhinweis 500;
BA_REL_ "GenSigTimeoutTime" BU_SG_REL_ Kombi SG_ 678 ACC_EGO_Fahrzeug 500;
BA_REL_ "GenSigTimeoutTime" BU_SG_REL_ Kombi SG_ 678 ACC_Relevantes_Objekt_02 500;
BA_REL_ "GenSigTimeoutTime" BU_SG_REL_ Kombi SG_ 678 ACC_Wunschgeschw_erreicht 500;
BA_REL_ "GenSigTimeoutTime" BU_SG_REL_ Kombi SG_ 678 ACC_Anzeige_Zeitluecke 500;
BA_REL_ "GenSigTimeoutTime" BU_SG_REL_ Kombi SG_ 678 ACC_Texte_Primaeranz_02 500;
BA_REL_ "GenSigTimeoutTime" BU_SG_REL_ Kombi SG_ 678 ACC_Texte_Zusatzanz_02 500;
BA_REL_ "GenSigTimeoutTime" BU_SG_REL_ Kombi SG_ 678 STA_Primaeranz 500;
BA_REL_ "GenSigTimeoutTime" BU_SG_REL_ Kombi SG_ 679 ACC_Regelgeschw 500;
BA_REL_ "GenSigTimeoutTime" BU_SG_REL_ Kombi SG_ 679 ACC_Einheit_maxSetzgeschw 500;
BA_REL_ "GenSigTimeoutTime" BU_SG_REL_ Kombi SG_ 679 ACC_maxSetzgeschw 500;
BA_REL_ "GenSigTimeoutTime" BU_SG_REL_ Kombi SG_ 679 ACC_minRegelgeschw 500;
BA_REL_ "GenSigTimeoutTime" BU_SG_REL_ Kombi SG_ 679 ACC_maxRegelgeschw 500;
BA_REL_ "GenSigTimeoutTime" BU_SG_REL_ Kombi SG_ 679 ACC_Tempolimitassistent_02 500;
BA_REL_ "GenSigTimeoutTime" BU_SG_REL_ Kombi SG_ 679 ACC_Tempolimit_Einheit 500;
BA_REL_ "GenSigTimeoutTime" BU_SG_REL_ Kombi SG_ 679 ACC_Kurvenassistent 500;
BA_REL_ "GenSigTimeoutTime" BU_SG_REL_ Kombi SG_ 679 ACC_RUV 500;
BA_REL_ "GenSigTimeoutTime" BU_SG_REL_ Kombi SG_ 679 ACC_Tachokranz 500;
BA_REL_ "GenSigTimeoutTime" BU_SG_REL_ Kombi SG_ 679 ACC_Typ_Tachokranz_unten 500;
BA_REL_ "GenSigTimeoutTime" BU_SG_REL_ Kombi SG_ 679 ACC_ENG_Texte 500;
BA_REL_ "GenSigTimeoutTime" BU_SG_REL_ Kombi SG_ 680 ACA_Querfuehrung_Texte 500;
BA_REL_ "GenSigTimeoutTime" BU_SG_REL_ Kombi SG_ 680 ACA_Hinweistexte 500;
BA_REL_ "GenSigTimeoutTime" BU_SG_REL_ Kombi SG_ 680 ACC_Texte_Abstandswarner 500;
BA_REL_ "GenSigTimeoutTime" BU_SG_REL_ Kombi SG_ 680 ACC_Vorz_Abstandswarner 500;
BA_REL_ "GenSigTimeoutTime" BU_SG_REL_ Kombi SG_ 680 ACC_Texte_Sekundaeranz 500;
BA_REL_ "GenSigTimeoutTime" BU_SG_REL_ Kombi SG_ 680 ACC_Status_Anzeige 500;
BA_REL_ "GenSigTimeoutTime" BU_SG_REL_ Kombi SG_ 680 ACC_Akustik_03 500;
BA_REL_ "GenSigTimeoutTime" BU_SG_REL_ Kombi SG_ 680 ACC_Geschw_Zielfahrzeug 500;
BA_REL_ "GenSigTimeoutTime" BU_SG_REL_ Kombi SG_ 680 ACC_Texte 500;
BA_REL_ "GenSigTimeoutTime" BU_SG_REL_ Kombi SG_ 680 ACC_STA_Text 500;
BA_REL_ "GenSigTimeoutTime" BU_SG_REL_ Kombi SG_ 680 STA_Texte 500;
BA_REL_ "GenSigTimeoutTime" BU_SG_REL_ Kombi SG_ 680 STA_Zusatzanz 500;
BA_REL_ "GenSigTimeoutTime" BU_SG_REL_ Kombi SG_ 680 ACC_Zeitluecke_Abstandswarner 500;
BA_REL_ "GenSigTimeoutTime" BU_SG_REL_ Kombi SG_ 680 ACC_Abstand_Abstandswarner 500;
BA_REL_ "GenSigTimeoutTime" BU_SG_REL_ Kombi SG_ 680 ACC_Einheit_Abstandswarner 500;
BA_REL_ "GenSigTimeoutTime" BU_SG_REL_ Kombi SG_ 681 AWV_Warnung 2000;
BA_REL_ "GenSigTimeoutTime" BU_SG_REL_ Kombi SG_ 681 AWV_LED_Leiste 2000;
BA_REL_ "GenSigTimeoutTime" BU_SG_REL_ Kombi SG_ 681 AWV_Texte 2000;
BA_REL_ "GenSigTimeoutTime" BU_SG_REL_ Kombi SG_ 2331595865 ACC_HMI_Obj_01_Spurzuordnung 800;
BA_REL_ "GenSigTimeoutTime" BU_SG_REL_ Kombi SG_ 2331595865 ACC_HMI_Obj_01_dx 800;
BA_REL_ "GenSigTimeoutTime" BU_SG_REL_ Kombi SG_ 2331595865 ACC_HMI_Obj_01_dy 800;
BA_REL_ "GenSigTimeoutTime" BU_SG_REL_ Kombi SG_ 2331595865 ACC_HMI_Obj_01_Typ 800;
BA_REL_ "GenSigTimeoutTime" BU_SG_REL_ Kombi SG_ 2331595865 ACC_HMI_Obj_01_LaengsRegelung 800;
BA_REL_ "GenSigTimeoutTime" BU_SG_REL_ Kombi SG_ 2331595865 ACC_HMI_Obj_01_QuerRegelung 800;
BA_REL_ "GenSigTimeoutTime" BU_SG_REL_ Kombi SG_ 2331595865 ACC_HMI_Obj_02_Spurzuordnung 800;
BA_REL_ "GenSigTimeoutTime" BU_SG_REL_ Kombi SG_ 2331595865 ACC_HMI_Obj_02_dx 800;
BA_REL_ "GenSigTimeoutTime" BU_SG_REL_ Kombi SG_ 2331595865 ACC_HMI_Obj_02_dy 800;
BA_REL_ "GenSigTimeoutTime" BU_SG_REL_ Kombi SG_ 2331595865 ACC_HMI_Obj_02_Typ 800;
BA_REL_ "GenSigTimeoutTime" BU_SG_REL_ Kombi SG_ 2331595865 ACC_HMI_Obj_02_LaengsRegelung 800;
BA_REL_ "GenSigTimeoutTime" BU_SG_REL_ Kombi SG_ 2331595865 ACC_HMI_Obj_02_QuerRegelung 800;
BA_REL_ "GenSigTimeoutTime" BU_SG_REL_ Kombi SG_ 2331595866 ACC_HMI_Obj_03_Spurzuordnung 800;
BA_REL_ "GenSigTimeoutTime" BU_SG_REL_ Kombi SG_ 2331595866 ACC_HMI_Obj_03_dx 800;
BA_REL_ "GenSigTimeoutTime" BU_SG_REL_ Kombi SG_ 2331595866 ACC_HMI_Obj_03_dy 800;
BA_REL_ "GenSigTimeoutTime" BU_SG_REL_ Kombi SG_ 2331595866 ACC_HMI_Obj_03_Typ 800;
BA_REL_ "GenSigTimeoutTime" BU_SG_REL_ Kombi SG_ 2331595866 ACC_HMI_Obj_03_LaengsRegelung 800;
BA_REL_ "GenSigTimeoutTime" BU_SG_REL_ Kombi SG_ 2331595866 ACC_HMI_Obj_03_QuerRegelung 800;
BA_REL_ "GenSigTimeoutTime" BU_SG_REL_ Kombi SG_ 2331595866 ACC_HMI_Obj_04_Spurzuordnung 800;
BA_REL_ "GenSigTimeoutTime" BU_SG_REL_ Kombi SG_ 2331595866 ACC_HMI_Obj_04_dx 800;
BA_REL_ "GenSigTimeoutTime" BU_SG_REL_ Kombi SG_ 2331595866 ACC_HMI_Obj_04_dy 800;
BA_REL_ "GenSigTimeoutTime" BU_SG_REL_ Kombi SG_ 2331595866 ACC_HMI_Obj_04_Typ 800;
BA_REL_ "GenSigTimeoutTime" BU_SG_REL_ Kombi SG_ 2331595866 ACC_HMI_Obj_04_LaengsRegelung 800;
BA_REL_ "GenSigTimeoutTime" BU_SG_REL_ Kombi SG_ 2331595866 ACC_HMI_Obj_04_QuerRegelung 800;
BA_REL_ "GenSigTimeoutTime" BU_SG_REL_ Kombi SG_ 2331595867 ACC_HMI_Obj_05_Spurzuordnung 800;
BA_REL_ "GenSigTimeoutTime" BU_SG_REL_ Kombi SG_ 2331595867 ACC_HMI_Obj_05_dx 800;
BA_REL_ "GenSigTimeoutTime" BU_SG_REL_ Kombi SG_ 2331595867 ACC_HMI_Obj_05_dy 800;
BA_REL_ "GenSigTimeoutTime" BU_SG_REL_ Kombi SG_ 2331595867 ACC_HMI_Obj_05_Typ 800;
BA_REL_ "GenSigTimeoutTime" BU_SG_REL_ Kombi SG_ 2331595867 ACC_HMI_Obj_05_LaengsRegelung 800;
BA_REL_ "GenSigTimeoutTime" BU_SG_REL_ Kombi SG_ 2331595867 ACC_HMI_Obj_05_QuerRegelung 800;
BA_REL_ "GenSigTimeoutTime" BU_SG_REL_ Kombi SG_ 2331595867 ACC_HMI_Obj_06_Spurzuordnung 800;
BA_REL_ "GenSigTimeoutTime" BU_SG_REL_ Kombi SG_ 2331595867 ACC_HMI_Obj_06_dx 800;
BA_REL_ "GenSigTimeoutTime" BU_SG_REL_ Kombi SG_ 2331595867 ACC_HMI_Obj_06_dy 800;
BA_REL_ "GenSigTimeoutTime" BU_SG_REL_ Kombi SG_ 2331595867 ACC_HMI_Obj_06_Typ 800;
BA_REL_ "GenSigTimeoutTime" BU_SG_REL_ Kombi SG_ 2331595867 ACC_HMI_Obj_06_LaengsRegelung 800;
BA_REL_ "GenSigTimeoutTime" BU_SG_REL_ Kombi SG_ 2331595867 ACC_HMI_Obj_06_QuerRegelung 800;
BA_REL_ "GenSigTimeoutTime" BU_SG_REL_ Kombi SG_ 2331595868 ACC_HMI_Nachb_li_belegt 800;
BA_REL_ "GenSigTimeoutTime" BU_SG_REL_ Kombi SG_ 2331595868 ACC_HMI_Nachb_re_belegt 800;
BA_REL_ "GenSigTimeoutTime" BU_SG_REL_ Kombi SG_ 2331595868 ACC_HMI_Spurwechsel_li 800;
BA_REL_ "GenSigTimeoutTime" BU_SG_REL_ Kombi SG_ 2331595868 ACC_HMI_Spurwechsel_re 800;
BA_REL_ "GenSigTimeoutTime" BU_SG_REL_ Kombi SG_ 2331595868 ACC_HMI_Seg1_Gierwinkel 800;
BA_REL_ "GenSigTimeoutTime" BU_SG_REL_ Kombi SG_ 2331595868 ACC_HMI_Seg1_Kruemmung 800;
BA_REL_ "GenSigTimeoutTime" BU_SG_REL_ Kombi SG_ 2331595868 ACC_HMI_Seg2_Beginn 800;
BA_REL_ "GenSigTimeoutTime" BU_SG_REL_ Kombi SG_ 2331595868 ACC_HMI_Seg2_Kruemmung 800;
BA_REL_ "GenSigTimeoutTime" BU_SG_REL_ Kombi SG_ 2331595869 ACC_HMI_Ego_li_Seg1_QuerAbst 800;
BA_REL_ "GenSigTimeoutTime" BU_SG_REL_ Kombi SG_ 2331595869 ACC_HMI_Ego_re_Seg1_QuerAbst 800;
BA_REL_ "GenSigTimeoutTime" BU_SG_REL_ Kombi SG_ 2331595869 ACC_HMI_Nachb_li_Seg1_QuerAbst 800;
BA_REL_ "GenSigTimeoutTime" BU_SG_REL_ Kombi SG_ 2331595869 ACC_HMI_Nachb_re_Seg1_QuerAbst 800;
BA_REL_ "GenSigTimeoutTime" BU_SG_REL_ Kombi SG_ 2331595869 ACC_HMI_Egospur_li_Typ 800;
BA_REL_ "GenSigTimeoutTime" BU_SG_REL_ Kombi SG_ 2331595869 ACC_HMI_Egospur_re_Typ 800;
BA_REL_ "GenSigTimeoutTime" BU_SG_REL_ Kombi SG_ 2331595869 ACC_HMI_Nachb_li_Typ 800;
BA_REL_ "GenSigTimeoutTime" BU_SG_REL_ Kombi SG_ 2331595869 ACC_HMI_Nachb_re_Typ 800;
BA_REL_ "GenSigTimeoutTime" BU_SG_REL_ Kombi SG_ 2331595870 ACC_HMI_TrajektSeg1_Valid 800;
BA_REL_ "GenSigTimeoutTime" BU_SG_REL_ Kombi SG_ 2331595870 ACC_HMI_TrajektSeg1_Kruemmung 800;
BA_REL_ "GenSigTimeoutTime" BU_SG_REL_ Kombi SG_ 2331595870 ACC_HMI_TrajektSeg1_QuerAbst 800;
BA_REL_ "GenSigTimeoutTime" BU_SG_REL_ Kombi SG_ 2331595870 ACC_HMI_TrajektSeg1_Gierwinkel 800;
BA_REL_ "GenSigTimeoutTime" BU_SG_REL_ Kombi SG_ 2331595870 ACC_HMI_TrajektSeg2_Beginn 800;
BA_REL_ "GenSigTimeoutTime" BU_SG_REL_ Kombi SG_ 2331595870 ACC_HMI_TrajektSeg2_Kruemmung 800;
BA_REL_ "GenSigTimeoutTime" BU_SG_REL_ Kombi SG_ 2331595871 ACC_HMI_ZoomstufeAktiv 800;
BA_REL_ "GenSigTimeoutTime" BU_SG_REL_ Kombi SG_ 2331595871 ACC_HMI_Zoomstufe 800;
BA_REL_ "GenSigTimeoutTime" BU_SG_REL_ Kombi SG_ 2331595871 ACC_HMI_Kurvenwarnung 800;
BA_REL_ "GenSigTimeoutTime" BU_SG_REL_ Kombi SG_ 2331595871 ACC_HMI_EgoObj_dy 800;
BA_REL_ "GenSigTimeoutTime" BU_SG_REL_ Kombi SG_ 2331595871 ACC_HMI_TrajektVorausschau 800;
BA_REL_ "GenSigTimeoutTime" BU_SG_REL_ Kombi SG_ 2331595871 ACC_HMI_TrajektFarbe_li 800;
BA_REL_ "GenSigTimeoutTime" BU_SG_REL_ Kombi SG_ 2331595871 ACC_HMI_TrajektFarbe_re 800;
BA_REL_ "GenSigTimeoutTime" BU_SG_REL_ Kombi SG_ 2331595971 ACC_HMI_ZeitlueckenAuswahl 800;
BA_REL_ "GenSigTimeoutTime" BU_SG_REL_ Kombi SG_ 2331595971 ACC_HMI_Zeitluecke_01_dx 800;
BA_REL_ "GenSigTimeoutTime" BU_SG_REL_ Kombi SG_ 2331595971 ACC_HMI_Zeitluecke_02_dx 800;
BA_REL_ "GenSigTimeoutTime" BU_SG_REL_ Kombi SG_ 2331595971 ACC_HMI_Zeitluecke_03_dx 800;
BA_REL_ "GenSigTimeoutTime" BU_SG_REL_ Kombi SG_ 2331595971 ACC_HMI_Zeitluecke_04_dx 800;
BA_REL_ "GenSigTimeoutTime" BU_SG_REL_ Kombi SG_ 2331595971 ACC_HMI_Zeitluecke_05_dx 800;
BA_REL_ "GenSigTimeoutTime" BU_SG_REL_ Kombi SG_ 2527679927 ADA_HMI_Muedigkeit_Event_Meldung 5000;
BA_REL_ "GenSigTimeoutTime" BU_SG_REL_ Kombi SG_ 2527679927 ADA_HMI_Ablenkung_Deaktivierung 5000;
BA_REL_ "GenSigTimeoutTime" BU_SG_REL_ Kombi SG_ 2527679927 ADA_HMI_Ablenkung_Meldung 5000;
BA_REL_ "GenSigTimeoutTime" BU_SG_REL_ Kombi SG_ 2527679927 ADA_HMI_Muedigkeit_Fehler_Popup 5000;
BA_REL_ "GenSigTimeoutTime" BU_SG_REL_ Kombi SG_ 2527679927 ADA_HMI_Ablenkung_Fehler_Popup 5000;
BA_REL_ "GenSigTimeoutTime" BU_SG_REL_ Kombi SG_ 2527679927 ADA_HMI_Muedigkeit_Deaktivierung 5000;
BA_REL_ "GenSigTimeoutTime" BU_SG_REL_ Kombi SG_ 2527679927 ADA_HMI_Ablenkung_Meldeakustik 5000;
BA_REL_ "GenSigTimeoutTime" BU_SG_REL_ Kombi SG_ 2527679927 ADA_HMI_Muedigkeit_Meldeakustik 5000;
BA_REL_ "GenSigTimeoutTime" BU_SG_REL_ Kombi SG_ 2527679927 ADA_HMI_Muedigkeit_Meldung 5000;
BA_REL_ "GenSigTimeoutTime" BU_SG_REL_ Kombi SG_ 2527679927 ADA_DrowsinessSystemState 5000;
BA_REL_ "GenSigTimeoutTime" BU_SG_REL_ Kombi SG_ 2527679927 ADA_HMI_Fahrzeit_seit_Pause 5000;
BA_REL_ "GenSigTimeoutTime" BU_SG_REL_ Kombi SG_ 232 AFR_gMeter_ay 500;
BA_REL_ "GenSigTimeoutTime" BU_SG_REL_ Kombi SG_ 232 AFR_gMeter_ax 500;
BA_REL_ "GenSigTimeoutTime" BU_SG_REL_ Kombi SG_ 1660 E_Sound_Texte 5000;
BA_REL_ "GenSigTimeoutTime" BU_SG_REL_ Kombi SG_ 1660 E_Sound_verbaut 5000;
BA_REL_ "GenSigTimeoutTime" BU_SG_REL_ Kombi SG_ 1660 E_Sound_Mute_Icon 5000;
BA_REL_ "GenSigTimeoutTime" BU_SG_REL_ Kombi SG_ 64 Airbag_01_CRC 2000;
BA_REL_ "GenSigTimeoutTime" BU_SG_REL_ Kombi SG_ 64 Airbag_01_BZ 2000;
BA_REL_ "GenSigTimeoutTime" BU_SG_REL_ Kombi SG_ 64 AB_Lampe 2000;
BA_REL_ "GenSigTimeoutTime" BU_SG_REL_ Kombi SG_ 64 AB_Deaktiviert 2000;
BA_REL_ "GenSigTimeoutTime" BU_SG_REL_ Kombi SG_ 64 AB_VB_deaktiviert 2000;
BA_REL_ "GenSigTimeoutTime" BU_SG_REL_ Kombi SG_ 64 AB_Systemfehler 2000;
BA_REL_ "GenSigTimeoutTime" BU_SG_REL_ Kombi SG_ 64 AB_Erh_Auf_VB 2000;
BA_REL_ "GenSigTimeoutTime" BU_SG_REL_ Kombi SG_ 64 AB_Gurtwarn_VF 2000;
BA_REL_ "GenSigTimeoutTime" BU_SG_REL_ Kombi SG_ 64 AB_Gurtwarn_VB 2000;
BA_REL_ "GenSigTimeoutTime" BU_SG_REL_ Kombi SG_ 64 AB_Anzeige_Fussg 2000;
BA_REL_ "GenSigTimeoutTime" BU_SG_REL_ Kombi SG_ 64 AB_Texte_AKS 2000;
BA_REL_ "GenSigTimeoutTime" BU_SG_REL_ Kombi SG_ 64 AB_Versorgungsspannung 2000;
BA_REL_ "GenSigTimeoutTime" BU_SG_REL_ Kombi SG_ 64 AB_Belegung_VF 2000;
BA_REL_ "GenSigTimeoutTime" BU_SG_REL_ Kombi SG_ 1312 LoGeWa_Event_Kombiwarnung 2000;
BA_REL_ "GenSigTimeoutTime" BU_SG_REL_ Kombi SG_ 1312 AB_Wickelklappung_Reihe2_MI 2000;
BA_REL_ "GenSigTimeoutTime" BU_SG_REL_ Kombi SG_ 1312 AB_Gurtschloss_FA 2000;
BA_REL_ "GenSigTimeoutTime" BU_SG_REL_ Kombi SG_ 1312 AB_Gurtschloss_BF 2000;
BA_REL_ "GenSigTimeoutTime" BU_SG_REL_ Kombi SG_ 1312 AB_Gurtschloss_Reihe2_FA 2000;
BA_REL_ "GenSigTimeoutTime" BU_SG_REL_ Kombi SG_ 1312 AB_Gurtschloss_Reihe2_MI 2000;
BA_REL_ "GenSigTimeoutTime" BU_SG_REL_ Kombi SG_ 1312 AB_Gurtschloss_Reihe2_BF 2000;
BA_REL_ "GenSigTimeoutTime" BU_SG_REL_ Kombi SG_ 1312 AB_Gurtschloss_Reihe3_FA 2000;
BA_REL_ "GenSigTimeoutTime" BU_SG_REL_ Kombi SG_ 1312 AB_Gurtschloss_Reihe3_MI 2000;
BA_REL_ "GenSigTimeoutTime" BU_SG_REL_ Kombi SG_ 1312 AB_Gurtschloss_Reihe3_BF 2000;
BA_REL_ "GenSigTimeoutTime" BU_SG_REL_ Kombi SG_ 1312 AB_Wickelklappung_Reihe2_BF 2000;
BA_REL_ "GenSigTimeoutTime" BU_SG_REL_ Kombi SG_ 1312 AB_Wickelklappung_Reihe2_FA 2000;
BA_REL_ "GenSigTimeoutTime" BU_SG_REL_ Kombi SG_ 1349 AB_Gurtwarn_Reihe2_FA 2000;
BA_REL_ "GenSigTimeoutTime" BU_SG_REL_ Kombi SG_ 1349 AB_Gurtwarn_Reihe2_BF 2000;
BA_REL_ "GenSigTimeoutTime" BU_SG_REL_ Kombi SG_ 1349 AB_Gurtwarn_Reihe2_MI 2000;
BA_REL_ "GenSigTimeoutTime" BU_SG_REL_ Kombi SG_ 1349 AB_Gurtwarn_Reihe3_FA 2000;
BA_REL_ "GenSigTimeoutTime" BU_SG_REL_ Kombi SG_ 1349 AB_Gurtwarn_Reihe3_MI 2000;
BA_REL_ "GenSigTimeoutTime" BU_SG_REL_ Kombi SG_ 1349 AB_Gurtwarn_Reihe3_BF 2000;
BA_REL_ "GenSigTimeoutTime" BU_SG_REL_ Kombi SG_ 1349 AB_SBR_hinten_verbau 2000;
BA_REL_ "GenSigTimeoutTime" BU_SG_REL_ Kombi SG_ 674 Allrad_06_CRC 2000;
BA_REL_ "GenSigTimeoutTime" BU_SG_REL_ Kombi SG_ 674 Allrad_06_BZ 2000;
BA_REL_ "GenSigTimeoutTime" BU_SG_REL_ Kombi SG_ 674 ALR_Warnlampe 2000;
BA_REL_ "GenSigTimeoutTime" BU_SG_REL_ Kombi SG_ 674 ALR_Texte 2000;
BA_REL_ "GenSigTimeoutTime" BU_SG_REL_ Kombi SG_ 1633 AAG_BZ 1000;
BA_REL_ "GenSigTimeoutTime" BU_SG_REL_ Kombi SG_ 1633 AAG_AVS_Fehler_02_inv 1000;
BA_REL_ "GenSigTimeoutTime" BU_SG_REL_ Kombi SG_ 1633 AAG_Blinker_H_aktiv 1000;
BA_REL_ "GenSigTimeoutTime" BU_SG_REL_ Kombi SG_ 1633 AAG_Blinker_HL_def 1000;
BA_REL_ "GenSigTimeoutTime" BU_SG_REL_ Kombi SG_ 1633 AAG_Blinker_HR_def 1000;
BA_REL_ "GenSigTimeoutTime" BU_SG_REL_ Kombi SG_ 1633 AAG_Bremslicht_H_def 1000;
BA_REL_ "GenSigTimeoutTime" BU_SG_REL_ Kombi SG_ 1633 AAG_Schlusslicht_HL_def 1000;
BA_REL_ "GenSigTimeoutTime" BU_SG_REL_ Kombi SG_ 1633 AAG_Schlusslicht_HR_def 1000;
BA_REL_ "GenSigTimeoutTime" BU_SG_REL_ Kombi SG_ 1633 AAG_AVS_Fehler_02 1000;
BA_REL_ "GenSigTimeoutTime" BU_SG_REL_ Kombi SG_ 345 ARA_Knickwinkel_Konfidenz 1000;
BA_REL_ "GenSigTimeoutTime" BU_SG_REL_ Kombi SG_ 345 ARA_Texte 1000;
BA_REL_ "GenSigTimeoutTime" BU_SG_REL_ Kombi SG_ 345 ARA_Modus 1000;
BA_REL_ "GenSigTimeoutTime" BU_SG_REL_ Kombi SG_ 345 ARA_Aktiver_Grafikmodus 1000;
BA_REL_ "GenSigTimeoutTime" BU_SG_REL_ Kombi SG_ 345 ARA_Bremsfuss 1000;
BA_REL_ "GenSigTimeoutTime" BU_SG_REL_ Kombi SG_ 345 ARA_Knickwinkel_Komfort 1000;
BA_REL_ "GenSigTimeoutTime" BU_SG_REL_ Kombi SG_ 345 ARA_Knickwinkel_Max 1000;
BA_REL_ "GenSigTimeoutTime" BU_SG_REL_ Kombi SG_ 345 ARA_Knickwinkel_Soll 1000;
BA_REL_ "GenSigTimeoutTime" BU_SG_REL_ Kombi SG_ 345 ARA_Knickwinkel_Ist 1000;
BA_REL_ "GenSigTimeoutTime" BU_SG_REL_ Kombi SG_ 893 ASTA_Stuetzlast 5000;
BA_REL_ "GenSigTimeoutTime" BU_SG_REL_ Kombi SG_ 893 ASTA_Einheit 5000;
BA_REL_ "GenSigTimeoutTime" BU_SG_REL_ Kombi SG_ 893 ASTA_Anhaengerlast 5000;
BA_REL_ "GenSigTimeoutTime" BU_SG_REL_ Kombi SG_ 893 AAG_ASTA_Status 5000;
BA_REL_ "GenSigTimeoutTime" BU_SG_REL_ Kombi SG_ 893 ASTAs_01_upd 5000;
BA_REL_ "GenSigTimeoutTime" BU_SG_REL_ Kombi_LB SG_ 2331596020 ACC_Texte_03 500;
BA_REL_ "GenSigTimeoutTime" BU_SG_REL_ Kombi_LB SG_ 2331596020 ACC_Texte_Sekundaeranz_03 500;
BA_REL_ "GenSigTimeoutTime" BU_SG_REL_ Kombi_LB SG_ 678 ACC_Tempolimit 500;
BA_REL_ "GenSigTimeoutTime" BU_SG_REL_ Kombi_LB SG_ 678 ACC_Wunschgeschw_Farbe 500;
BA_REL_ "GenSigTimeoutTime" BU_SG_REL_ Kombi_LB SG_ 678 ACC_Warnung_Verkehrszeichen_1 500;
BA_REL_ "GenSigTimeoutTime" BU_SG_REL_ Kombi_LB SG_ 678 ACA_Querfuehrung 500;
BA_REL_ "GenSigTimeoutTime" BU_SG_REL_ Kombi_LB SG_ 678 ACC_Regelung_AIO 500;
BA_REL_ "GenSigTimeoutTime" BU_SG_REL_ Kombi_LB SG_ 678 ACC_Wunschgeschw_02 500;
BA_REL_ "GenSigTimeoutTime" BU_SG_REL_ Kombi_LB SG_ 678 ACC_Abstandsindex_02 500;
BA_REL_ "GenSigTimeoutTime" BU_SG_REL_ Kombi_LB SG_ 678 ACC_Display_Prio 500;
BA_REL_ "GenSigTimeoutTime" BU_SG_REL_ Kombi_LB SG_ 678 ACC_rel_Objekt_Zusatzanz 500;
BA_REL_ "GenSigTimeoutTime" BU_SG_REL_ Kombi_LB SG_ 678 ACC_Gesetzte_Zeitluecke 500;
BA_REL_ "GenSigTimeoutTime" BU_SG_REL_ Kombi_LB SG_ 678 ACC_Optischer_Fahrerhinweis 500;
BA_REL_ "GenSigTimeoutTime" BU_SG_REL_ Kombi_LB SG_ 678 ACC_Warnhinweis 500;
BA_REL_ "GenSigTimeoutTime" BU_SG_REL_ Kombi_LB SG_ 678 ACC_EGO_Fahrzeug 500;
BA_REL_ "GenSigTimeoutTime" BU_SG_REL_ Kombi_LB SG_ 678 ACC_Relevantes_Objekt_02 500;
BA_REL_ "GenSigTimeoutTime" BU_SG_REL_ Kombi_LB SG_ 678 ACC_Wunschgeschw_erreicht 500;
BA_REL_ "GenSigTimeoutTime" BU_SG_REL_ Kombi_LB SG_ 678 ACC_Anzeige_Zeitluecke 500;
BA_REL_ "GenSigTimeoutTime" BU_SG_REL_ Kombi_LB SG_ 678 ACC_Texte_Primaeranz_02 500;
BA_REL_ "GenSigTimeoutTime" BU_SG_REL_ Kombi_LB SG_ 678 ACC_Texte_Zusatzanz_02 500;
BA_REL_ "GenSigTimeoutTime" BU_SG_REL_ Kombi_LB SG_ 678 STA_Primaeranz 500;
BA_REL_ "GenSigTimeoutTime" BU_SG_REL_ Kombi_LB SG_ 679 ACC_Regelgeschw 500;
BA_REL_ "GenSigTimeoutTime" BU_SG_REL_ Kombi_LB SG_ 679 ACC_Einheit_maxSetzgeschw 500;
BA_REL_ "GenSigTimeoutTime" BU_SG_REL_ Kombi_LB SG_ 679 ACC_maxSetzgeschw 500;
BA_REL_ "GenSigTimeoutTime" BU_SG_REL_ Kombi_LB SG_ 679 ACC_minRegelgeschw 500;
BA_REL_ "GenSigTimeoutTime" BU_SG_REL_ Kombi_LB SG_ 679 ACC_maxRegelgeschw 500;
BA_REL_ "GenSigTimeoutTime" BU_SG_REL_ Kombi_LB SG_ 679 ACC_Tempolimitassistent_02 500;
BA_REL_ "GenSigTimeoutTime" BU_SG_REL_ Kombi_LB SG_ 679 ACC_Tempolimit_Einheit 500;
BA_REL_ "GenSigTimeoutTime" BU_SG_REL_ Kombi_LB SG_ 679 ACC_Kurvenassistent 500;
BA_REL_ "GenSigTimeoutTime" BU_SG_REL_ Kombi_LB SG_ 679 ACC_RUV 500;
BA_REL_ "GenSigTimeoutTime" BU_SG_REL_ Kombi_LB SG_ 679 ACC_Tachokranz 500;
BA_REL_ "GenSigTimeoutTime" BU_SG_REL_ Kombi_LB SG_ 679 ACC_Typ_Tachokranz_unten 500;
BA_REL_ "GenSigTimeoutTime" BU_SG_REL_ Kombi_LB SG_ 679 ACC_ENG_Texte 500;
BA_REL_ "GenSigTimeoutTime" BU_SG_REL_ Kombi_LB SG_ 680 ACA_Querfuehrung_Texte 500;
BA_REL_ "GenSigTimeoutTime" BU_SG_REL_ Kombi_LB SG_ 680 ACA_Hinweistexte 500;
BA_REL_ "GenSigTimeoutTime" BU_SG_REL_ Kombi_LB SG_ 680 ACC_Texte_Abstandswarner 500;
BA_REL_ "GenSigTimeoutTime" BU_SG_REL_ Kombi_LB SG_ 680 ACC_Vorz_Abstandswarner 500;
BA_REL_ "GenSigTimeoutTime" BU_SG_REL_ Kombi_LB SG_ 680 ACC_Texte_Sekundaeranz 500;
BA_REL_ "GenSigTimeoutTime" BU_SG_REL_ Kombi_LB SG_ 680 ACC_Status_Anzeige 500;
BA_REL_ "GenSigTimeoutTime" BU_SG_REL_ Kombi_LB SG_ 680 ACC_Akustik_03 500;
BA_REL_ "GenSigTimeoutTime" BU_SG_REL_ Kombi_LB SG_ 680 ACC_Geschw_Zielfahrzeug 500;
BA_REL_ "GenSigTimeoutTime" BU_SG_REL_ Kombi_LB SG_ 680 ACC_Texte 500;
BA_REL_ "GenSigTimeoutTime" BU_SG_REL_ Kombi_LB SG_ 680 ACC_STA_Text 500;
BA_REL_ "GenSigTimeoutTime" BU_SG_REL_ Kombi_LB SG_ 680 STA_Texte 500;
BA_REL_ "GenSigTimeoutTime" BU_SG_REL_ Kombi_LB SG_ 680 STA_Zusatzanz 500;
BA_REL_ "GenSigTimeoutTime" BU_SG_REL_ Kombi_LB SG_ 680 ACC_Zeitluecke_Abstandswarner 500;
BA_REL_ "GenSigTimeoutTime" BU_SG_REL_ Kombi_LB SG_ 680 ACC_Abstand_Abstandswarner 500;
BA_REL_ "GenSigTimeoutTime" BU_SG_REL_ Kombi_LB SG_ 680 ACC_Einheit_Abstandswarner 500;
BA_REL_ "GenSigTimeoutTime" BU_SG_REL_ Kombi_LB SG_ 681 AWV_Warnung 2000;
BA_REL_ "GenSigTimeoutTime" BU_SG_REL_ Kombi_LB SG_ 681 AWV_LED_Leiste 2000;
BA_REL_ "GenSigTimeoutTime" BU_SG_REL_ Kombi_LB SG_ 681 AWV_Texte 2000;
BA_REL_ "GenSigTimeoutTime" BU_SG_REL_ Kombi_LB SG_ 2527679927 ADA_HMI_Muedigkeit_Event_Meldung 5000;
BA_REL_ "GenSigTimeoutTime" BU_SG_REL_ Kombi_LB SG_ 2527679927 ADA_HMI_Ablenkung_Deaktivierung 5000;
BA_REL_ "GenSigTimeoutTime" BU_SG_REL_ Kombi_LB SG_ 2527679927 ADA_HMI_Ablenkung_Meldung 5000;
BA_REL_ "GenSigTimeoutTime" BU_SG_REL_ Kombi_LB SG_ 2527679927 ADA_HMI_Muedigkeit_Fehler_Popup 5000;
BA_REL_ "GenSigTimeoutTime" BU_SG_REL_ Kombi_LB SG_ 2527679927 ADA_HMI_Ablenkung_Fehler_Popup 5000;
BA_REL_ "GenSigTimeoutTime" BU_SG_REL_ Kombi_LB SG_ 2527679927 ADA_HMI_Muedigkeit_Deaktivierung 5000;
BA_REL_ "GenSigTimeoutTime" BU_SG_REL_ Kombi_LB SG_ 2527679927 ADA_HMI_Ablenkung_Meldeakustik 5000;
BA_REL_ "GenSigTimeoutTime" BU_SG_REL_ Kombi_LB SG_ 2527679927 ADA_HMI_Muedigkeit_Meldeakustik 5000;
BA_REL_ "GenSigTimeoutTime" BU_SG_REL_ Kombi_LB SG_ 2527679927 ADA_HMI_Muedigkeit_Meldung 5000;
BA_REL_ "GenSigTimeoutTime" BU_SG_REL_ Kombi_LB SG_ 2527679927 ADA_DrowsinessSystemState 5000;
BA_REL_ "GenSigTimeoutTime" BU_SG_REL_ Kombi_LB SG_ 2527679927 ADA_HMI_Fahrzeit_seit_Pause 5000;
BA_REL_ "GenSigTimeoutTime" BU_SG_REL_ Kombi_LB SG_ 232 AFR_gMeter_ay 500;
BA_REL_ "GenSigTimeoutTime" BU_SG_REL_ Kombi_LB SG_ 232 AFR_gMeter_ax 500;
BA_REL_ "GenSigTimeoutTime" BU_SG_REL_ Kombi_LB SG_ 1660 E_Sound_Texte 5000;
BA_REL_ "GenSigTimeoutTime" BU_SG_REL_ Kombi_LB SG_ 1660 E_Sound_verbaut 5000;
BA_REL_ "GenSigTimeoutTime" BU_SG_REL_ Kombi_LB SG_ 1660 E_Sound_Mute_Icon 5000;
BA_REL_ "GenSigTimeoutTime" BU_SG_REL_ Kombi_LB SG_ 64 Airbag_01_CRC 2000;
BA_REL_ "GenSigTimeoutTime" BU_SG_REL_ Kombi_LB SG_ 64 Airbag_01_BZ 2000;
BA_REL_ "GenSigTimeoutTime" BU_SG_REL_ Kombi_LB SG_ 64 AB_Lampe 2000;
BA_REL_ "GenSigTimeoutTime" BU_SG_REL_ Kombi_LB SG_ 64 AB_Deaktiviert 2000;
BA_REL_ "GenSigTimeoutTime" BU_SG_REL_ Kombi_LB SG_ 64 AB_VB_deaktiviert 2000;
BA_REL_ "GenSigTimeoutTime" BU_SG_REL_ Kombi_LB SG_ 64 AB_Systemfehler 2000;
BA_REL_ "GenSigTimeoutTime" BU_SG_REL_ Kombi_LB SG_ 64 AB_Erh_Auf_VB 2000;
BA_REL_ "GenSigTimeoutTime" BU_SG_REL_ Kombi_LB SG_ 64 AB_Gurtwarn_VF 2000;
BA_REL_ "GenSigTimeoutTime" BU_SG_REL_ Kombi_LB SG_ 64 AB_Gurtwarn_VB 2000;
BA_REL_ "GenSigTimeoutTime" BU_SG_REL_ Kombi_LB SG_ 64 AB_Anzeige_Fussg 2000;
BA_REL_ "GenSigTimeoutTime" BU_SG_REL_ Kombi_LB SG_ 64 AB_Texte_AKS 2000;
BA_REL_ "GenSigTimeoutTime" BU_SG_REL_ Kombi_LB SG_ 64 AB_Versorgungsspannung 2000;
BA_REL_ "GenSigTimeoutTime" BU_SG_REL_ Kombi_LB SG_ 64 AB_Belegung_VF 2000;
BA_REL_ "GenSigTimeoutTime" BU_SG_REL_ Kombi_LB SG_ 1312 LoGeWa_Event_Kombiwarnung 2000;
BA_REL_ "GenSigTimeoutTime" BU_SG_REL_ Kombi_LB SG_ 1312 AB_Wickelklappung_Reihe2_MI 2000;
BA_REL_ "GenSigTimeoutTime" BU_SG_REL_ Kombi_LB SG_ 1312 AB_Gurtschloss_FA 2000;
BA_REL_ "GenSigTimeoutTime" BU_SG_REL_ Kombi_LB SG_ 1312 AB_Gurtschloss_BF 2000;
BA_REL_ "GenSigTimeoutTime" BU_SG_REL_ Kombi_LB SG_ 1312 AB_Wickelklappung_Reihe2_BF 2000;
BA_REL_ "GenSigTimeoutTime" BU_SG_REL_ Kombi_LB SG_ 1312 AB_Wickelklappung_Reihe2_FA 2000;
BA_REL_ "GenSigTimeoutTime" BU_SG_REL_ Kombi_LB SG_ 1349 AB_SBR_hinten_verbau 2000;
BA_REL_ "GenSigTimeoutTime" BU_SG_REL_ Kombi_LB SG_ 674 Allrad_06_CRC 2000;
BA_REL_ "GenSigTimeoutTime" BU_SG_REL_ Kombi_LB SG_ 674 Allrad_06_BZ 2000;
BA_REL_ "GenSigTimeoutTime" BU_SG_REL_ Kombi_LB SG_ 674 ALR_Warnlampe 2000;
BA_REL_ "GenSigTimeoutTime" BU_SG_REL_ Kombi_LB SG_ 674 ALR_Texte 2000;
BA_REL_ "GenSigTimeoutTime" BU_SG_REL_ Kombi_LB SG_ 345 ARA_Knickwinkel_Komfort 1000;
BA_REL_ "GenSigTimeoutTime" BU_SG_REL_ Kombi_LB SG_ 345 ARA_Knickwinkel_Max 1000;
BA_REL_ "GenSigTimeoutTime" BU_SG_REL_ Kombi_LB SG_ 345 ARA_Knickwinkel_Soll 1000;
BA_REL_ "GenSigTimeoutTime" BU_SG_REL_ Kombi_LB SG_ 345 ARA_Knickwinkel_Ist 1000;
BA_REL_ "GenSigTimeoutTime" BU_SG_REL_ Kombi_PAG SG_ 678 ACC_Tempolimit 500;
BA_REL_ "GenSigTimeoutTime" BU_SG_REL_ Kombi_PAG SG_ 678 ACC_Wunschgeschw_Farbe 500;
BA_REL_ "GenSigTimeoutTime" BU_SG_REL_ Kombi_PAG SG_ 678 ACC_Warnung_Verkehrszeichen_1 500;
BA_REL_ "GenSigTimeoutTime" BU_SG_REL_ Kombi_PAG SG_ 678 ACA_Querfuehrung 500;
BA_REL_ "GenSigTimeoutTime" BU_SG_REL_ Kombi_PAG SG_ 678 ACC_Wunschgeschw_02 500;
BA_REL_ "GenSigTimeoutTime" BU_SG_REL_ Kombi_PAG SG_ 678 ACC_Abstandsindex_02 500;
BA_REL_ "GenSigTimeoutTime" BU_SG_REL_ Kombi_PAG SG_ 678 ACC_Display_Prio 500;
BA_REL_ "GenSigTimeoutTime" BU_SG_REL_ Kombi_PAG SG_ 678 ACC_rel_Objekt_Zusatzanz 500;
BA_REL_ "GenSigTimeoutTime" BU_SG_REL_ Kombi_PAG SG_ 678 ACC_Gesetzte_Zeitluecke 500;
BA_REL_ "GenSigTimeoutTime" BU_SG_REL_ Kombi_PAG SG_ 678 ACC_Optischer_Fahrerhinweis 500;
BA_REL_ "GenSigTimeoutTime" BU_SG_REL_ Kombi_PAG SG_ 678 ACC_EGO_Fahrzeug 500;
BA_REL_ "GenSigTimeoutTime" BU_SG_REL_ Kombi_PAG SG_ 678 ACC_Relevantes_Objekt_02 500;
BA_REL_ "GenSigTimeoutTime" BU_SG_REL_ Kombi_PAG SG_ 678 ACC_Wunschgeschw_erreicht 500;
BA_REL_ "GenSigTimeoutTime" BU_SG_REL_ Kombi_PAG SG_ 678 ACC_Anzeige_Zeitluecke 500;
BA_REL_ "GenSigTimeoutTime" BU_SG_REL_ Kombi_PAG SG_ 678 ACC_Texte_Primaeranz_02 500;
BA_REL_ "GenSigTimeoutTime" BU_SG_REL_ Kombi_PAG SG_ 678 ACC_Texte_Zusatzanz_02 500;
BA_REL_ "GenSigTimeoutTime" BU_SG_REL_ Kombi_PAG SG_ 678 STA_Primaeranz 500;
BA_REL_ "GenSigTimeoutTime" BU_SG_REL_ Kombi_PAG SG_ 679 ACC_Regelgeschw 500;
BA_REL_ "GenSigTimeoutTime" BU_SG_REL_ Kombi_PAG SG_ 679 ACC_Einheit_maxSetzgeschw 500;
BA_REL_ "GenSigTimeoutTime" BU_SG_REL_ Kombi_PAG SG_ 679 ACC_maxSetzgeschw 500;
BA_REL_ "GenSigTimeoutTime" BU_SG_REL_ Kombi_PAG SG_ 679 ACC_minRegelgeschw 500;
BA_REL_ "GenSigTimeoutTime" BU_SG_REL_ Kombi_PAG SG_ 679 ACC_maxRegelgeschw 500;
BA_REL_ "GenSigTimeoutTime" BU_SG_REL_ Kombi_PAG SG_ 679 ACC_Tempolimitassistent_02 500;
BA_REL_ "GenSigTimeoutTime" BU_SG_REL_ Kombi_PAG SG_ 679 ACC_Kurvenassistent 500;
BA_REL_ "GenSigTimeoutTime" BU_SG_REL_ Kombi_PAG SG_ 679 ACC_RUV 500;
BA_REL_ "GenSigTimeoutTime" BU_SG_REL_ Kombi_PAG SG_ 679 ACC_Tachokranz 500;
BA_REL_ "GenSigTimeoutTime" BU_SG_REL_ Kombi_PAG SG_ 679 ACC_Typ_Tachokranz_unten 500;
BA_REL_ "GenSigTimeoutTime" BU_SG_REL_ Kombi_PAG SG_ 679 ACC_ENG_Texte 500;
BA_REL_ "GenSigTimeoutTime" BU_SG_REL_ Kombi_PAG SG_ 680 ACA_Querfuehrung_Texte 500;
BA_REL_ "GenSigTimeoutTime" BU_SG_REL_ Kombi_PAG SG_ 680 ACA_Hinweistexte 500;
BA_REL_ "GenSigTimeoutTime" BU_SG_REL_ Kombi_PAG SG_ 680 ACC_Texte_Abstandswarner 500;
BA_REL_ "GenSigTimeoutTime" BU_SG_REL_ Kombi_PAG SG_ 680 ACC_Vorz_Abstandswarner 500;
BA_REL_ "GenSigTimeoutTime" BU_SG_REL_ Kombi_PAG SG_ 680 ACC_Texte_Sekundaeranz 500;
BA_REL_ "GenSigTimeoutTime" BU_SG_REL_ Kombi_PAG SG_ 680 ACC_Status_Anzeige 500;
BA_REL_ "GenSigTimeoutTime" BU_SG_REL_ Kombi_PAG SG_ 680 ACC_Akustik_03 500;
BA_REL_ "GenSigTimeoutTime" BU_SG_REL_ Kombi_PAG SG_ 680 ACC_Geschw_Zielfahrzeug 500;
BA_REL_ "GenSigTimeoutTime" BU_SG_REL_ Kombi_PAG SG_ 680 ACC_Texte 500;
BA_REL_ "GenSigTimeoutTime" BU_SG_REL_ Kombi_PAG SG_ 680 ACC_STA_Text 500;
BA_REL_ "GenSigTimeoutTime" BU_SG_REL_ Kombi_PAG SG_ 680 STA_Texte 500;
BA_REL_ "GenSigTimeoutTime" BU_SG_REL_ Kombi_PAG SG_ 680 STA_Zusatzanz 500;
BA_REL_ "GenSigTimeoutTime" BU_SG_REL_ Kombi_PAG SG_ 680 ACC_Zeitluecke_Abstandswarner 500;
BA_REL_ "GenSigTimeoutTime" BU_SG_REL_ Kombi_PAG SG_ 680 ACC_Abstand_Abstandswarner 500;
BA_REL_ "GenSigTimeoutTime" BU_SG_REL_ Kombi_PAG SG_ 680 ACC_Einheit_Abstandswarner 500;
BA_REL_ "GenSigTimeoutTime" BU_SG_REL_ Kombi_PAG SG_ 681 AWV_Warnung 2000;
BA_REL_ "GenSigTimeoutTime" BU_SG_REL_ Kombi_PAG SG_ 681 AWV_LED_Leiste 2000;
BA_REL_ "GenSigTimeoutTime" BU_SG_REL_ Kombi_PAG SG_ 681 AWV_Texte 2000;
BA_REL_ "GenSigTimeoutTime" BU_SG_REL_ Kombi_PAG SG_ 2331595865 ACC_HMI_Obj_01_Spurzuordnung 800;
BA_REL_ "GenSigTimeoutTime" BU_SG_REL_ Kombi_PAG SG_ 2331595865 ACC_HMI_Obj_01_dx 800;
BA_REL_ "GenSigTimeoutTime" BU_SG_REL_ Kombi_PAG SG_ 2331595865 ACC_HMI_Obj_01_dy 800;
BA_REL_ "GenSigTimeoutTime" BU_SG_REL_ Kombi_PAG SG_ 2331595865 ACC_HMI_Obj_01_Typ 800;
BA_REL_ "GenSigTimeoutTime" BU_SG_REL_ Kombi_PAG SG_ 2331595865 ACC_HMI_Obj_01_LaengsRegelung 800;
BA_REL_ "GenSigTimeoutTime" BU_SG_REL_ Kombi_PAG SG_ 2331595865 ACC_HMI_Obj_01_QuerRegelung 800;
BA_REL_ "GenSigTimeoutTime" BU_SG_REL_ Kombi_PAG SG_ 2331595865 ACC_HMI_Obj_02_Spurzuordnung 800;
BA_REL_ "GenSigTimeoutTime" BU_SG_REL_ Kombi_PAG SG_ 2331595865 ACC_HMI_Obj_02_dx 800;
BA_REL_ "GenSigTimeoutTime" BU_SG_REL_ Kombi_PAG SG_ 2331595865 ACC_HMI_Obj_02_dy 800;
BA_REL_ "GenSigTimeoutTime" BU_SG_REL_ Kombi_PAG SG_ 2331595865 ACC_HMI_Obj_02_Typ 800;
BA_REL_ "GenSigTimeoutTime" BU_SG_REL_ Kombi_PAG SG_ 2331595865 ACC_HMI_Obj_02_LaengsRegelung 800;
BA_REL_ "GenSigTimeoutTime" BU_SG_REL_ Kombi_PAG SG_ 2331595865 ACC_HMI_Obj_02_QuerRegelung 800;
BA_REL_ "GenSigTimeoutTime" BU_SG_REL_ Kombi_PAG SG_ 2331595866 ACC_HMI_Obj_03_Spurzuordnung 800;
BA_REL_ "GenSigTimeoutTime" BU_SG_REL_ Kombi_PAG SG_ 2331595866 ACC_HMI_Obj_03_dx 800;
BA_REL_ "GenSigTimeoutTime" BU_SG_REL_ Kombi_PAG SG_ 2331595866 ACC_HMI_Obj_03_dy 800;
BA_REL_ "GenSigTimeoutTime" BU_SG_REL_ Kombi_PAG SG_ 2331595866 ACC_HMI_Obj_03_Typ 800;
BA_REL_ "GenSigTimeoutTime" BU_SG_REL_ Kombi_PAG SG_ 2331595866 ACC_HMI_Obj_03_LaengsRegelung 800;
BA_REL_ "GenSigTimeoutTime" BU_SG_REL_ Kombi_PAG SG_ 2331595866 ACC_HMI_Obj_03_QuerRegelung 800;
BA_REL_ "GenSigTimeoutTime" BU_SG_REL_ Kombi_PAG SG_ 2331595866 ACC_HMI_Obj_04_Spurzuordnung 800;
BA_REL_ "GenSigTimeoutTime" BU_SG_REL_ Kombi_PAG SG_ 2331595866 ACC_HMI_Obj_04_dx 800;
BA_REL_ "GenSigTimeoutTime" BU_SG_REL_ Kombi_PAG SG_ 2331595866 ACC_HMI_Obj_04_dy 800;
BA_REL_ "GenSigTimeoutTime" BU_SG_REL_ Kombi_PAG SG_ 2331595866 ACC_HMI_Obj_04_Typ 800;
BA_REL_ "GenSigTimeoutTime" BU_SG_REL_ Kombi_PAG SG_ 2331595866 ACC_HMI_Obj_04_LaengsRegelung 800;
BA_REL_ "GenSigTimeoutTime" BU_SG_REL_ Kombi_PAG SG_ 2331595866 ACC_HMI_Obj_04_QuerRegelung 800;
BA_REL_ "GenSigTimeoutTime" BU_SG_REL_ Kombi_PAG SG_ 2331595867 ACC_HMI_Obj_05_Spurzuordnung 800;
BA_REL_ "GenSigTimeoutTime" BU_SG_REL_ Kombi_PAG SG_ 2331595867 ACC_HMI_Obj_05_dx 800;
BA_REL_ "GenSigTimeoutTime" BU_SG_REL_ Kombi_PAG SG_ 2331595867 ACC_HMI_Obj_05_dy 800;
BA_REL_ "GenSigTimeoutTime" BU_SG_REL_ Kombi_PAG SG_ 2331595867 ACC_HMI_Obj_05_Typ 800;
BA_REL_ "GenSigTimeoutTime" BU_SG_REL_ Kombi_PAG SG_ 2331595867 ACC_HMI_Obj_05_LaengsRegelung 800;
BA_REL_ "GenSigTimeoutTime" BU_SG_REL_ Kombi_PAG SG_ 2331595867 ACC_HMI_Obj_05_QuerRegelung 800;
BA_REL_ "GenSigTimeoutTime" BU_SG_REL_ Kombi_PAG SG_ 2331595867 ACC_HMI_Obj_06_Spurzuordnung 800;
BA_REL_ "GenSigTimeoutTime" BU_SG_REL_ Kombi_PAG SG_ 2331595867 ACC_HMI_Obj_06_dx 800;
BA_REL_ "GenSigTimeoutTime" BU_SG_REL_ Kombi_PAG SG_ 2331595867 ACC_HMI_Obj_06_dy 800;
BA_REL_ "GenSigTimeoutTime" BU_SG_REL_ Kombi_PAG SG_ 2331595867 ACC_HMI_Obj_06_Typ 800;
BA_REL_ "GenSigTimeoutTime" BU_SG_REL_ Kombi_PAG SG_ 2331595867 ACC_HMI_Obj_06_LaengsRegelung 800;
BA_REL_ "GenSigTimeoutTime" BU_SG_REL_ Kombi_PAG SG_ 2331595867 ACC_HMI_Obj_06_QuerRegelung 800;
BA_REL_ "GenSigTimeoutTime" BU_SG_REL_ Kombi_PAG SG_ 2331595868 ACC_HMI_Nachb_li_belegt 800;
BA_REL_ "GenSigTimeoutTime" BU_SG_REL_ Kombi_PAG SG_ 2331595868 ACC_HMI_Nachb_re_belegt 800;
BA_REL_ "GenSigTimeoutTime" BU_SG_REL_ Kombi_PAG SG_ 2331595868 ACC_HMI_Spurwechsel_li 800;
BA_REL_ "GenSigTimeoutTime" BU_SG_REL_ Kombi_PAG SG_ 2331595868 ACC_HMI_Spurwechsel_re 800;
BA_REL_ "GenSigTimeoutTime" BU_SG_REL_ Kombi_PAG SG_ 2331595868 ACC_HMI_Seg1_Gierwinkel 800;
BA_REL_ "GenSigTimeoutTime" BU_SG_REL_ Kombi_PAG SG_ 2331595868 ACC_HMI_Seg1_Kruemmung 800;
BA_REL_ "GenSigTimeoutTime" BU_SG_REL_ Kombi_PAG SG_ 2331595868 ACC_HMI_Seg2_Beginn 800;
BA_REL_ "GenSigTimeoutTime" BU_SG_REL_ Kombi_PAG SG_ 2331595868 ACC_HMI_Seg2_Kruemmung 800;
BA_REL_ "GenSigTimeoutTime" BU_SG_REL_ Kombi_PAG SG_ 2331595869 ACC_HMI_Ego_li_Seg1_QuerAbst 800;
BA_REL_ "GenSigTimeoutTime" BU_SG_REL_ Kombi_PAG SG_ 2331595869 ACC_HMI_Ego_re_Seg1_QuerAbst 800;
BA_REL_ "GenSigTimeoutTime" BU_SG_REL_ Kombi_PAG SG_ 2331595869 ACC_HMI_Nachb_li_Seg1_QuerAbst 800;
BA_REL_ "GenSigTimeoutTime" BU_SG_REL_ Kombi_PAG SG_ 2331595869 ACC_HMI_Nachb_re_Seg1_QuerAbst 800;
BA_REL_ "GenSigTimeoutTime" BU_SG_REL_ Kombi_PAG SG_ 2331595869 ACC_HMI_Egospur_li_Typ 800;
BA_REL_ "GenSigTimeoutTime" BU_SG_REL_ Kombi_PAG SG_ 2331595869 ACC_HMI_Egospur_re_Typ 800;
BA_REL_ "GenSigTimeoutTime" BU_SG_REL_ Kombi_PAG SG_ 2331595869 ACC_HMI_Nachb_li_Typ 800;
BA_REL_ "GenSigTimeoutTime" BU_SG_REL_ Kombi_PAG SG_ 2331595869 ACC_HMI_Nachb_re_Typ 800;
BA_REL_ "GenSigTimeoutTime" BU_SG_REL_ Kombi_PAG SG_ 2331595870 ACC_HMI_TrajektSeg1_Valid 800;
BA_REL_ "GenSigTimeoutTime" BU_SG_REL_ Kombi_PAG SG_ 2331595870 ACC_HMI_TrajektSeg1_Kruemmung 800;
BA_REL_ "GenSigTimeoutTime" BU_SG_REL_ Kombi_PAG SG_ 2331595870 ACC_HMI_TrajektSeg1_QuerAbst 800;
BA_REL_ "GenSigTimeoutTime" BU_SG_REL_ Kombi_PAG SG_ 2331595870 ACC_HMI_TrajektSeg1_Gierwinkel 800;
BA_REL_ "GenSigTimeoutTime" BU_SG_REL_ Kombi_PAG SG_ 2331595870 ACC_HMI_TrajektSeg2_Beginn 800;
BA_REL_ "GenSigTimeoutTime" BU_SG_REL_ Kombi_PAG SG_ 2331595870 ACC_HMI_TrajektSeg2_Kruemmung 800;
BA_REL_ "GenSigTimeoutTime" BU_SG_REL_ Kombi_PAG SG_ 2331595871 ACC_HMI_ZoomstufeAktiv 800;
BA_REL_ "GenSigTimeoutTime" BU_SG_REL_ Kombi_PAG SG_ 2331595871 ACC_HMI_Zoomstufe 800;
BA_REL_ "GenSigTimeoutTime" BU_SG_REL_ Kombi_PAG SG_ 2331595871 ACC_HMI_Kurvenwarnung 800;
BA_REL_ "GenSigTimeoutTime" BU_SG_REL_ Kombi_PAG SG_ 2331595871 ACC_HMI_EgoObj_dy 800;
BA_REL_ "GenSigTimeoutTime" BU_SG_REL_ Kombi_PAG SG_ 2331595871 ACC_HMI_TrajektVorausschau 800;
BA_REL_ "GenSigTimeoutTime" BU_SG_REL_ Kombi_PAG SG_ 2331595871 ACC_HMI_TrajektFarbe_li 800;
BA_REL_ "GenSigTimeoutTime" BU_SG_REL_ Kombi_PAG SG_ 2331595871 ACC_HMI_TrajektFarbe_re 800;
BA_REL_ "GenSigTimeoutTime" BU_SG_REL_ Kombi_PAG SG_ 2331595971 ACC_HMI_ZeitlueckenAuswahl 800;
BA_REL_ "GenSigTimeoutTime" BU_SG_REL_ Kombi_PAG SG_ 2331595971 ACC_HMI_Zeitluecke_01_dx 800;
BA_REL_ "GenSigTimeoutTime" BU_SG_REL_ Kombi_PAG SG_ 2331595971 ACC_HMI_Zeitluecke_02_dx 800;
BA_REL_ "GenSigTimeoutTime" BU_SG_REL_ Kombi_PAG SG_ 2331595971 ACC_HMI_Zeitluecke_03_dx 800;
BA_REL_ "GenSigTimeoutTime" BU_SG_REL_ Kombi_PAG SG_ 2331595971 ACC_HMI_Zeitluecke_04_dx 800;
BA_REL_ "GenSigTimeoutTime" BU_SG_REL_ Kombi_PAG SG_ 2331595971 ACC_HMI_Zeitluecke_05_dx 800;
BA_REL_ "GenSigTimeoutTime" BU_SG_REL_ Kombi_PAG SG_ 2527679927 ADA_HMI_Ablenkung_Deaktivierung 5000;
BA_REL_ "GenSigTimeoutTime" BU_SG_REL_ Kombi_PAG SG_ 2527679927 ADA_HMI_Ablenkung_Meldung 5000;
BA_REL_ "GenSigTimeoutTime" BU_SG_REL_ Kombi_PAG SG_ 2527679927 ADA_HMI_Muedigkeit_Fehler_Popup 5000;
BA_REL_ "GenSigTimeoutTime" BU_SG_REL_ Kombi_PAG SG_ 2527679927 ADA_HMI_Ablenkung_Fehler_Popup 5000;
BA_REL_ "GenSigTimeoutTime" BU_SG_REL_ Kombi_PAG SG_ 2527679927 ADA_HMI_Muedigkeit_Deaktivierung 5000;
BA_REL_ "GenSigTimeoutTime" BU_SG_REL_ Kombi_PAG SG_ 2527679927 ADA_HMI_Ablenkung_Meldeakustik 5000;
BA_REL_ "GenSigTimeoutTime" BU_SG_REL_ Kombi_PAG SG_ 2527679927 ADA_HMI_Muedigkeit_Meldeakustik 5000;
BA_REL_ "GenSigTimeoutTime" BU_SG_REL_ Kombi_PAG SG_ 2527679927 ADA_HMI_Muedigkeit_Meldung 5000;
BA_REL_ "GenSigTimeoutTime" BU_SG_REL_ Kombi_PAG SG_ 2527679927 ADA_DrowsinessSystemState 5000;
BA_REL_ "GenSigTimeoutTime" BU_SG_REL_ Kombi_PAG SG_ 2527679927 ADA_HMI_Fahrzeit_seit_Pause 5000;
BA_REL_ "GenSigTimeoutTime" BU_SG_REL_ Kombi_PAG SG_ 1660 E_Sound_Texte 5000;
BA_REL_ "GenSigTimeoutTime" BU_SG_REL_ Kombi_PAG SG_ 1660 E_Sound_verbaut 5000;
BA_REL_ "GenSigTimeoutTime" BU_SG_REL_ Kombi_PAG SG_ 1660 E_Sound_ohne_Funktion 5000;
BA_REL_ "GenSigTimeoutTime" BU_SG_REL_ Kombi_PAG SG_ 1660 E_Sound_Mute_Icon 5000;
BA_REL_ "GenSigTimeoutTime" BU_SG_REL_ Kombi_PAG SG_ 64 Airbag_01_CRC 2000;
BA_REL_ "GenSigTimeoutTime" BU_SG_REL_ Kombi_PAG SG_ 64 Airbag_01_BZ 2000;
BA_REL_ "GenSigTimeoutTime" BU_SG_REL_ Kombi_PAG SG_ 64 AB_Lampe 2000;
BA_REL_ "GenSigTimeoutTime" BU_SG_REL_ Kombi_PAG SG_ 64 AB_VB_deaktiviert 2000;
BA_REL_ "GenSigTimeoutTime" BU_SG_REL_ Kombi_PAG SG_ 64 AB_Systemfehler 2000;
BA_REL_ "GenSigTimeoutTime" BU_SG_REL_ Kombi_PAG SG_ 64 AB_Erh_Auf_VB 2000;
BA_REL_ "GenSigTimeoutTime" BU_SG_REL_ Kombi_PAG SG_ 64 AB_Gurtwarn_VF 2000;
BA_REL_ "GenSigTimeoutTime" BU_SG_REL_ Kombi_PAG SG_ 64 AB_Gurtwarn_VB 2000;
BA_REL_ "GenSigTimeoutTime" BU_SG_REL_ Kombi_PAG SG_ 64 AB_Anzeige_Fussg 2000;
BA_REL_ "GenSigTimeoutTime" BU_SG_REL_ Kombi_PAG SG_ 64 AB_Texte_AKS 2000;
BA_REL_ "GenSigTimeoutTime" BU_SG_REL_ Kombi_PAG SG_ 64 AB_Versorgungsspannung 2000;
BA_REL_ "GenSigTimeoutTime" BU_SG_REL_ Kombi_PAG SG_ 1312 LoGeWa_Event_Kombiwarnung 2000;
BA_REL_ "GenSigTimeoutTime" BU_SG_REL_ Kombi_PAG SG_ 1312 AB_Wickelklappung_Reihe2_MI 2000;
BA_REL_ "GenSigTimeoutTime" BU_SG_REL_ Kombi_PAG SG_ 1312 AB_Gurtschloss_FA 2000;
BA_REL_ "GenSigTimeoutTime" BU_SG_REL_ Kombi_PAG SG_ 1312 AB_Gurtschloss_BF 2000;
BA_REL_ "GenSigTimeoutTime" BU_SG_REL_ Kombi_PAG SG_ 1312 AB_Gurtschloss_Reihe2_FA 2000;
BA_REL_ "GenSigTimeoutTime" BU_SG_REL_ Kombi_PAG SG_ 1312 AB_Gurtschloss_Reihe2_MI 2000;
BA_REL_ "GenSigTimeoutTime" BU_SG_REL_ Kombi_PAG SG_ 1312 AB_Gurtschloss_Reihe2_BF 2000;
BA_REL_ "GenSigTimeoutTime" BU_SG_REL_ Kombi_PAG SG_ 1312 AB_Gurtschloss_Reihe3_FA 2000;
BA_REL_ "GenSigTimeoutTime" BU_SG_REL_ Kombi_PAG SG_ 1312 AB_Gurtschloss_Reihe3_MI 2000;
BA_REL_ "GenSigTimeoutTime" BU_SG_REL_ Kombi_PAG SG_ 1312 AB_Gurtschloss_Reihe3_BF 2000;
BA_REL_ "GenSigTimeoutTime" BU_SG_REL_ Kombi_PAG SG_ 1312 AB_Wickelklappung_Reihe2_BF 2000;
BA_REL_ "GenSigTimeoutTime" BU_SG_REL_ Kombi_PAG SG_ 1312 AB_Wickelklappung_Reihe2_FA 2000;
BA_REL_ "GenSigTimeoutTime" BU_SG_REL_ Kombi_PAG SG_ 674 Allrad_06_CRC 2000;
BA_REL_ "GenSigTimeoutTime" BU_SG_REL_ Kombi_PAG SG_ 674 Allrad_06_BZ 2000;
BA_REL_ "GenSigTimeoutTime" BU_SG_REL_ Kombi_PAG SG_ 674 ALR_Warnlampe 2000;
BA_REL_ "GenSigTimeoutTime" BU_SG_REL_ Kombi_PAG SG_ 674 ALR_Texte 2000;
BA_REL_ "GenSigTimeoutTime" BU_SG_REL_ Kombi_PAG SG_ 1633 AAG_BZ 1000;
BA_REL_ "GenSigTimeoutTime" BU_SG_REL_ Kombi_PAG SG_ 1633 AAG_AVS_Fehler_02_inv 1000;
BA_REL_ "GenSigTimeoutTime" BU_SG_REL_ Kombi_PAG SG_ 1633 AAG_Blinker_H_aktiv 1000;
BA_REL_ "GenSigTimeoutTime" BU_SG_REL_ Kombi_PAG SG_ 1633 AAG_Blinker_HL_def 1000;
BA_REL_ "GenSigTimeoutTime" BU_SG_REL_ Kombi_PAG SG_ 1633 AAG_Blinker_HR_def 1000;
BA_REL_ "GenSigTimeoutTime" BU_SG_REL_ Kombi_PAG SG_ 1633 AAG_Bremslicht_H_def 1000;
BA_REL_ "GenSigTimeoutTime" BU_SG_REL_ Kombi_PAG SG_ 1633 AAG_Schlusslicht_HL_def 1000;
BA_REL_ "GenSigTimeoutTime" BU_SG_REL_ Kombi_PAG SG_ 1633 AAG_Schlusslicht_HR_def 1000;
BA_REL_ "GenSigTimeoutTime" BU_SG_REL_ Kombi_PAG SG_ 1633 AAG_AVS_Fehler_02 1000;
BA_REL_ "GenSigTimeoutTime" BU_SG_REL_ Kombi_PAG SG_ 345 ARA_Knickwinkel_Konfidenz 1000;
BA_REL_ "GenSigTimeoutTime" BU_SG_REL_ Kombi_PAG SG_ 345 ARA_Texte 1000;
BA_REL_ "GenSigTimeoutTime" BU_SG_REL_ Kombi_PAG SG_ 345 ARA_Modus 1000;
BA_REL_ "GenSigTimeoutTime" BU_SG_REL_ Kombi_PAG SG_ 345 ARA_Aktiver_Grafikmodus 1000;
BA_REL_ "GenSigTimeoutTime" BU_SG_REL_ Kombi_PAG SG_ 345 ARA_Bremsfuss 1000;
BA_REL_ "GenSigTimeoutTime" BU_SG_REL_ Kombi_PAG SG_ 345 ARA_Knickwinkel_Komfort 1000;
BA_REL_ "GenSigTimeoutTime" BU_SG_REL_ Kombi_PAG SG_ 345 ARA_Knickwinkel_Max 1000;
BA_REL_ "GenSigTimeoutTime" BU_SG_REL_ Kombi_PAG SG_ 345 ARA_Knickwinkel_Soll 1000;
BA_REL_ "GenSigTimeoutTime" BU_SG_REL_ Kombi_PAG SG_ 345 ARA_Knickwinkel_Ist 1000;
VAL_ 2331596020 ACA_FoD_Status 0 "init" 1 "Funktion_inaktiv" 2 "Funktion_aktiv" ;
VAL_ 2331596020 ACC_Texte_03 0 "keine_Anzeige" 1 "ACC_nicht_ueber_FOD_freigeschalt" 2 "ACC_auswaehlen" 3 "ACC_verfuegbar" 4 "ACC_startet" 5 "GRA_startet" 6 "Hauptschalter_betaetigen" 7 "ACC_Stoerung" 8 "ACC_und_GRA_Stoerung" 9 "ACC_nicht_verfuegbar" 10 "ACC_und_GRA_nicht_verfuegbar" 11 "ACC_na_keine_Sensorsicht" 12 "ACC_na_Bremse_betaetigen" 13 "ACC_na_Steigung_zu_gross" 14 "ACC_na_Gefaelle_zu_gross" 15 "ACC_na_Parkbremse_betaetigt" 16 "GRA_na_Parkbremse_betaetigt" 17 "ACC_na_Bremse_betaetigt" 18 "GRA_na_Bremse_betaetigt" 19 "ACC_na_Fahrer_abwesend" 20 "ACC_na_Frontklappe_offen" 21 "GRA_na_Frontklappe_offen" 22 "ACC_na_Tuer_offen" 23 "GRA_na_Tuer_offen" 24 "ACC_na_WBA_aktiv" 25 "GRA_na_WBA_aktiv" 26 "ACC_na_Parkassistent_aktiv" 27 "GRA_na_Parkassistent_aktiv" 28 "ACC_na_HDC_betaetigt" 29 "GRA_na_HDC_betaetigt" 30 "ACC_na_ESC_Eingriff" 31 "GRA_na_ESC_Eingriff" 32 "ACC_na_nur_in_Fahrstufe_verfuegb" 33 "GRA_na_nur_in_Fahrstufe_verfuegb" 34 "ACC_na_Rueckwaertsgang_eingelegt" 35 "GRA_na_Rueckwaertsgang_eingelegt" 36 "ACC_na_rueckwaertsrollen" 37 "ACC_na_Fahrbereitschaft" 38 "ACC_na_Fzg_starten" 39 "GRA_na_Fzg_starten" 40 "ACC_na_Doppelbetaetigung" 41 "GRA_na_Doppelbetaetigung" 42 "ACC_na_Gangempfehlung" 43 "GRA_na_Gangempfehlung" 44 "ACC_na_zu_grosse_Verzoegerung" 45 "GRA_na_zu_grosse_Verzoegerung" 46 "GRA_na_Geschwindigkeitsgrenze" 47 "ACC_abg_Steigung_zu_gross" 48 "ACC_abg_Gefaelle_zu_gross" 49 "ACC_abg_Stillstand_verlassen" 50 "ACC_abg_keine_Sensorsicht" 51 "ACC_abg_nicht_fahrbereit" 52 "GRA_abg_nicht_fahrbereit" 53 "ACC_abg_Parkbremse_betaetigt" 54 "GRA_abg_Parkbremse_betaetigt" 55 "ACC_abg_ESC_Eingriff" 56 "GRA_abg_ESC_Eingriff" 57 "ACC_abg_ESC_aus" 58 "GRA_abg_ESC_aus" 59 "ACC_abg_Rueckwaertsgang_eingeleg" 60 "GRA_abg_Rueckwaertsgang_eingeleg" 61 "ACC_abg_nur_in_Fahrstufe_verfueg" 62 "GRA_abg_nur_in_Fahrstufe_verfueg" 63 "ACC_abg_Fahrer_abwesend" 64 "GRA_abg_Fahrer_abwesend" 65 "ACC_abg_Frontklappe_offen" 66 "GRA_abg_Frontklappe_offen" 67 "ACC_abg_Tuer_offen" 68 "GRA_abg_Tuer_offen" 69 "ACC_abg_WBA_aktiv" 70 "GRA_abg_WBA_aktiv" 71 "ACC_abg_Gangempfehlung" 72 "GRA_abg_Gangempfehlung" 73 "ACC_aus" 74 "GRA_aus" 75 "GRA_abg_Geschwindigkeitsgrenze" 76 "keine_Abstandsregelung" 77 "TA_startet" 78 "TA_na_Bremse_betaetigen" 79 "TA_na_Steigung_zu_gross" 80 "TA_na_Gefaelle_zu_gross" 81 "TA_na_Parkbremse_betaetigt" 82 "TA_na_Bremse_betaetigt" 83 "TA_na_Fahrer_abwesend" 84 "TA_na_Frontklappe_offen" 85 "TA_na_Tuer_offen" 86 "TA_na_WBA_aktiv" 87 "TA_na_Parkassistent_aktiv" 88 "TA_na_HDC_betaetigt" 89 "TA_na_ESC_Eingriff" 90 "TA_na_nur_in_Fahrstufe_verfuegb" 91 "TA_na_Rueckwaertsgang_eingelegt" 92 "TA_na_rueckwaertsrollen" 93 "TA_na_Fahrbereitschaft" 94 "TA_na_Fzg_starten" 95 "TA_na_Doppelbetaetigung" 96 "TA_na_Gangempfehlung" 97 "TA_na_zu_grosse_Verzoegerung" 98 "TA_abg_Steigung_zu_gross" 99 "TA_abg_Gefaelle_zu_gross" 100 "TA_abg_Stillstand_verlassen" 101 "TA_abg_nicht_fahrbereit" 102 "TA_abg_Parkbremse_betaetigt" 103 "TA_abg_ESC_Eingriff" 104 "TA_abg_ESC_aus" 105 "TA_abg_Rueckwaertsgang_eingeleg" 106 "TA_abg_nur_in_Fahrstufe_verfueg" 107 "TA_abg_Fahrer_abwesend" 108 "TA_abg_Frontklappe_offen" 109 "TA_abg_Tuer_offen" 110 "TA_abg_WBA_aktiv" 111 "TA_abg_Gangempfehlung" 112 "TA_Hauptschalter_betaetigen" 113 "GRA_nicht_verfuegbar" 114 "GRA_Stoerung" 115 "ACC_na_zurzeit_nicht_aktivierbar" 116 "GRA_na_zurzeit_nicht_aktivierbar" 117 "TA_na_zurzeit_nicht_aktivierbar" 118 "ACC_abg_Geschwindigkeitsgrenze" 119 "TA_abg_Geschwindigkeitsgrenze" 120 "ACC_abg_HDC_Eingriff" 121 "GRA_abg_HDC_Eingriff" 122 "TA_abg_HDC_Eingriff" 123 "ACC_abg_Kupplung_betaetigt" 124 "GRA_abg_Kupplung_betaetigt" 125 "TA_abg_Kupplung_betaetigt" 126 "ACC_na_Geschwindigkeitsgrenze" 127 "TA_na_Geschwindigkeitsgrenze" ;
VAL_ 2331596020 ACC_Texte_Sekundaeranz_03 0 "Keine_Anzeige" 1 "Kurve_voraus" 2 "Tempolimit_erkannt" 3 "Tempolimit_voraus" 4 "Kreuzung_voraus" 5 "Kreisverkehr_voraus" 6 "Stauende_voraus" 7 "Anfahrbereit" 8 "Ampel_horizontal_voraus" 9 "Ampel_vertikal_voraus" 10 "Stoppschild_voraus" 11 "Ampel_horizontal_erkannt" 12 "Ampel_vertikal_erkannt" 13 "Vorfahrt_beachten_voraus" 14 "Bumper_voraus" 15 "Kuppe_voraus" 16 "Hindernis_erkannt" 17 "TA_Anfahrbereit" 18 "TA_Hindernis_erkannt" 19 "Rechtskurve_voraus" 20 "Linkskurve_voraus" ;
VAL_ 2331596020 ACC_Kennlinie_Kurvenregler 0 "Init" 1 "Kennlinie_1" 2 "Kennlinie_2" 3 "Kennlinie_3" 4 "Kennlinie_4" 5 "Kennlinie_5" 6 "Kennlinie_6" ;
VAL_ 2331596020 ACC_Tempolimitassistent_Ein 0 "Tempolimitassistent_aus" 1 "Tempolimitassistent_ein" ;
VAL_ 2331596020 ACC_Charisma_FahrPr 0 "keine_Funktion" 1 "Programm_1" 2 "Programm_2" 3 "Programm_3" 4 "Programm_4" 5 "Programm_5" 6 "Programm_6" 7 "Programm_7" 8 "Programm_8" 9 "Programm_9" 10 "Programm_10" 11 "Programm_11" 12 "Programm_12" 13 "Programm_13" 14 "Programm_14" 15 "Programm_15" ;
VAL_ 2331596020 ACC_Charisma_Status 0 "Init" 1 "verfuegbar" 2 "nicht_verfuegbar" 3 "asynchron_durch_Fahrerwunsch" ;
VAL_ 678 ACC_Tempolimit 0 "keine_Anzeige" 1 "5_zulHoechstgeschw" 2 "7_zulHoechstgeschw" 3 "10_zulHoechstgeschw" 4 "15_zulHoechstgeschw" 5 "20_zulHoechstgeschw" 6 "25_zulHoechstgeschw" 7 "30_zulHoechstgeschw" 8 "35_zulHoechstgeschw" 9 "40_zulHoechstgeschw" 10 "45_zulHoechstgeschw" 11 "50_zulHoechstgeschw" 12 "55_zulHoechstgeschw" 13 "60_zulHoechstgeschw" 14 "65_zulHoechstgeschw" 15 "70_zulHoechstgeschw" 16 "75_zulHoechstgeschw" 17 "80_zulHoechstgeschw" 18 "85_zulHoechstgeschw" 19 "90_zulHoechstgeschw" 20 "95_zulHoechstgeschw" 21 "100_zulHoechstgeschw" 22 "110_zulHoechstgeschw" 23 "120_zulHoechstgeschw" 24 "130_zulHoechstgeschw" 25 "140_zulHoechstgeschw" 26 "150_zulHoechstgeschw" 27 "160_zulHoechstgeschw" 28 "200_zulHoechstgeschw" 30 "250_zulHoechstgeschw" 31 "Ende_zulHoechstgeschw" ;
VAL_ 678 ACC_Wunschgeschw_Farbe 0 "Grundfarbe" 1 "Farbe_1" ;
VAL_ 678 ACC_Warnung_Verkehrszeichen_1 0 "keine_Warnung_Initialwert" 1 "Warnung" ;
VAL_ 678 ACA_Querfuehrung 0 "keine_Anzeige_oder_init" 1 "passiv" 2 "aktiv" 3 "Warnung" ;
VAL_ 678 ACC_Regelung_AIO 0 "Regelung_Ampel_nicht_aktiv" 1 "Regelung_Ampel_aktiv" ;
VAL_ 678 ACC_Wunschgeschw_02 1023 "keine_Anzeige" ;
VAL_ 678 ACC_Abstandsindex_02 0 "Audi (Init), VW (passiv/aktiv_Freifahrt)" 1022 "aus_passiv" 1023 "aktiv_Freifahrt" ;
VAL_ 678 ACC_Display_Prio 0 "hoechste_Prio" 1 "mittlere_Prio" 2 "geringe_Prio" 3 "keine_Prio" ;
VAL_ 678 ACC_rel_Objekt_Zusatzanz 0 "keine Anzeige" 1 "Relevantes_Objekt_erkannt" 2 "Relevantes_Objekt_Abstandswarnung" ;
VAL_ 678 ACC_Gesetzte_Zeitluecke 0 "keine_Anzeige" 1 "Zeitluecke_1" 2 "Zeitluecke_2" 3 "Zeitluecke_3" 4 "Zeitluecke_4" 5 "Zeitluecke_5" 6 "nicht_definiert" 7 "nicht_definiert" ;
VAL_ 678 ACC_Optischer_Fahrerhinweis 0 "optischer_Fahrerhinweis_AUS" 1 "optischer_Fahrerhinweis_EIN" ;
VAL_ 678 ACC_Warnhinweis 0 "kein_Warnhinweis" 1 "Warnhinweis" ;
VAL_ 678 ACC_EGO_Fahrzeug 0 "keine_Anzeige" 1 "aktiv" 2 "Warnung" 3 "aktiv_stop" 4 "passiv" ;
VAL_ 678 ACC_Relevantes_Objekt_02 0 "keine_Anzeige" 1 "Relevantes_Objekt_erkannt" 2 "Relevantes_Objekt_Warnung" 3 "passiv" ;
VAL_ 678 ACC_Wunschgeschw_erreicht 0 "Wunschgeschwindigkeit_nicht_erreicht" 1 "Wunschgeschwindigkeit_erreicht" ;
VAL_ 678 ACC_Anzeige_Zeitluecke 0 "Anzeige_Zeitluecke_nicht_angefordert" 1 "Anzeige_Zeitluecke_angefordert" ;
VAL_ 678 ACC_Texte_Primaeranz_02 0 "keine Anzeige" 1 "VDA_ACC_Symbol_YYY_kmh_mph" 2 "Kurven_Symbol_YYY_kmh_mph" 3 "Tempolimit_Symbol_YYY_kmh_mph" 4 "ACC_anfahrbereit" 5 "eingestellte_Zeitluecke" 6 "Tuer offen !" 7 "Stehendes Objekt voraus" 8 "o  o  o" 9 "ACC aus" 10 "ACC startet" 11 "ACC Sensor Sicht !" 12 "ACC nicht verfuegbar" 13 "ACC Fehler" 14 "ESP Eingriff" 15 "ESP PASSIV !" 16 "Parkbremse !" 17 "Geschwindigkeitsgrenze" 18 "Waehlhebelposition !" 19 "Fahrer Gurtschloss offen !" 20 "Schalthebelposition !" 21 "Drehzahl !" 22 "HDC aktiv" 23 "Kupplung betaetigt" 24 "Gang einlegen !" 25 "Bremse ueberhitzt !" 26 "Steigung_Gefaelle_zu_gross" 27 "ABSTAND" 28 "Rechtsueberholen_verhindert" 29 "Linksueberholen_verhindert" 30 "Kreuzungs_Symbol" 31 "Kreisverkehr_Symbol" 32 "Gefaelle_Symbol" 33 "Tempolimit_Kurvenassistent_ein" 34 "Kurvenassistent_ein" 35 "Tempolimitassistent_ein" 36 "Achtung_Geschwindigkeitsueberschreitung" 37 "Tempolimit_und_Kurvenassistent_nicht_verfuegbar" 38 "Tempolimit_nicht_verfuegbar" 39 "Kurvenassistent_nicht_verfuegbar" 40 "Autobahnausfahrt_Symbol" 41 "Stauende_Symbol" 42 "Engstelle_Symbol" 43 "STP_verfuegbar" 44 "Ampel_vertikal" 45 "Ampel_horizontal" 46 "STA_verfuegbar" ;
VAL_ 678 ACC_Texte_Zusatzanz_02 0 "keine_Anzeige" 1 "ACC_AUS" 2 "Standby" 3 "UEBERTRETEN" 4 "ABSTAND" 5 "DISTANZ_1" 6 "DISTANZ_2" 7 "DISTANZ_3" 8 "DISTANZ_4" 9 "DISTANZ_5" 10 "DISTANZ_1__dyn" 11 "DISTANZ_2__dyn" 12 "DISTANZ_3__dyn" 13 "DISTANZ_4__dyn" 14 "DISTANZ_5__dyn" 15 "DISTANZ_1__comf" 16 "DISTANZ_2__comf" 17 "DISTANZ_3__comf" 18 "DISTANZ_4__comf" 19 "DISTANZ_5__comf" 20 "DISTANZ_1__efficiency" 21 "DISTANZ_2__efficiency" 22 "DISTANZ_3__efficiency" 23 "DISTANZ_4__efficiency" 24 "DISTANZ_5__efficiency" 25 "DISTANZ_1__Stau" 26 "DISTANZ_2__Stau" 27 "DISTANZ_3__Stau" 28 "DISTANZ_4__Stau" 29 "DISTANZ_5__Stau" 30 "ACHTUNG" 31 "Abstandsanzeige" 32 "Abstandsanzeige_Warnung_aktiviert" 33 "STA_verfuegbar" 34 "Engstelle" 35 "RUV_aktiv_Rechtsverkehr" 36 "RUV_aktiv_Linksverkehr" 37 "STP_Verfuegbar" 38 "AW_Warnschwelle_1" 39 "AW_Warnschwelle_2" 40 "AW_Warnschwelle_3" 41 "AW_Warnung_1" 42 "AW_Warnung_2" 43 "AW_Warnung_3" ;
VAL_ 678 STA_Primaeranz 0 "keine_Anzeige" 1 "STA_standby" 2 "STA_aktiv" 3 "STA_Warnung" ;
VAL_ 679 ACC_Regelgeschw 1023 "keine_Anzeige" ;
VAL_ 679 ACC_Einheit_maxSetzgeschw 0 "kmh" 1 "mph" ;
VAL_ 679 ACC_maxSetzgeschw 511 "Init_Neutralwert" ;
VAL_ 679 ACC_minRegelgeschw 255 "keine_Anzeige" ;
VAL_ 679 ACC_maxRegelgeschw 255 "keine_Anzeige" ;
VAL_ 679 ACC_Tempolimitassistent_02 0 "keine_Anzeige" 1 "Tempolimit" 2 "Gefaelle" 3 "Steigung" 4 "Kuppe" 5 "Ortsanfang" 6 "Ampel" 7 "Bahnuebergang" ;
VAL_ 679 ACC_Tempolimit_Einheit 0 "kmh_init" 1 "mph" ;
VAL_ 679 ACC_Kurvenassistent 0 "keine_Anzeige" 1 "Kreuzung" 2 "Rechtskurve" 3 "Linkskurve" 4 "Kreisverkehr" 5 "Autobahnabfahrt" 6 "Stauende" 7 "Engstelle" ;
VAL_ 679 ACC_RUV 0 "keine_Anzeige" 1 "RUV_aktiv_Rechtsverkehr" 2 "RUV_aktiv_Linksverkehr" ;
VAL_ 679 ACC_Tachokranz 0 "Tachokranz_nicht_beleuchtet" 1 "Tachokranz_beleuchtet" ;
VAL_ 679 ACC_Typ_Tachokranz_unten 0 "LEDs_an" 1 "LEDs_aus" ;
VAL_ 679 ACC_ENG_Texte 0 "keine_Anzeige" 1 "keine_Laenderverfuegbarkeit" 2 "nicht_verfuegbar" 3 "Geschwindigkeitsgrenze" ;
VAL_ 679 ACC_Status_GRA_Modus 0 "GRA_Modus_nicht_verfuegbar" 1 "GRA_Modus_verfuegbar_nicht_aktiv" 2 "GRA_Modus_verfuegbar_aktiv" ;
VAL_ 680 ACA_Querfuehrung_Texte 0 "keine_Anzeige" 1 "nicht_verfuegbar" 2 "keine_Sensorsicht" 3 "Fahreruebernahme" ;
VAL_ 680 ACA_Hinweistexte 0 "keine_Anzeige" 1 "QF_eingeschaltet" 2 "QF_ausgeschaltet" ;
VAL_ 680 ACC_FoD_Status 0 "Init" 1 "Funktion_inaktiv" 2 "Funktion_aktiv" ;
VAL_ 680 ACC_Texte_Abstandswarner 0 "keine_Anzeige" 1 "Systemstoerung" 2 "keine_Sensorsicht" 3 "zurzeit_eingeschraenkt" ;
VAL_ 680 ACC_Vorz_Abstandswarner 0 "keine_Anzeige" 1 "kleiner" 2 "groesser" 3 "kleiner_Warnung" ;
VAL_ 680 ACC_Texte_Sekundaeranz 0 "keine_Anzeige" 1 "Zielfahrzeug_erkannt" 2 "Rechtskurve_voraus" 3 "Linkskurve_voraus" 4 "Tempolimit_voraus" 5 "Sensorsicht" 6 "Anfahrbereit" 7 "Tempolimit_erkannt" 8 "Kreuzung_voraus" 9 "Kreisverkehr_voraus" 10 "Autobahnabfahrt_voraus" 11 "Stauende_voraus" 12 "Gefaelle_voraus" 13 "Hindernis_erkannt" 14 "TA_Hindernis_erkannt" 15 "TA_Anfahrbereit" ;
VAL_ 680 ACC_Status_Anzeige 0 "ACC_GRA_Hauptschalter_aus" 1 "ACC_in_Init_nicht_bei_GRA" 2 "ACC_GRA_passiv" 3 "ACC_GRA_aktiv" 4 "ACC_GRA_im_Hintergrund_uebertreten" 5 "ACC_GRA_Abschaltreaktion" 6 "ACC_reversibel_aus_nicht_bei_GRA" 7 "ACC_GRA_irreversibel_aus" ;
VAL_ 680 ACC_Akustik_03 0 "keine_Akustik" 1 "niederpriore_Akustik" 2 "mittelpriore_Akustik" 3 "hochpriore_Akustik" 4 "hochpriore_Dauerakustik" 5 "hochpriore_Dauerakustik_02" ;
VAL_ 680 ACC_Geschw_Zielfahrzeug 1023 "Neutralwert" ;
VAL_ 680 ACC_Texte 0 "keine_Anzeige" 1 "ACC_nicht_verfuegbar" 2 "ACC_und_AWV_nicht_verfuegbar" 3 "ACC_keine_Sensorsicht" 4 "ACC_und_AWV_keine_Sensorsicht" 5 "ACC_Steigung_zu_gross" 6 "ACC_nur_in_Fahrstufe_verfuegbar" 7 "ACC_Parkbremse_betaetigt" 8 "ACC_ESP_Eingriff" 9 "ACC_Bitte_uebernehmen" 10 "ACC_HDC_betaetigt" 11 "ACC_Geschwindigkeitsgrenze" 12 "ACC_Schalthebelposition" 13 "ACC_Drehzahl" 14 "ACC_Kupplung_betaetigt" 15 "ACC_Aktivierverhinderung" 16 "ACC_Abschaltung" 17 "ACC_Parkassistent_aktiv" 18 "ACC_ESC_aus" 19 "ACC_Charisma_Modus_inkompatibel" 20 "ACC_Stehendes_Objekt_voraus" 21 "ACC_Stoerung" 22 "ACC_eingeschraenkte_Funktion" 23 "ACC_Manoevrierassistent_aktiv" ;
VAL_ 680 ACC_STA_Text 0 "ACC_Text" 1 "ACC_STA_Text" ;
VAL_ 680 STA_Texte 0 "keine_Anzeige" 1 "STA_nicht_verfuegbar" 2 "STA_Fahreruebernahme" 3 "STA_Constant_brake_mode" 4 "STA_Gurtschloss_nicht_gesteckt" 5 "STA_Fahrzeugeschw_zu_hoch" 6 "STA_Freifahrt" 7 "STA_Systemgrenze" ;
VAL_ 680 AbstWarn_LRR_FAS_Fkt_Status 0 "Init" 1 "Funktion_Ist_Ein" 2 "Funktion_Ist_Aus" 3 "Fehler" ;
VAL_ 680 STA_Zusatzanz 0 "keine_Anzeige" 1 "STA_verfuegbar" 2 "STA_aktiv" 3 "STA_Warnung" ;
VAL_ 680 FAS_Licht_Anf 0 "keine_Anforderung" 1 "Anforderung" ;
VAL_ 680 ACC_Zeitluecke_Abstandswarner 61 "Freifahrt" 62 "nicht_definiert" 63 "keine_Anzeige" ;
VAL_ 680 ACC_Abstand_Abstandswarner 509 "Freifahrt" 510 "nicht_definiert" 511 "keine_Anzeige" ;
VAL_ 680 ACC_Einheit_Abstandswarner 0 "Meter" 1 "Yard" ;
VAL_ 681 AWV_Warnung 0 "keine_Anzeige" 1 "latente_Vorwarnung" 2 "Vorwarnung" 3 "Akutwarnung" 4 "Eingriff" 5 "Fahreruebernahmeaufforderung" 6 "Querinfo_1" 7 "Querinfo_2" ;
VAL_ 681 AWV_LED_Leiste 0 "keine_Anzeige" 1 "Stufe_1_glimmen" 2 "Stufe_2_leuchten" 3 "nicht_definiert" ;
VAL_ 681 AWV_Texte 0 "keine_Anzeige" 1 "Systemstoerung" 2 "keine_Sensorsicht" 3 "Initialisierung_gelb" 4 "System_aus" 5 "Initialisierung" 6 "ESC_aus" 7 "zurzeit_eingeschraenkt" ;
VAL_ 681 AWV_Status_Anzeige 0 "Init" 1 "verfuegbar" 2 "nicht_verfuegbar" ;
VAL_ 681 AWV_Einstellung_System_FSG 0 "deaktiviert" 1 "aktiviert" ;
VAL_ 681 AWV_Einstellung_Warnung_FSG 0 "Aus" 1 "Setting_2" 2 "Setting_3" 3 "Setting_4" 4 "Setting_5" 5 "Ein" ;
VAL_ 681 ACC_Status_Kurvenassistent 0 "deaktiviert" 1 "aktiviert_basis" 2 "aktiviert_langsam" 3 "aktiviert_mittel" 4 "aktiviert_schnell" 5 "Fehler" ;
VAL_ 681 ACC_Status_Tempolimitassistent 0 "deaktiviert" 1 "aktiviert_basis" 2 "aktiviert_mit_Toleranz" 3 "aktiviert_mit_Offset" 4 "Fehler" ;
VAL_ 681 AWV_Warnlevel 0 "keine_Gefaehrdung" 63 "max_Gefaehrdung" ;
VAL_ 614 ACC_Fahrprogramm_PACC 0 "comfort" 1 "standard" 2 "dynamic" 3 "ecological" 4 "reserved" ;
VAL_ 614 ACC_PEA_Einheit_Geschw 0 "kmh" 1 "mph" ;
VAL_ 614 ACC_PEA_LernenderFahrerOffset 0 "Init" 63 "Fehler" ;
VAL_ 614 ACC_Nutzung_VZ_PACC 0 "Nutzung_VZ_aktiv" 1 "Nutzung_VZ_inaktiv" ;
VAL_ 614 ACC_Regelung_durch_PACC 0 "ACC_Anf_gewinnt" 1 "PACC_Anf_gewinnt" ;
VAL_ 614 ACC_Sensibilitaet_PACC 0 "TL_aus_SV_aus" 1 "TL_an_SV_aus" 2 "TL_aus_SV_an" 3 "Tempolimit_an_Strassenverlauf_an" ;
VAL_ 2331595865 ACC_HMI_Obj_01_Spurzuordnung 0 "Init" 1 "links" 2 "rechts" 3 "Ego" ;
VAL_ 2331595865 ACC_HMI_Obj_01_Typ 0 "invalid" 1 "Fussgaenger" 2 "LKW" 3 "PKW" 4 "Motorrad" 5 "Radfahrer" 6 "unbekannt" ;
VAL_ 2331595865 ACC_HMI_Obj_01_LaengsRegelung 0 "Objektegelung_inaktiv" 1 "Objektegelung_aktiv" ;
VAL_ 2331595865 ACC_HMI_Obj_01_QuerRegelung 0 "Objektegelung_inaktiv" 1 "Objektegelung_aktiv" ;
VAL_ 2331595865 ACC_HMI_Obj_02_Spurzuordnung 0 "Init" 1 "links" 2 "rechts" 3 "Ego" ;
VAL_ 2331595865 ACC_HMI_Obj_02_Typ 0 "invalid" 1 "Fussgaenger" 2 "LKW" 3 "PKW" 4 "Motorrad" 5 "Radfahrer" 6 "unbekannt" ;
VAL_ 2331595865 ACC_HMI_Obj_02_LaengsRegelung 0 "Objektegelung_inaktiv" 1 "Objektegelung_aktiv" ;
VAL_ 2331595865 ACC_HMI_Obj_02_QuerRegelung 0 "Objektegelung_inaktiv" 1 "Objektegelung_aktiv" ;
VAL_ 2331595866 ACC_HMI_Obj_03_Spurzuordnung 0 "Init" 1 "links" 2 "rechts" 3 "Ego" ;
VAL_ 2331595866 ACC_HMI_Obj_03_Typ 0 "invalid" 1 "Fussgaenger" 2 "LKW" 3 "PKW" 4 "Motorrad" 5 "Radfahrer" 6 "unbekannt" ;
VAL_ 2331595866 ACC_HMI_Obj_03_LaengsRegelung 0 "Objektegelung_inaktiv" 1 "Objektegelung_aktiv" ;
VAL_ 2331595866 ACC_HMI_Obj_03_QuerRegelung 0 "Objektegelung_inaktiv" 1 "Objektegelung_aktiv" ;
VAL_ 2331595866 ACC_HMI_Obj_04_Spurzuordnung 0 "Init" 1 "links" 2 "rechts" 3 "Ego" ;
VAL_ 2331595866 ACC_HMI_Obj_04_Typ 0 "invalid" 1 "Fussgaenger" 2 "LKW" 3 "PKW" 4 "Motorrad" 5 "Radfahrer" 6 "unbekannt" ;
VAL_ 2331595866 ACC_HMI_Obj_04_LaengsRegelung 0 "Objektegelung_inaktiv" 1 "Objektegelung_aktiv" ;
VAL_ 2331595866 ACC_HMI_Obj_04_QuerRegelung 0 "Objektegelung_inaktiv" 1 "Objektegelung_aktiv" ;
VAL_ 2331595867 ACC_HMI_Obj_05_Spurzuordnung 0 "Init" 1 "links" 2 "rechts" 3 "Ego" ;
VAL_ 2331595867 ACC_HMI_Obj_05_Typ 0 "invalid" 1 "Fussgaenger" 2 "LKW" 3 "PKW" 4 "Motorrad" 5 "Radfahrer" 6 "unbekannt" ;
VAL_ 2331595867 ACC_HMI_Obj_05_LaengsRegelung 0 "Objektegelung_inaktiv" 1 "Objektegelung_aktiv" ;
VAL_ 2331595867 ACC_HMI_Obj_05_QuerRegelung 0 "Objektegelung_inaktiv" 1 "Objektegelung_aktiv" ;
VAL_ 2331595867 ACC_HMI_Obj_06_Spurzuordnung 0 "Init" 1 "links" 2 "rechts" 3 "Ego" ;
VAL_ 2331595867 ACC_HMI_Obj_06_Typ 0 "invalid" 1 "Fussgaenger" 2 "LKW" 3 "PKW" 4 "Motorrad" 5 "Radfahrer" 6 "unbekannt" ;
VAL_ 2331595867 ACC_HMI_Obj_06_LaengsRegelung 0 "Objektegelung_inaktiv" 1 "Objektegelung_aktiv" ;
VAL_ 2331595867 ACC_HMI_Obj_06_QuerRegelung 0 "Objektegelung_inaktiv" 1 "Objektegelung_aktiv" ;
VAL_ 2331595868 ACC_HMI_Nachb_li_belegt 0 "Nebenspur_frei" 1 "Nebenspur_belegt" ;
VAL_ 2331595868 ACC_HMI_Nachb_re_belegt 0 "Nebenspur_frei" 1 "Nebenspur_belegt" ;
VAL_ 2331595868 ACC_HMI_Spurwechsel_li 0 "kein_Spurwechselsprung_erkannt" 1 "Spurwechselsprung_nach_links" ;
VAL_ 2331595868 ACC_HMI_Spurwechsel_re 0 "kein_Spurwechselsprung_erkannt" 1 "Spurwechselsprung_nach_rechts" ;
VAL_ 2331595869 ACC_HMI_Egospur_li_Typ 0 "invalid" 1 "Gruenstreifen" 2 "Durchgezogen" 3 "Gestrichelt" 4 "Randbebauung" 5 "Doppellinien" 6 "Bots_Dots" 7 "unbekannt" ;
VAL_ 2331595869 ACC_HMI_Egospur_re_Typ 0 "invalid" 1 "Gruenstreifen" 2 "Durchgezogen" 3 "Gestrichelt" 4 "Randbebauung" 5 "Doppellinien" 6 "Bots_Dots" 7 "unbekannt" ;
VAL_ 2331595869 ACC_HMI_Nachb_li_Typ 0 "invalid" 1 "Gruenstreifen" 2 "Durchgezogen" 3 "Gestrichelt" 4 "Randbebauung" 5 "Doppellinien" 6 "Bots_Dots" 7 "unbekannt" ;
VAL_ 2331595869 ACC_HMI_Nachb_re_Typ 0 "invalid" 1 "Gruenstreifen" 2 "Durchgezogen" 3 "Gestrichelt" 4 "Randbebauung" 5 "Doppellinien" 6 "Bots_Dots" 7 "unbekannt" ;
VAL_ 2331595870 ACC_HMI_TrajektSeg1_Valid 0 "Ego_Trajektorie_invalid" 1 "Ego_Trajektorie_valid" ;
VAL_ 2331595871 ACC_HMI_ZoomstufeAktiv 0 "inaktiv" 1 "aktiv" ;
VAL_ 2331595871 ACC_HMI_Kurvenwarnung 0 "keine_Warnung" 1 "Warnung" ;
VAL_ 2331595871 ACC_HMI_TrajektFarbe_li 0 "inaktiv" 1 "weiss" 2 "grau" 3 "gruen" 4 "gelb" 5 "rot" 6 "blau" 7 "reserviert" ;
VAL_ 2331595871 ACC_HMI_TrajektFarbe_re 0 "inaktiv" 1 "weiss" 2 "grau" 3 "gruen" 4 "gelb" 5 "rot" 6 "blau" 7 "reserviert" ;
VAL_ 2331595971 ACC_HMI_ZeitlueckenAuswahl 0 "inaktiv" 1 "Zeitluecke_01_aktiv" 2 "Zeitluecke_02_aktiv" 3 "Zeitluecke_03_aktiv" 4 "Zeitluecke_04_aktiv" 5 "Zeitluecke_05_aktiv" 6 "reserviert" ;
VAL_ 2527679927 ADA_HMI_Muedigkeit_Event_Meldung 0 "keine_Meldung" 1 "Sekundenschlaf" 2 "Augen_geschlossen" 3 "Gaehnen" ;
VAL_ 2527679927 ADA_HMI_Ablenkung_Deaktivierung 0 "keine_Meldung" 1 "Ablenkung_deaktiviert" ;
VAL_ 2527679927 ADA_HMI_Ablenkung_Meldung 0 "keine_Meldung" 1 "Meldung1" 2 "Meldung2" 3 "Meldung3" ;
VAL_ 2527679927 ADA_HMI_Muedigkeit_Fehler_Popup 0 "keine_Meldung" 1 "Muedigkeit_eingesch_verfuegbar" 2 "Muedigkeit_nicht_verfuegbar" 3 "reserviert" ;
VAL_ 2527679927 ADA_HMI_Ablenkung_Fehler_Popup 0 "keine_Meldung" 1 "Ablenkung_eingesch_verfuegbar" 2 "Ablenkung_nicht_verfuegbar" 3 "reserviert" ;
VAL_ 2527679927 ADA_AttentionLevel 126 "Init" 127 "Fehler" ;
VAL_ 2527679927 ADA_HMI_Muedigkeit_Deaktivierung 0 "keine_Meldung" 1 "Muedigkeit_deaktiviert" ;
VAL_ 2527679927 ADA_DistractionLevel 125 "Ausgeschaltet" 126 "Init" 127 "Fehler" ;
VAL_ 2527679927 ADA_HMI_Ablenkung_Meldeakustik 0 "Meldeakustik" 1 "keine_Meldeakustik" ;
VAL_ 2527679927 ADA_DrowsinessLevel 125 "Ausgeschaltet" 126 "Init" 127 "Fehler" ;
VAL_ 2527679927 ADA_HMI_Muedigkeit_Meldeakustik 0 "Meldeakustik" 1 "keine_Meldeakustik" ;
VAL_ 2527679927 ADA_HMI_Muedigkeit_Meldung 0 "keine_Meldung" 1 "Meldung1" 2 "Meldung2" 3 "Meldung3" 4 "Meldung_Pausenempfehlung" 5 "reserviert" 6 "reserviert" 7 "reserviert" ;
VAL_ 2527679927 ADA_DrowsinessSystemState 0 "init" 1 "off" 2 "inactive" 3 "active" 4 "restrictedMode" 5 "reversibleOff" 6 "irreversibleOff" 7 "error" ;
VAL_ 2527679927 ADA_HMI_Fahrzeit_seit_Pause 1023 "keine_Ausgabe" ;
VAL_ 232 AFR_gMeter_ay 1022 "Init" 1023 "Fehler" ;
VAL_ 232 AFR_gMeter_ax 1022 "Init" 1023 "Fehler" ;
VAL_ 232 AFR_Standfkt_Status 0 "keine_Anforderung_wird_ausgefuehrt" 1 "System_wird_initialisiert" 2 "verfuegbar" 3 "Anforderung_wird_ausgefuehrt" 4 "nicht_verfuegbar_Schluessel_Reichw" 5 "nicht_verfuegbar_Geschwindigkeit" 6 "nicht_verfuegbar_System" 7 "nicht_verfuegbar_reserved" ;
VAL_ 232 AFR_StandfktSchluesselAktivieren 0 "keine_Anforderung" 1 "Funktion_aktivieren" 2 "Funktion_deaktivieren" ;
VAL_ 232 AFR_Schluesselsuche_Anf 0 "keine_Anforderung_Schluesselsuche" 1 "Anforderung_Schluesselsuche" ;
VAL_ 1660 E_Sound_Texte 0 "keine_Anzeige" 1 "Aussensound_defekt" 2 "Aussensound_deaktiviert" 3 "Aussensound_deaktiviert_reduziertWarn" 4 "Aussensound_aktiviert" 5 "Aussensound_deaktiviert_KL15" 7 "Fehler" ;
VAL_ 1660 E_Sound_verbaut 0 "nicht_verbaut" 1 "verbaut" ;
VAL_ 1660 AGA_Charisma_FahrPr 0 "keine_Funktion" 1 "Programm_1" 2 "Programm_2" 3 "Programm_3" 4 "Programm_4" 5 "Programm_5" 6 "Programm_6" 7 "Programm_7" 8 "Programm_8" 9 "Programm_9" 10 "Programm_10" 11 "Programm_11" 12 "Programm_12" 13 "Programm_13" 14 "Programm_14" 15 "Programm_15" ;
VAL_ 1660 AGA_Charisma_Status 0 "Init" 1 "verfuegbar" 2 "nicht_verfuegbar" 3 "asynchron_durch_Fahrerwunsch" ;
VAL_ 1660 E_Sound_ohne_Funktion 0 "kein_Fehler" 1 "Fehler" ;
VAL_ 1660 AGA_Verstaerker_Mute 0 "Mute" 1 "Kein_Mute" ;
VAL_ 1660 E_Sound_Mute_Icon 0 "Icon_aus" 1 "Icon_ein" 2 "Icon_blinken" 3 "Init" ;
VAL_ 1660 E_Sound_Mute_LED 0 "LED_aus" 1 "LED_ein" 2 "LED_blinken" 3 "Init" ;
VAL_ 64 AB_RGS_Anst 4 "aktiv_Niveau_1" 5 "aktiv_Niveau_2" 6 "aktiv_Niveau_3" 7 "aktiv_Niveau_4" 8 "deaktiviert" ;
VAL_ 64 AB_Front_Crash 0 "kein_Front_Crash" 1 "Front_Crash" ;
VAL_ 64 AB_Heck_Crash 0 "kein_Heck_Crash" 1 "Heck_Crash" ;
VAL_ 64 AB_SF_Crash 0 "kein_Seiten_Crash_Fahrer" 1 "Seiten_Crash_Fahrer" ;
VAL_ 64 AB_SB_Crash 0 "kein_Seiten_Crash_Beifahrer" 1 "Seiten_Crash_Beifahrer" ;
VAL_ 64 AB_Rollover_Crash 0 "kein_Rollover" 1 "Rollover" ;
VAL_ 64 AB_Crash_Int 0 "kein_Crash" 1 "Crash_Intensitaet_1" 2 "Crash_Intensitaet_2_(nur_Stellgliedtest_MLB_B8)" 3 "Crash_Intensitaet_2_(nur_D4_C7_Colorado_NF_PAG__Crash_im_MLB_B8)" 4 "Crash_Intensitaet_3_(alt_VW/AUDI__Stellgliedtest_MLB_B8)" 5 "Crash_Intensitaet_3_(alt_PAG)" 7 "Crash_Intensitaet_3" ;
VAL_ 64 AB_Lampe 0 "Aus" 1 "Ein" ;
VAL_ 64 AB_Deaktiviert 0 "aktiv" 1 "deaktiviert" ;
VAL_ 64 AB_VB_deaktiviert 0 "Beifahrerairbag_aktiv" 1 "Beifahrerairbag_deaktiviert" ;
VAL_ 64 AB_Systemfehler 0 "kein_Fehler" 1 "Airbag_Systemfehler" ;
VAL_ 64 AB_Diagnose 0 "nicht_in_Diagnose" 1 "in_Diagnose" ;
VAL_ 64 AB_Stellgliedtest 0 "nicht_im_Stellgliedtest" 1 "Airbag_im_Stellgliedtest" ;
VAL_ 64 AB_Erh_Auf_VB 0 "keine_Anzeige" 1 "Beifahrerairbag_deaktiviert" 2 "Beifahrerairbag_aktiviert" 3 "nicht_definiert" ;
VAL_ 64 AB_Gurtwarn_VF 0 "keine_Warnung" 1 "Gurtwarnung_ausloesen" ;
VAL_ 64 AB_Gurtwarn_VB 0 "keine_Warnung" 1 "Gurtwarnung_ausloesen" ;
VAL_ 64 AB_Anzeige_Fussg 0 "keine_FSG_Aktion_ausgeloest" 1 "Motorhaube_offen" 2 "Systemfehler" ;
VAL_ 64 AB_Texte_AKS 0 "keine_AKS_Ausloesung" 1 "AKS_ausgeloest" 2 "AKS_Systemfehler" ;
VAL_ 64 AB_MKB_gueltig 0 "Multikollisionsbremsung_nicht_freigeschaltet" 1 "Multikollisionsbremsung_freigeschaltet" ;
VAL_ 64 AB_MKB_Anforderung 0 "Multikollisionsbremsung_nicht_angefordert" 1 "Multikollisionsbremsung_angefordert" ;
VAL_ 64 AB_Versorgungsspannung 0 "plausibel" 1 "unplausibel" ;
VAL_ 64 AB_Deaktivierung_HV 0 "keine_Deaktivierung" 1 "Deaktivierung_1" 2 "Deaktivierung_2" 3 "Deaktivierung_3" 4 "Deaktivierung_4" 5 "Deaktivierung_5" 6 "Deaktivierung_6" 7 "Fehler" ;
VAL_ 64 AB_EDR_Trigger 0 "No_Event" 1 "Start_Event" 2 "NonDeployment_Event" 3 "Deployment_Event" ;
VAL_ 64 AB_Belegung_VF 0 "nicht_verfuegbar" 1 "Fehler" 2 "nicht_belegt" 3 "belegt" ;
VAL_ 64 SC_LowSpeedCrashErkannt 0 "kein_Crash_erkannt" 1 "Crash_Frontbereich_erkannt" 2 "Crash_Heckbereich_erkannt" 3 "Crash_Front_und_Heckbereich_erkannt" ;
VAL_ 64 SC_Masterzeit 127 "Init" ;
VAL_ 1312 LoGeWa_Event_Kombiwarnung 0 "Init" 1 "Unfall" 2 "Traktionsverlust" 3 "Panne" 4 "Sichtbehinderung" 5 "Aquaplaning" ;
VAL_ 1312 AB_Anforderung_eCall 0 "keine_Anforderung" 1 "Anforderung" ;
VAL_ 1312 AB_Anprall_Seite_Beifahrer 0 "kein_Anprall" 1 "Anprall_erkannt" ;
VAL_ 1312 AB_Anprall_Rollover 0 "kein_Anprall" 1 "Anprall_erkannt" ;
VAL_ 1312 AB_Anprall_FGS 0 "kein_Anprall" 1 "Anprall_erkannt" ;
VAL_ 1312 AB_Anprall_Front_Beifahrer 0 "kein_Anprall" 1 "Anprall_erkannt" ;
VAL_ 1312 AB_Anprall_Front_Fahrer 0 "kein_Anprall" 1 "Anprall_erkannt" ;
VAL_ 1312 AB_Anprall_Heck_Beifahrer 0 "kein_Anprall" 1 "Anprall_erkannt" ;
VAL_ 1312 AB_Anprall_Heck_Fahrer 0 "kein_Anprall" 1 "Anprall_erkannt" ;
VAL_ 1312 AB_Wickelklappung_Reihe2_MI 0 "nicht_verbaut" 1 "nicht_verfuegbar__Fehler_oder_Init" 2 "nicht_verriegelt" 3 "verriegelt" ;
VAL_ 1312 AB_Belegung_VB 0 "nicht_verfuegbar" 1 "Fehler" 2 "nicht_belegt" 3 "belegt" ;
VAL_ 1312 AB_Abschaltanf_SIH_BF 0 "Normalbetrieb" 1 "Abschaltung_angefordert" ;
VAL_ 1312 AB_Anprall_Seite_Fahrer 0 "kein_Anprall" 1 "Anprall_erkannt" ;
VAL_ 1312 SC_PAO_Schriftzug_Anf 0 "LED aus" 1 "LED an" 2 "LED blinken" 3 "reserviert" ;
VAL_ 1312 SC_PAO_ON_Anf 0 "LED aus" 1 "LED an" 2 "LED blinken" 3 "reserviert" ;
VAL_ 1312 SC_PAO_OFF_Anf 0 "LED aus" 1 "LED an" 2 "LED blinken" 3 "reserviert" ;
VAL_ 1312 AB_Crashschwere 0 "kein_Ereignis" 1 "Crashschwere_1" 2 "Crashschwere_2" 3 "Crashschwere_3" 4 "Crashschwere_4" 5 "Crashschwere_5" 6 "Crashschwere_2_bis_5" 7 "Fehler" ;
VAL_ 1312 AB_Anforderung_USM 0 "keine_Anforderung" 1 "Anforderung" ;
VAL_ 1312 AB_Gurtschloss_FA 0 "nicht_verbaut" 1 "nicht_verfügbar (Fehler oder Init)" 2 "nicht_gesteckt" 3 "gesteckt" ;
VAL_ 1312 AB_Gurtschloss_BF 0 "nicht_verbaut" 1 "nicht_verfügbar (Fehler oder Init)" 2 "nicht_gesteckt" 3 "gesteckt" ;
VAL_ 1312 AB_Gurtschloss_Reihe2_FA 0 "nicht_verbaut" 1 "nicht_verfügbar (Fehler oder Init)" 2 "nicht_gesteckt" 3 "gesteckt" ;
VAL_ 1312 AB_Gurtschloss_Reihe2_MI 0 "nicht_verbaut" 1 "nicht_verfügbar (Fehler oder Init)" 2 "nicht_gesteckt" 3 "gesteckt" ;
VAL_ 1312 AB_Gurtschloss_Reihe2_BF 0 "nicht_verbaut" 1 "nicht_verfügbar (Fehler oder Init)" 2 "nicht_gesteckt" 3 "gesteckt" ;
VAL_ 1312 AB_Gurtschloss_Reihe3_FA 0 "nicht_verbaut" 1 "nicht_verfügbar (Fehler oder Init)" 2 "nicht_gesteckt" 3 "gesteckt" ;
VAL_ 1312 AB_Gurtschloss_Reihe3_MI 0 "nicht_verbaut" 1 "nicht_verfügbar (Fehler oder Init)" 2 "nicht_gesteckt" 3 "gesteckt" ;
VAL_ 1312 AB_Gurtschloss_Reihe3_BF 0 "nicht_verbaut" 1 "nicht_verfügbar (Fehler oder Init)" 2 "nicht_gesteckt" 3 "gesteckt" ;
VAL_ 1312 AB_Sitzpos_Sens_FA 0 "nicht verfügbar" 1 "Fehler" 2 "Sitz nicht vorne" 3 "Sitz vorne" ;
VAL_ 1312 AB_Sitzpos_Sens_BF 0 "nicht verfügbar" 1 "Fehler" 2 "Sitz nicht vorne" 3 "Sitz vorne" ;
VAL_ 1312 AB_Wickelklappung_Reihe2_BF 0 "nicht_verbaut" 1 "nicht_verfuegbar__Fehler_oder_Init" 2 "nicht_verriegelt" 3 "verriegelt" ;
VAL_ 1312 AB_Wickelklappung_Reihe2_FA 0 "nicht_verbaut" 1 "nicht_verfuegbar__Fehler_oder_Init" 2 "nicht_verriegelt" 3 "verriegelt" ;
VAL_ 1349 AB_Gurtwarn_Reihe2_FA 0 "nicht_verbaut" 1 "keine_Gurtwarnung_Sitz_leer" 2 "keine_Gurtwarnung_Sitz_belegt" 3 "Gurtwarnung_Sitz_belegt" ;
VAL_ 1349 AB_Gurtwarn_Reihe2_BF 0 "nicht_verbaut" 1 "keine_Gurtwarnung_Sitz_leer" 2 "keine_Gurtwarnung_Sitz_belegt" 3 "Gurtwarnung_Sitz_belegt" ;
VAL_ 1349 AbstWarn_MV_FAS_Fkt_Status 0 "Init" 1 "Funktion_Ist_Ein" 2 "Funktion_Ist_Aus" 3 "Fehler" ;
VAL_ 1349 WarnBrems_Charisma_Status 0 "Init" 1 "verfügbar" 2 "nicht verfügbar" 3 "asynchron durch Fahrerwunsch" ;
VAL_ 1349 WarnBrems_Charisma_FahrPr 0 "keine_Funktion" 1 "Programm_1" 2 "Programm_2" 3 "Programm_3" 4 "Programm_4" 5 "Programm_5" 6 "Programm_6" 7 "Programm_7" 8 "Programm_8" 9 "Programm_9" 10 "Programm_10" 11 "Programm_11" 12 "Programm_12" 13 "Programm_13" 14 "Programm_14" 15 "Programm_15" ;
VAL_ 1349 AB_Gurtwarn_Reihe2_MI 0 "nicht_verbaut" 1 "keine_Gurtwarnung_Sitz_leer" 2 "keine_Gurtwarnung_Sitz_belegt" 3 "Gurtwarnung_Sitz_belegt" ;
VAL_ 1349 AB_Gurtwarn_Reihe3_FA 0 "nicht_verbaut" 1 "keine_Gurtwarnung_Sitz_leer" 2 "keine_Gurtwarnung_Sitz_belegt" 3 "Gurtwarnung_Sitz_belegt" ;
VAL_ 1349 AB_Gurtwarn_Reihe3_MI 0 "nicht_verbaut" 1 "keine_Gurtwarnung_Sitz_leer" 2 "keine_Gurtwarnung_Sitz_belegt" 3 "Gurtwarnung_Sitz_belegt" ;
VAL_ 1349 AB_Gurtwarn_Reihe3_BF 0 "nicht_verbaut" 1 "keine_Gurtwarnung_Sitz_leer" 2 "keine_Gurtwarnung_Sitz_belegt" 3 "Gurtwarnung_Sitz_belegt" ;
VAL_ 1349 LGI_FAS_Fkt_Status 0 "Init" 1 "Funktion_Ist_Ein" 2 "Funktion_Ist_Aus" 3 "Fehler" ;
VAL_ 1349 PreCrash_FAS_Fkt_Status 0 "Init" 1 "Funktion_Ist_Ein" 2 "Funktion_Ist_Aus" 3 "Fehler" ;
VAL_ 1349 AB_SBR_hinten_verbau 0 "ohne_SBR_hinten" 1 "mit_SBR_hinten" 2 "nicht_definiert" 3 "Init" ;
VAL_ 1349 AWV_Einstellung_System_ASG 0 "deaktiviert" 1 "aktiviert" ;
VAL_ 1349 AWV_Einstellung_Warnung_ASG 0 "Aus" 1 "Setting_2" 2 "Setting_3" 3 "Setting_4" 4 "Setting_5" 5 "Ein" ;
VAL_ 1349 SC_PreSense_Modus_Warnung_NV 0 "Aus" 1 "Setting_2" 2 "Setting_3" 3 "Setting_4" 4 "Setting_5" 5 "Ein" ;
VAL_ 1349 SC_PreSense_Modus_Warnung_MV 0 "Aus" 1 "Setting_2" 2 "Setting_3" 3 "Setting_4" 4 "Setting_5" 5 "Ein" ;
VAL_ 1349 SC_PreSense_Modus_System_MV 0 "deaktiviert" 1 "aktiviert" ;
VAL_ 1349 SC_PreSense_Modus_System_NV 0 "deaktiviert" 1 "aktiviert" ;
VAL_ 1349 SC_PreSense_Modus_System_KAS 0 "deaktiviert" 1 "aktiviert" ;
VAL_ 674 ALR_Warnlampe 0 "keine_Warnung" 1 "Warnung" ;
VAL_ 674 ALR_Schalten 0 "keine_Schaltung" 1 "Schaltung_aktiv" ;
VAL_ 674 ALR_Vorwarnung 0 "keine_Schaltung" 1 "Schaltung_wartet" ;
VAL_ 674 ALR_Texte 0 "kein Text" 1 "Text_1" 2 "Text_2" 3 "Text_3" 4 "Text_4" 5 "Text_5" 6 "Text_6" 7 "Text_7" 8 "Text_8" 9 "Text_9" 10 "Text_10" 11 "Text_11" 12 "Text_12" 13 "Text_13" 14 "Text_14" 15 "Text_15" ;
VAL_ 674 ALR_OBD_Status 0 "MIL aus" 1 "MIL ein" ;
VAL_ 674 ALR_Sta_Disconnect 0 "init" 1 "zugeschaltet" 2 "abgeschaltet" 3 "Zuschaltung" 4 "Abschaltung" 5 "Fehler_kein_4WD" 6 "Fehler_kein_2WD" ;
VAL_ 674 ALR_v_Begrenzung 31 "Init_keine_Limitierung" ;
VAL_ 674 ALR_Ist_Proz_Anz 251 "res" 252 "res" 253 "keine_Momentenverteilung" 254 "Init" 255 "Fehler" ;
VAL_ 674 ALR_Charisma_Status 0 "Init" 1 "verfuegbar" 2 "nicht_verfuegbar" 3 "asynchron_durch_Fahrerwunsch" ;
VAL_ 674 ALR_Charisma_FahrPr 0 "keine_Funktion" 1 "Programm_1" 2 "Programm_2" 3 "Programm_3" 4 "Programm_4" 5 "Programm_5" 6 "Programm_6" 7 "Programm_7" 8 "Programm_8" 9 "Programm_9" 10 "Programm_10" 11 "Programm_11" 12 "Programm_12" 13 "Programm_13" 14 "Programm_14" 15 "Programm_15" ;
VAL_ 674 ALR_Kuehlbedarf 0 "kein_Kuehlbedarf" 1 "mittlere_Kuehlbedarf" 2 "maximaler_Kuehlbedarf" 3 "Notfall" ;
VAL_ 1633 AAG_AVS_Fehler_02_inv 0 "Fehler" 1 "kein_Fehler" ;
VAL_ 1633 AAG_Bremsl_durch_ECD 0 "Bremslicht_ist_aus" 1 "Bremslicht_durch_ECD_aktiv" ;
VAL_ 1633 AAG_Anhaenger_abgesteckt 1 "Anhaenger_wurde_bei_KL15_aus_abgesteckt" ;
VAL_ 1633 AAG_NSL_aktiv 0 "Init" 1 "Anhaenger_Nebelschusslicht_aktiv" ;
VAL_ 1633 AAG_Anhaenger_erkannt 0 "kein_Anhaenger_erkannt" 1 "AAG_Anhaenger_erkannt" ;
VAL_ 1633 AAG_Blinker_H_aktiv 0 "Init" 1 "Anhaenger_Blinker_aktiv" ;
VAL_ 1633 AAG_Blinker_HL_def 0 "Init" 1 "Anhaenger_Blinker_links_defekt" ;
VAL_ 1633 AAG_Blinker_HR_def 0 "Init" 1 "Anhaenger_Blinker_rechts_defekt" ;
VAL_ 1633 AAG_Bremslicht_H_def 0 "Init" 1 "Anhaenger_Bremslicht_defekt" ;
VAL_ 1633 AAG_Schlusslicht_HL_def 0 "Init" 1 "Anhaenger_Schlusslicht_links_defekt" ;
VAL_ 1633 AAG_Schlusslicht_HR_def 0 "Init" 1 "Anhaenger_Schlusslicht_rechts_defekt" ;
VAL_ 1633 AAG_Bremslicht_Reku 0 "inaktiv" 1 "aktiv" ;
VAL_ 1633 AAG_AVS_Fehler_02 0 "kein_Fehler" 1 "Fehler" ;
VAL_ 1633 AAG_LED_aktiv 0 "Lampen" 1 "LED" ;
VAL_ 1633 AAG_AVS_Stati 0 "endlage_eingefahren_erreicht" 1 "endlage_ausgefahren_erreicht" 2 "ausfahren_automatik" 3 "einfahren_automatik" 4 "ausfahren_manuell" 5 "einfahren_manuell" 6 "zwischenposition" 7 "nicht_initialisiert" ;
VAL_ 345 ARA_Knickwinkel_Konfidenz 126 "Init" 127 "Fehler" ;
VAL_ 345 ARA_Texte 0 "kein Text/Akustik" 63 "Fehler" ;
VAL_ 345 ARA_Modus 0 "Knickwinkelmodus" 1 "Trajektorienmodus" ;
VAL_ 345 ARA_Aktiver_Grafikmodus 0 "keine_Grafik" 1 "Grafikmodus_aktiv" ;
VAL_ 345 ARA_Deaktivierung_sperren 0 "nicht_gesperrt" 1 "gesperrt" ;
VAL_ 345 ARA_Modus_Anf 0 "ARA Modus nicht im TSG angefordert" 1 "ARA Modus im TSG angefordert" ;
VAL_ 345 ARA_Bremsfuss 0 "kein Bremsfuss" 1 "Bremsfuss angefordert" ;
VAL_ 345 ARA_Sensor_Aktivierung 0 "Knickwinkelsensor_deaktivieren" 1 "Knickwinkelsensor_aktivieren" ;
VAL_ 345 ARA_Knickwinkel_Komfort 62 "Init" 63 "Fehler" ;
VAL_ 345 ARA_Status 0 "ARA_Status_inaktiv" 1 "ARA_Status_init" 2 "Fehler" 3 "ARA_Status_Start" 4 "ARA_Status_aktiv" 6 "ARA_Status_Regelung_aktiv" 8 "ARA_Status_betriebsbereit" 9 "ARA_Status_Klemmtraeger_erkannt" 10 "ARA_Status_Abbruch" 11 "ARA_Status_nicht_betriebsbereit" ;
VAL_ 345 ARA_Knickwinkel_Max 126 "Init" 127 "Fehler" ;
VAL_ 345 ARA_Knickwinkel_Soll 254 "Init" 255 "Fehler" ;
VAL_ 345 ARA_Knickwinkel_Ist 254 "Init" 255 "Fehler" ;
VAL_ 893 ASTA_Stuetzlast 510 "Init" 511 "Fehler" ;
VAL_ 893 ASTA_Einheit 0 "kg" 1 "lbs" 2 "reserviert" 3 "Fehler" ;
VAL_ 893 ASTA_Anhaengerlast 8190 "Init" 8191 "Fehler" ;
VAL_ 893 AAG_ASTA_Status 0 "kein_Fehler" 1 "Fehler" ;
VAL_ 893 ASTAs_01_upd 0 "nicht_aktuell" 1 "aktuell" ;
VAL_ 2589283618 AWC_Fehler_zMover 0 "kein_Fehler" 1 "Fehler" 2 "Fehler_zMover_ausgefahren" ;
VAL_ 2589283618 AWC_Panel_PositionX 2046 "Init" 2047 "Fehler" ;
VAL_ 2589283618 AWC_Panel_PositionY 2046 "Init" 2047 "Fehler" ;
VAL_ 2589283618 AWC_Panel_Verdrehwinkel 254 "Init" 255 "Fehler" ;
VAL_ 2589283618 AWC_Positionierhilfe 0 "Init" 1 "AWC_Parkhilfe_inaktiv" 2 "AWC_Parkhilfe_aktiv" ;
VAL_ 2589283618 AWC_Ladeoption_Infrastruktur 0 "Keine_Auswahl" 1 "Sofort_Laden" 2 "Timer_Laden" 3 "Ladeende_Kundenwunsch" 7 "Init" ;
VAL_ 2589283618 AWC_Spielschutz 0 "inaktiv" 1 "aktiv" ;
VAL_ 2589283618 AWC_Status 0 "StandbyState" 1 "SearchingState" 2 "FoundState" 3 "EnablingState" 4 "zMoverState" 5 "NormalOperatingState" 6 "ProductionState" 7 "DisabledState" 8 "ServiceState" 14 "Init" 15 "Fehler" ;
VAL_ 2589283618 AWC_Fehler_FOD 0 "keinFehler" 1 "Fehler" ;
VAL_ 2589283618 AWC_Fehler_Kommunikation 0 "kein_Fehler" 1 "Fehler" ;
VAL_ 2589283618 AWC_Fehler_LOP 0 "kein_Fehler" 1 "Fehler" ;
VAL_ 2589283618 AWC_Verzoegerung_FOD 0 "inaktiv" 1 "aktiv" ;
VAL_ 2589283618 AWC_Verzoegerung_LOP 0 "inaktiv" 1 "aktiv" ;
VAL_ 2589283618 AWC_Verzoegerung_Temp 0 "inaktiv" 1 "aktiv" ;
VAL_ 2589283618 AWC_Verzoegerung_zMover 0 "inaktiv" 1 "aktiv" ;
